VERSION ""

NS_ :

BS_:

BU_: WCM4 WCM3 WCM2 WCM VPM VLM VKM VICM VECM VDM VCU_RTOS_ETH VCU_ENTRY_ETH VCU_AGVM_ETH VCU UVM UPM TIM TEST_TOOL_1 TCP_ETH TCP TCM TCCM SRR_SRR_ETH SRR_SRR SRR_SLR_ETH SRR_SLR SRR_RR SRR_RF_ETH SRR_RF SRR_LR_CR SRR_LF_ETH SRR_LF SIB SDM SCL SBZA_R SBZA_L SBM SAM_RR SAM_RF SAM_LR SAM_LF SAM_BH SADS RadioLow_ETH RadioLow RSI_RTOS_ETH RSI RDCM PTM PLCM PFCM PDR_ETH PDR PCM PA ODS2 ODS NVM MTCM_R MTCM_L MSM_RR MSM_P MSM_LR MSM_D MSB2 MSB1 MRCM_R MRCM_L MFC LRR_RR_ETH LRR_LR_ETH LRR_CF_ETH LRR LRL_CF_ETH LIB_48V LIB1 IPC_INT IPC_GP IPC ICS_Info ICCM HVAC_FP_R HVAC_FP_F HUD_CAN HDLM FPI_RTOS_ETH FPI FOPM FCM_LC FCM EPSb EPS_1 EPSRAb EPSRAa EPS EOCM_HC_Superset EOCM_HCP2 EOCM ELM ECP_X1 ECP_S2 ECP_S ECP_MC ECP_H3 ECP_H2 ECP_H1 ECP_E ECM EBCM DMS DEFC DCM CSM_ETH CSM_AV CSM CGM_OTA_ETH CGM BSM_MH BSM_HEV BSM BCM ARS ARB APA AOS AMP ALC AHS AHL_AFL ADIMb ADIMa ACP2_MCU

BO_ 1444 PDU_9194: 8 CGM
 SG_ TrlrTireLFInrPres : 7|8@0+ (4,0) [0|1020] "kPaG" VCU
 SG_ ArflBsdOnOccpFrtPsCstAvlFlg2 : 8|1@0+ (1,0) [0|1] "" VCU
 SG_ ArflBsdOnOccpFrtPsCstAvlFlg1 : 9|1@0+ (1,0) [0|1] "" VCU
 SG_ TrlrTireLFInrPresSts_Inv : 10|1@0+ (1,0) [0|1] "" VCU
 SG_ TrlrTireLFInrPresSts : 14|4@0+ (1,0) [0|8] "" VCU
 SG_ TrlrTireLFInrPres_Inv : 15|1@0+ (1,0) [0|1] "" VCU
 SG_ ArflBsdOnOccpRrPsCstAvlFlg2 : 16|1@0+ (1,0) [0|1] "" VCU
 SG_ ArflBsdOnOccpRrPsCstAvlFlg1 : 17|1@0+ (1,0) [0|1] "" VCU
 SG_ ArflBsdOnOccpFrtPsCstSetAval : 18|1@0+ (1,0) [0|1] "" VCU
 SG_ ArflBsdOnOccpFrtPsCstAvlFlg7 : 19|1@0+ (1,0) [0|1] "" VCU
 SG_ ArflBsdOnOccpFrtPsCstAvlFlg6 : 20|1@0+ (1,0) [0|1] "" VCU
 SG_ ArflBsdOnOccpFrtPsCstAvlFlg5 : 21|1@0+ (1,0) [0|1] "" VCU
 SG_ ArflBsdOnOccpFrtPsCstAvlFlg4 : 22|1@0+ (1,0) [0|1] "" VCU
 SG_ ArflBsdOnOccpFrtPsCstAvlFlg3 : 23|1@0+ (1,0) [0|1] "" VCU
 SG_ AutoAirOtltAmgCstAvlFlg2 : 24|1@0+ (1,0) [0|1] "" VCU
 SG_ AutoAirOtltAmgCstAvlFlg1 : 25|1@0+ (1,0) [0|1] "" VCU
 SG_ ArflBsdOnOccpRrPsCstSetAval : 26|1@0+ (1,0) [0|1] "" VCU
 SG_ ArflBsdOnOccpRrPsCstAvlFlg7 : 27|1@0+ (1,0) [0|1] "" VCU
 SG_ ArflBsdOnOccpRrPsCstAvlFlg6 : 28|1@0+ (1,0) [0|1] "" VCU
 SG_ ArflBsdOnOccpRrPsCstAvlFlg5 : 29|1@0+ (1,0) [0|1] "" VCU
 SG_ ArflBsdOnOccpRrPsCstAvlFlg4 : 30|1@0+ (1,0) [0|1] "" VCU
 SG_ ArflBsdOnOccpRrPsCstAvlFlg3 : 31|1@0+ (1,0) [0|1] "" VCU
 SG_ AutoNckScrfCstAvlFlg2 : 32|1@0+ (1,0) [0|1] "" VCU
 SG_ AutoNckScrfCstAvlFlg1 : 33|1@0+ (1,0) [0|1] "" VCU
 SG_ AutoAirOtltAmgCstSetAval : 34|1@0+ (1,0) [0|1] "" VCU
 SG_ AutoAirOtltAmgCstAvlFlg7 : 35|1@0+ (1,0) [0|1] "" VCU
 SG_ AutoAirOtltAmgCstAvlFlg6 : 36|1@0+ (1,0) [0|1] "" VCU
 SG_ AutoAirOtltAmgCstAvlFlg5 : 37|1@0+ (1,0) [0|1] "" VCU
 SG_ AutoAirOtltAmgCstAvlFlg4 : 38|1@0+ (1,0) [0|1] "" VCU
 SG_ AutoAirOtltAmgCstAvlFlg3 : 39|1@0+ (1,0) [0|1] "" VCU
 SG_ Aux2AmbtAnmCtlCstAvlFlg10 : 40|1@0+ (1,0) [0|1] "" VCU
 SG_ Aux2AmbtAnmCtlCstAvlFlg1 : 41|1@0+ (1,0) [0|1] "" VCU
 SG_ AutoNckScrfCstSetAval : 42|1@0+ (1,0) [0|1] "" VCU
 SG_ AutoNckScrfCstAvlFlg7 : 43|1@0+ (1,0) [0|1] "" VCU
 SG_ AutoNckScrfCstAvlFlg6 : 44|1@0+ (1,0) [0|1] "" VCU
 SG_ AutoNckScrfCstAvlFlg5 : 45|1@0+ (1,0) [0|1] "" VCU
 SG_ AutoNckScrfCstAvlFlg4 : 46|1@0+ (1,0) [0|1] "" VCU
 SG_ AutoNckScrfCstAvlFlg3 : 47|1@0+ (1,0) [0|1] "" VCU
 SG_ SCAPwrDrLckAllVirtCtlRrAllwd : 48|1@0+ (1,0) [0|1] "" VCU
 SG_ SCAPwrDrLckAllVirtCtlFrtAllwd : 49|1@0+ (1,0) [0|1] "" VCU
 SG_ SCAPwrDrLckAllVirtCtlAval : 50|1@0+ (1,0) [0|1] "" VCU
 SG_ DMHrnOutPrkCstSetAval : 51|1@0+ (1,0) [0|1] "" VCU
 SG_ DMDrvrDrUnlckPrkCstSetAval : 52|1@0+ (1,0) [0|1] "" VCU
 SG_ Aux2AmbtColrCtlCstAvlFlg1 : 53|1@0+ (1,0) [0|1] "" VCU
 SG_ Aux2AmbtAnmCtlCstAvlFlg12 : 54|1@0+ (1,0) [0|1] "" VCU
 SG_ Aux2AmbtAnmCtlCstAvlFlg11 : 55|1@0+ (1,0) [0|1] "" VCU
 SG_ IndThrdRowHVACAuto : 56|1@0+ (1,0) [0|1] "" RadioLow,CSM,CSM_AV,VCU
 SG_ IndRrRtHVACAuto : 57|1@0+ (1,0) [0|1] "" RadioLow,CSM,CSM_AV,VCU
 SG_ IndRrLtHVACAuto : 58|1@0+ (1,0) [0|1] "" RadioLow,CSM,CSM_AV,VCU
 SG_ IndFrtRtHVACAuto : 59|1@0+ (1,0) [0|1] "" RadioLow,CSM,CSM_AV,VCU
 SG_ IndFrtLtHVACAuto : 60|1@0+ (1,0) [0|1] "" RadioLow,CSM,CSM_AV,VCU
 SG_ SCAPwrDrUnlckAllVirtCtlRrAllwd : 61|1@0+ (1,0) [0|1] "" VCU
 SG_ SCAPwrDrUnlckAllVirtCtlFrtAllwd : 62|1@0+ (1,0) [0|1] "" VCU
 SG_ SCAPwrDrUnlckAllVirtCtlAval : 63|1@0+ (1,0) [0|1] "" VCU

BO_ 1924 PDU_9195: 8 CGM
 SG_ Aux2AmbtAnmCtlCstAvlFlg6 : 0|1@0+ (1,0) [0|1] "" VCU
 SG_ Aux2AmbtAnmCtlCstAvlFlg5 : 1|1@0+ (1,0) [0|1] "" VCU
 SG_ Aux2AmbtAnmCtlCstAvlFlg4 : 2|1@0+ (1,0) [0|1] "" VCU
 SG_ Aux2AmbtAnmCtlCstAvlFlg3 : 3|1@0+ (1,0) [0|1] "" VCU
 SG_ Aux2AmbtAnmCtlCstAvlFlg2 : 4|1@0+ (1,0) [0|1] "" VCU
 SG_ Aux2AmbtAnmCtlCstAvlFlg15 : 5|1@0+ (1,0) [0|1] "" VCU
 SG_ Aux2AmbtAnmCtlCstAvlFlg14 : 6|1@0+ (1,0) [0|1] "" VCU
 SG_ Aux2AmbtAnmCtlCstAvlFlg13 : 7|1@0+ (1,0) [0|1] "" VCU
 SG_ Aux2AmbtBrghtnsCtlCstAvlFlg4 : 8|1@0+ (1,0) [0|1] "" VCU
 SG_ Aux2AmbtBrghtnsCtlCstAvlFlg3 : 9|1@0+ (1,0) [0|1] "" VCU
 SG_ Aux2AmbtBrghtnsCtlCstAvlFlg2 : 10|1@0+ (1,0) [0|1] "" VCU
 SG_ Aux2AmbtBrghtnsCtlCstAvlFlg1 : 11|1@0+ (1,0) [0|1] "" VCU
 SG_ Aux2AmbtAnmCtlCstSetAval : 12|1@0+ (1,0) [0|1] "" VCU
 SG_ Aux2AmbtAnmCtlCstAvlFlg9 : 13|1@0+ (1,0) [0|1] "" VCU
 SG_ Aux2AmbtAnmCtlCstAvlFlg8 : 14|1@0+ (1,0) [0|1] "" VCU
 SG_ Aux2AmbtAnmCtlCstAvlFlg7 : 15|1@0+ (1,0) [0|1] "" VCU
 SG_ Aux3AmbtColrCtlCstAvlFlg82 : 16|1@0+ (1,0) [0|1] "" VCU
 SG_ Aux3AmbtColrCtlCstAvlFlg81 : 17|1@0+ (1,0) [0|1] "" VCU
 SG_ Aux3AmbtColrCtlCstAvlFlg80 : 18|1@0+ (1,0) [0|1] "" VCU
 SG_ Aux3AmbtColrCtlCstAvlFlg8 : 19|1@0+ (1,0) [0|1] "" VCU
 SG_ Aux2AmbtBrghtnsCtlCstSetAval : 20|1@0+ (1,0) [0|1] "" VCU
 SG_ Aux2AmbtBrghtnsCtlCstAvlFlg7 : 21|1@0+ (1,0) [0|1] "" VCU
 SG_ Aux2AmbtBrghtnsCtlCstAvlFlg6 : 22|1@0+ (1,0) [0|1] "" VCU
 SG_ Aux2AmbtBrghtnsCtlCstAvlFlg5 : 23|1@0+ (1,0) [0|1] "" VCU
 SG_ Aux3AmbtColrCtlCstAvlFlg9 : 24|1@0+ (1,0) [0|1] "" VCU
 SG_ Aux3AmbtColrCtlCstAvlFlg89 : 25|1@0+ (1,0) [0|1] "" VCU
 SG_ Aux3AmbtColrCtlCstAvlFlg88 : 26|1@0+ (1,0) [0|1] "" VCU
 SG_ Aux3AmbtColrCtlCstAvlFlg87 : 27|1@0+ (1,0) [0|1] "" VCU
 SG_ Aux3AmbtColrCtlCstAvlFlg86 : 28|1@0+ (1,0) [0|1] "" VCU
 SG_ Aux3AmbtColrCtlCstAvlFlg85 : 29|1@0+ (1,0) [0|1] "" VCU
 SG_ Aux3AmbtColrCtlCstAvlFlg84 : 30|1@0+ (1,0) [0|1] "" VCU
 SG_ Aux3AmbtColrCtlCstAvlFlg83 : 31|1@0+ (1,0) [0|1] "" VCU
 SG_ Aux3AmbtColrCtlCstAvlFlg97 : 32|1@0+ (1,0) [0|1] "" VCU
 SG_ Aux3AmbtColrCtlCstAvlFlg96 : 33|1@0+ (1,0) [0|1] "" VCU
 SG_ Aux3AmbtColrCtlCstAvlFlg95 : 34|1@0+ (1,0) [0|1] "" VCU
 SG_ Aux3AmbtColrCtlCstAvlFlg94 : 35|1@0+ (1,0) [0|1] "" VCU
 SG_ Aux3AmbtColrCtlCstAvlFlg93 : 36|1@0+ (1,0) [0|1] "" VCU
 SG_ Aux3AmbtColrCtlCstAvlFlg92 : 37|1@0+ (1,0) [0|1] "" VCU
 SG_ Aux3AmbtColrCtlCstAvlFlg91 : 38|1@0+ (1,0) [0|1] "" VCU
 SG_ Aux3AmbtColrCtlCstAvlFlg90 : 39|1@0+ (1,0) [0|1] "" VCU
 SG_ CbnAirClnFltrtnCstAvlFlg5 : 40|1@0+ (1,0) [0|1] "" VCU
 SG_ CbnAirClnFltrtnCstAvlFlg4 : 41|1@0+ (1,0) [0|1] "" VCU
 SG_ CbnAirClnFltrtnCstAvlFlg3 : 42|1@0+ (1,0) [0|1] "" VCU
 SG_ CbnAirClnFltrtnCstAvlFlg2 : 43|1@0+ (1,0) [0|1] "" VCU
 SG_ CbnAirClnFltrtnCstAvlFlg1 : 44|1@0+ (1,0) [0|1] "" VCU
 SG_ Aux3AmbtColrCtlCstSetAval : 45|1@0+ (1,0) [0|1] "" VCU
 SG_ Aux3AmbtColrCtlCstAvlFlg99 : 46|1@0+ (1,0) [0|1] "" VCU
 SG_ Aux3AmbtColrCtlCstAvlFlg98 : 47|1@0+ (1,0) [0|1] "" VCU
 SG_ HtdArmrstSyncCstAvlFlg5 : 48|1@0+ (1,0) [0|1] "" VCU
 SG_ HtdArmrstSyncCstAvlFlg4 : 49|1@0+ (1,0) [0|1] "" VCU
 SG_ HtdArmrstSyncCstAvlFlg3 : 50|1@0+ (1,0) [0|1] "" VCU
 SG_ HtdArmrstSyncCstAvlFlg2 : 51|1@0+ (1,0) [0|1] "" VCU
 SG_ HtdArmrstSyncCstAvlFlg1 : 52|1@0+ (1,0) [0|1] "" VCU
 SG_ CbnAirClnFltrtnCstSetAval : 53|1@0+ (1,0) [0|1] "" VCU
 SG_ CbnAirClnFltrtnCstAvlFlg7 : 54|1@0+ (1,0) [0|1] "" VCU
 SG_ CbnAirClnFltrtnCstAvlFlg6 : 55|1@0+ (1,0) [0|1] "" VCU
 SG_ TnDrvrSpdLimRmtCstCurrSetVal : 58|3@0+ (1,0) [0|2] "" TCP
 SG_ TnDrvrActvRmtCstCurrSetVal : 61|3@0+ (1,0) [0|2] "" TCP
 SG_ HtdArmrstSyncCstAvlFlg7 : 62|1@0+ (1,0) [0|1] "" VCU
 SG_ HtdArmrstSyncCstAvlFlg6 : 63|1@0+ (1,0) [0|1] "" VCU

BO_ 1925 PDU_9196: 8 CGM
 SG_ Aux2AmbtColrCtlCstAvlFlg106 : 0|1@0+ (1,0) [0|1] "" VCU
 SG_ Aux2AmbtColrCtlCstAvlFlg105 : 1|1@0+ (1,0) [0|1] "" VCU
 SG_ Aux2AmbtColrCtlCstAvlFlg104 : 2|1@0+ (1,0) [0|1] "" VCU
 SG_ Aux2AmbtColrCtlCstAvlFlg103 : 3|1@0+ (1,0) [0|1] "" VCU
 SG_ Aux2AmbtColrCtlCstAvlFlg102 : 4|1@0+ (1,0) [0|1] "" VCU
 SG_ Aux2AmbtColrCtlCstAvlFlg101 : 5|1@0+ (1,0) [0|1] "" VCU
 SG_ Aux2AmbtColrCtlCstAvlFlg100 : 6|1@0+ (1,0) [0|1] "" VCU
 SG_ Aux2AmbtColrCtlCstAvlFlg10 : 7|1@0+ (1,0) [0|1] "" VCU
 SG_ Aux2AmbtColrCtlCstAvlFlg113 : 8|1@0+ (1,0) [0|1] "" VCU
 SG_ Aux2AmbtColrCtlCstAvlFlg112 : 9|1@0+ (1,0) [0|1] "" VCU
 SG_ Aux2AmbtColrCtlCstAvlFlg111 : 10|1@0+ (1,0) [0|1] "" VCU
 SG_ Aux2AmbtColrCtlCstAvlFlg110 : 11|1@0+ (1,0) [0|1] "" VCU
 SG_ Aux2AmbtColrCtlCstAvlFlg11 : 12|1@0+ (1,0) [0|1] "" VCU
 SG_ Aux2AmbtColrCtlCstAvlFlg109 : 13|1@0+ (1,0) [0|1] "" VCU
 SG_ Aux2AmbtColrCtlCstAvlFlg108 : 14|1@0+ (1,0) [0|1] "" VCU
 SG_ Aux2AmbtColrCtlCstAvlFlg107 : 15|1@0+ (1,0) [0|1] "" VCU
 SG_ Aux2AmbtColrCtlCstAvlFlg120 : 16|1@0+ (1,0) [0|1] "" VCU
 SG_ Aux2AmbtColrCtlCstAvlFlg12 : 17|1@0+ (1,0) [0|1] "" VCU
 SG_ Aux2AmbtColrCtlCstAvlFlg119 : 18|1@0+ (1,0) [0|1] "" VCU
 SG_ Aux2AmbtColrCtlCstAvlFlg118 : 19|1@0+ (1,0) [0|1] "" VCU
 SG_ Aux2AmbtColrCtlCstAvlFlg117 : 20|1@0+ (1,0) [0|1] "" VCU
 SG_ Aux2AmbtColrCtlCstAvlFlg116 : 21|1@0+ (1,0) [0|1] "" VCU
 SG_ Aux2AmbtColrCtlCstAvlFlg115 : 22|1@0+ (1,0) [0|1] "" VCU
 SG_ Aux2AmbtColrCtlCstAvlFlg114 : 23|1@0+ (1,0) [0|1] "" VCU
 SG_ Aux2AmbtColrCtlCstAvlFlg13 : 24|1@0+ (1,0) [0|1] "" VCU
 SG_ Aux2AmbtColrCtlCstAvlFlg127 : 25|1@0+ (1,0) [0|1] "" VCU
 SG_ Aux2AmbtColrCtlCstAvlFlg126 : 26|1@0+ (1,0) [0|1] "" VCU
 SG_ Aux2AmbtColrCtlCstAvlFlg125 : 27|1@0+ (1,0) [0|1] "" VCU
 SG_ Aux2AmbtColrCtlCstAvlFlg124 : 28|1@0+ (1,0) [0|1] "" VCU
 SG_ Aux2AmbtColrCtlCstAvlFlg123 : 29|1@0+ (1,0) [0|1] "" VCU
 SG_ Aux2AmbtColrCtlCstAvlFlg122 : 30|1@0+ (1,0) [0|1] "" VCU
 SG_ Aux2AmbtColrCtlCstAvlFlg121 : 31|1@0+ (1,0) [0|1] "" VCU
 SG_ Aux2AmbtColrCtlCstAvlFlg20 : 32|1@0+ (1,0) [0|1] "" VCU
 SG_ Aux2AmbtColrCtlCstAvlFlg2 : 33|1@0+ (1,0) [0|1] "" VCU
 SG_ Aux2AmbtColrCtlCstAvlFlg19 : 34|1@0+ (1,0) [0|1] "" VCU
 SG_ Aux2AmbtColrCtlCstAvlFlg18 : 35|1@0+ (1,0) [0|1] "" VCU
 SG_ Aux2AmbtColrCtlCstAvlFlg17 : 36|1@0+ (1,0) [0|1] "" VCU
 SG_ Aux2AmbtColrCtlCstAvlFlg16 : 37|1@0+ (1,0) [0|1] "" VCU
 SG_ Aux2AmbtColrCtlCstAvlFlg15 : 38|1@0+ (1,0) [0|1] "" VCU
 SG_ Aux2AmbtColrCtlCstAvlFlg14 : 39|1@0+ (1,0) [0|1] "" VCU
 SG_ Aux2AmbtColrCtlCstAvlFlg28 : 40|1@0+ (1,0) [0|1] "" VCU
 SG_ Aux2AmbtColrCtlCstAvlFlg27 : 41|1@0+ (1,0) [0|1] "" VCU
 SG_ Aux2AmbtColrCtlCstAvlFlg26 : 42|1@0+ (1,0) [0|1] "" VCU
 SG_ Aux2AmbtColrCtlCstAvlFlg25 : 43|1@0+ (1,0) [0|1] "" VCU
 SG_ Aux2AmbtColrCtlCstAvlFlg24 : 44|1@0+ (1,0) [0|1] "" VCU
 SG_ Aux2AmbtColrCtlCstAvlFlg23 : 45|1@0+ (1,0) [0|1] "" VCU
 SG_ Aux2AmbtColrCtlCstAvlFlg22 : 46|1@0+ (1,0) [0|1] "" VCU
 SG_ Aux2AmbtColrCtlCstAvlFlg21 : 47|1@0+ (1,0) [0|1] "" VCU
 SG_ Aux2AmbtColrCtlCstAvlFlg35 : 48|1@0+ (1,0) [0|1] "" VCU
 SG_ Aux2AmbtColrCtlCstAvlFlg34 : 49|1@0+ (1,0) [0|1] "" VCU
 SG_ Aux2AmbtColrCtlCstAvlFlg33 : 50|1@0+ (1,0) [0|1] "" VCU
 SG_ Aux2AmbtColrCtlCstAvlFlg32 : 51|1@0+ (1,0) [0|1] "" VCU
 SG_ Aux2AmbtColrCtlCstAvlFlg31 : 52|1@0+ (1,0) [0|1] "" VCU
 SG_ Aux2AmbtColrCtlCstAvlFlg30 : 53|1@0+ (1,0) [0|1] "" VCU
 SG_ Aux2AmbtColrCtlCstAvlFlg3 : 54|1@0+ (1,0) [0|1] "" VCU
 SG_ Aux2AmbtColrCtlCstAvlFlg29 : 55|1@0+ (1,0) [0|1] "" VCU
 SG_ Aux2AmbtColrCtlCstAvlFlg42 : 56|1@0+ (1,0) [0|1] "" VCU
 SG_ Aux2AmbtColrCtlCstAvlFlg41 : 57|1@0+ (1,0) [0|1] "" VCU
 SG_ Aux2AmbtColrCtlCstAvlFlg40 : 58|1@0+ (1,0) [0|1] "" VCU
 SG_ Aux2AmbtColrCtlCstAvlFlg4 : 59|1@0+ (1,0) [0|1] "" VCU
 SG_ Aux2AmbtColrCtlCstAvlFlg39 : 60|1@0+ (1,0) [0|1] "" VCU
 SG_ Aux2AmbtColrCtlCstAvlFlg38 : 61|1@0+ (1,0) [0|1] "" VCU
 SG_ Aux2AmbtColrCtlCstAvlFlg37 : 62|1@0+ (1,0) [0|1] "" VCU
 SG_ Aux2AmbtColrCtlCstAvlFlg36 : 63|1@0+ (1,0) [0|1] "" VCU

BO_ 1926 PDU_9197: 8 CGM
 SG_ Aux2AmbtColrCtlCstAvlFlg5 : 0|1@0+ (1,0) [0|1] "" VCU
 SG_ Aux2AmbtColrCtlCstAvlFlg49 : 1|1@0+ (1,0) [0|1] "" VCU
 SG_ Aux2AmbtColrCtlCstAvlFlg48 : 2|1@0+ (1,0) [0|1] "" VCU
 SG_ Aux2AmbtColrCtlCstAvlFlg47 : 3|1@0+ (1,0) [0|1] "" VCU
 SG_ Aux2AmbtColrCtlCstAvlFlg46 : 4|1@0+ (1,0) [0|1] "" VCU
 SG_ Aux2AmbtColrCtlCstAvlFlg45 : 5|1@0+ (1,0) [0|1] "" VCU
 SG_ Aux2AmbtColrCtlCstAvlFlg44 : 6|1@0+ (1,0) [0|1] "" VCU
 SG_ Aux2AmbtColrCtlCstAvlFlg43 : 7|1@0+ (1,0) [0|1] "" VCU
 SG_ Aux2AmbtColrCtlCstAvlFlg57 : 8|1@0+ (1,0) [0|1] "" VCU
 SG_ Aux2AmbtColrCtlCstAvlFlg56 : 9|1@0+ (1,0) [0|1] "" VCU
 SG_ Aux2AmbtColrCtlCstAvlFlg55 : 10|1@0+ (1,0) [0|1] "" VCU
 SG_ Aux2AmbtColrCtlCstAvlFlg54 : 11|1@0+ (1,0) [0|1] "" VCU
 SG_ Aux2AmbtColrCtlCstAvlFlg53 : 12|1@0+ (1,0) [0|1] "" VCU
 SG_ Aux2AmbtColrCtlCstAvlFlg52 : 13|1@0+ (1,0) [0|1] "" VCU
 SG_ Aux2AmbtColrCtlCstAvlFlg51 : 14|1@0+ (1,0) [0|1] "" VCU
 SG_ Aux2AmbtColrCtlCstAvlFlg50 : 15|1@0+ (1,0) [0|1] "" VCU
 SG_ Aux2AmbtColrCtlCstAvlFlg64 : 16|1@0+ (1,0) [0|1] "" VCU
 SG_ Aux2AmbtColrCtlCstAvlFlg63 : 17|1@0+ (1,0) [0|1] "" VCU
 SG_ Aux2AmbtColrCtlCstAvlFlg62 : 18|1@0+ (1,0) [0|1] "" VCU
 SG_ Aux2AmbtColrCtlCstAvlFlg61 : 19|1@0+ (1,0) [0|1] "" VCU
 SG_ Aux2AmbtColrCtlCstAvlFlg60 : 20|1@0+ (1,0) [0|1] "" VCU
 SG_ Aux2AmbtColrCtlCstAvlFlg6 : 21|1@0+ (1,0) [0|1] "" VCU
 SG_ Aux2AmbtColrCtlCstAvlFlg59 : 22|1@0+ (1,0) [0|1] "" VCU
 SG_ Aux2AmbtColrCtlCstAvlFlg58 : 23|1@0+ (1,0) [0|1] "" VCU
 SG_ Aux2AmbtColrCtlCstAvlFlg71 : 24|1@0+ (1,0) [0|1] "" VCU
 SG_ Aux2AmbtColrCtlCstAvlFlg70 : 25|1@0+ (1,0) [0|1] "" VCU
 SG_ Aux2AmbtColrCtlCstAvlFlg7 : 26|1@0+ (1,0) [0|1] "" VCU
 SG_ Aux2AmbtColrCtlCstAvlFlg69 : 27|1@0+ (1,0) [0|1] "" VCU
 SG_ Aux2AmbtColrCtlCstAvlFlg68 : 28|1@0+ (1,0) [0|1] "" VCU
 SG_ Aux2AmbtColrCtlCstAvlFlg67 : 29|1@0+ (1,0) [0|1] "" VCU
 SG_ Aux2AmbtColrCtlCstAvlFlg66 : 30|1@0+ (1,0) [0|1] "" VCU
 SG_ Aux2AmbtColrCtlCstAvlFlg65 : 31|1@0+ (1,0) [0|1] "" VCU
 SG_ Aux2AmbtColrCtlCstAvlFlg79 : 32|1@0+ (1,0) [0|1] "" VCU
 SG_ Aux2AmbtColrCtlCstAvlFlg78 : 33|1@0+ (1,0) [0|1] "" VCU
 SG_ Aux2AmbtColrCtlCstAvlFlg77 : 34|1@0+ (1,0) [0|1] "" VCU
 SG_ Aux2AmbtColrCtlCstAvlFlg76 : 35|1@0+ (1,0) [0|1] "" VCU
 SG_ Aux2AmbtColrCtlCstAvlFlg75 : 36|1@0+ (1,0) [0|1] "" VCU
 SG_ Aux2AmbtColrCtlCstAvlFlg74 : 37|1@0+ (1,0) [0|1] "" VCU
 SG_ Aux2AmbtColrCtlCstAvlFlg73 : 38|1@0+ (1,0) [0|1] "" VCU
 SG_ Aux2AmbtColrCtlCstAvlFlg72 : 39|1@0+ (1,0) [0|1] "" VCU
 SG_ Aux2AmbtColrCtlCstAvlFlg86 : 40|1@0+ (1,0) [0|1] "" VCU
 SG_ Aux2AmbtColrCtlCstAvlFlg85 : 41|1@0+ (1,0) [0|1] "" VCU
 SG_ Aux2AmbtColrCtlCstAvlFlg84 : 42|1@0+ (1,0) [0|1] "" VCU
 SG_ Aux2AmbtColrCtlCstAvlFlg83 : 43|1@0+ (1,0) [0|1] "" VCU
 SG_ Aux2AmbtColrCtlCstAvlFlg82 : 44|1@0+ (1,0) [0|1] "" VCU
 SG_ Aux2AmbtColrCtlCstAvlFlg81 : 45|1@0+ (1,0) [0|1] "" VCU
 SG_ Aux2AmbtColrCtlCstAvlFlg80 : 46|1@0+ (1,0) [0|1] "" VCU
 SG_ Aux2AmbtColrCtlCstAvlFlg8 : 47|1@0+ (1,0) [0|1] "" VCU
 SG_ Aux2AmbtColrCtlCstAvlFlg93 : 48|1@0+ (1,0) [0|1] "" VCU
 SG_ Aux2AmbtColrCtlCstAvlFlg92 : 49|1@0+ (1,0) [0|1] "" VCU
 SG_ Aux2AmbtColrCtlCstAvlFlg91 : 50|1@0+ (1,0) [0|1] "" VCU
 SG_ Aux2AmbtColrCtlCstAvlFlg90 : 51|1@0+ (1,0) [0|1] "" VCU
 SG_ Aux2AmbtColrCtlCstAvlFlg9 : 52|1@0+ (1,0) [0|1] "" VCU
 SG_ Aux2AmbtColrCtlCstAvlFlg89 : 53|1@0+ (1,0) [0|1] "" VCU
 SG_ Aux2AmbtColrCtlCstAvlFlg88 : 54|1@0+ (1,0) [0|1] "" VCU
 SG_ Aux2AmbtColrCtlCstAvlFlg87 : 55|1@0+ (1,0) [0|1] "" VCU
 SG_ Aux3AmbtAnmCtlCstAvlFlg1 : 56|1@0+ (1,0) [0|1] "" VCU
 SG_ Aux2AmbtColrCtlCstSetAval : 57|1@0+ (1,0) [0|1] "" VCU
 SG_ Aux2AmbtColrCtlCstAvlFlg99 : 58|1@0+ (1,0) [0|1] "" VCU
 SG_ Aux2AmbtColrCtlCstAvlFlg98 : 59|1@0+ (1,0) [0|1] "" VCU
 SG_ Aux2AmbtColrCtlCstAvlFlg97 : 60|1@0+ (1,0) [0|1] "" VCU
 SG_ Aux2AmbtColrCtlCstAvlFlg96 : 61|1@0+ (1,0) [0|1] "" VCU
 SG_ Aux2AmbtColrCtlCstAvlFlg95 : 62|1@0+ (1,0) [0|1] "" VCU
 SG_ Aux2AmbtColrCtlCstAvlFlg94 : 63|1@0+ (1,0) [0|1] "" VCU

BO_ 1132 PDU_9198: 8 CGM
 SG_ Aux3AmbtAnmCtlCstAvlFlg3 : 0|1@0+ (1,0) [0|1] "" VCU
 SG_ Aux3AmbtAnmCtlCstAvlFlg2 : 1|1@0+ (1,0) [0|1] "" VCU
 SG_ Aux3AmbtAnmCtlCstAvlFlg15 : 2|1@0+ (1,0) [0|1] "" VCU
 SG_ Aux3AmbtAnmCtlCstAvlFlg14 : 3|1@0+ (1,0) [0|1] "" VCU
 SG_ Aux3AmbtAnmCtlCstAvlFlg13 : 4|1@0+ (1,0) [0|1] "" VCU
 SG_ Aux3AmbtAnmCtlCstAvlFlg12 : 5|1@0+ (1,0) [0|1] "" VCU
 SG_ Aux3AmbtAnmCtlCstAvlFlg11 : 6|1@0+ (1,0) [0|1] "" VCU
 SG_ Aux3AmbtAnmCtlCstAvlFlg10 : 7|1@0+ (1,0) [0|1] "" VCU
 SG_ Aux3AmbtBrghtnsCtlCstAvlFlg1 : 8|1@0+ (1,0) [0|1] "" VCU
 SG_ Aux3AmbtAnmCtlCstSetAval : 9|1@0+ (1,0) [0|1] "" VCU
 SG_ Aux3AmbtAnmCtlCstAvlFlg9 : 10|1@0+ (1,0) [0|1] "" VCU
 SG_ Aux3AmbtAnmCtlCstAvlFlg8 : 11|1@0+ (1,0) [0|1] "" VCU
 SG_ Aux3AmbtAnmCtlCstAvlFlg7 : 12|1@0+ (1,0) [0|1] "" VCU
 SG_ Aux3AmbtAnmCtlCstAvlFlg6 : 13|1@0+ (1,0) [0|1] "" VCU
 SG_ Aux3AmbtAnmCtlCstAvlFlg5 : 14|1@0+ (1,0) [0|1] "" VCU
 SG_ Aux3AmbtAnmCtlCstAvlFlg4 : 15|1@0+ (1,0) [0|1] "" VCU
 SG_ Aux3AmbtColrCtlCstAvlFlg1 : 16|1@0+ (1,0) [0|1] "" VCU
 SG_ Aux3AmbtBrghtnsCtlCstSetAval : 17|1@0+ (1,0) [0|1] "" VCU
 SG_ Aux3AmbtBrghtnsCtlCstAvlFlg7 : 18|1@0+ (1,0) [0|1] "" VCU
 SG_ Aux3AmbtBrghtnsCtlCstAvlFlg6 : 19|1@0+ (1,0) [0|1] "" VCU
 SG_ Aux3AmbtBrghtnsCtlCstAvlFlg5 : 20|1@0+ (1,0) [0|1] "" VCU
 SG_ Aux3AmbtBrghtnsCtlCstAvlFlg4 : 21|1@0+ (1,0) [0|1] "" VCU
 SG_ Aux3AmbtBrghtnsCtlCstAvlFlg3 : 22|1@0+ (1,0) [0|1] "" VCU
 SG_ Aux3AmbtBrghtnsCtlCstAvlFlg2 : 23|1@0+ (1,0) [0|1] "" VCU
 SG_ Aux3AmbtColrCtlCstAvlFlg106 : 24|1@0+ (1,0) [0|1] "" VCU
 SG_ Aux3AmbtColrCtlCstAvlFlg105 : 25|1@0+ (1,0) [0|1] "" VCU
 SG_ Aux3AmbtColrCtlCstAvlFlg104 : 26|1@0+ (1,0) [0|1] "" VCU
 SG_ Aux3AmbtColrCtlCstAvlFlg103 : 27|1@0+ (1,0) [0|1] "" VCU
 SG_ Aux3AmbtColrCtlCstAvlFlg102 : 28|1@0+ (1,0) [0|1] "" VCU
 SG_ Aux3AmbtColrCtlCstAvlFlg101 : 29|1@0+ (1,0) [0|1] "" VCU
 SG_ Aux3AmbtColrCtlCstAvlFlg100 : 30|1@0+ (1,0) [0|1] "" VCU
 SG_ Aux3AmbtColrCtlCstAvlFlg10 : 31|1@0+ (1,0) [0|1] "" VCU
 SG_ Aux3AmbtColrCtlCstAvlFlg113 : 32|1@0+ (1,0) [0|1] "" VCU
 SG_ Aux3AmbtColrCtlCstAvlFlg112 : 33|1@0+ (1,0) [0|1] "" VCU
 SG_ Aux3AmbtColrCtlCstAvlFlg111 : 34|1@0+ (1,0) [0|1] "" VCU
 SG_ Aux3AmbtColrCtlCstAvlFlg110 : 35|1@0+ (1,0) [0|1] "" VCU
 SG_ Aux3AmbtColrCtlCstAvlFlg11 : 36|1@0+ (1,0) [0|1] "" VCU
 SG_ Aux3AmbtColrCtlCstAvlFlg109 : 37|1@0+ (1,0) [0|1] "" VCU
 SG_ Aux3AmbtColrCtlCstAvlFlg108 : 38|1@0+ (1,0) [0|1] "" VCU
 SG_ Aux3AmbtColrCtlCstAvlFlg107 : 39|1@0+ (1,0) [0|1] "" VCU
 SG_ Aux3AmbtColrCtlCstAvlFlg120 : 40|1@0+ (1,0) [0|1] "" VCU
 SG_ Aux3AmbtColrCtlCstAvlFlg12 : 41|1@0+ (1,0) [0|1] "" VCU
 SG_ Aux3AmbtColrCtlCstAvlFlg119 : 42|1@0+ (1,0) [0|1] "" VCU
 SG_ Aux3AmbtColrCtlCstAvlFlg118 : 43|1@0+ (1,0) [0|1] "" VCU
 SG_ Aux3AmbtColrCtlCstAvlFlg117 : 44|1@0+ (1,0) [0|1] "" VCU
 SG_ Aux3AmbtColrCtlCstAvlFlg116 : 45|1@0+ (1,0) [0|1] "" VCU
 SG_ Aux3AmbtColrCtlCstAvlFlg115 : 46|1@0+ (1,0) [0|1] "" VCU
 SG_ Aux3AmbtColrCtlCstAvlFlg114 : 47|1@0+ (1,0) [0|1] "" VCU
 SG_ Aux3AmbtColrCtlCstAvlFlg13 : 48|1@0+ (1,0) [0|1] "" VCU
 SG_ Aux3AmbtColrCtlCstAvlFlg127 : 49|1@0+ (1,0) [0|1] "" VCU
 SG_ Aux3AmbtColrCtlCstAvlFlg126 : 50|1@0+ (1,0) [0|1] "" VCU
 SG_ Aux3AmbtColrCtlCstAvlFlg125 : 51|1@0+ (1,0) [0|1] "" VCU
 SG_ Aux3AmbtColrCtlCstAvlFlg124 : 52|1@0+ (1,0) [0|1] "" VCU
 SG_ Aux3AmbtColrCtlCstAvlFlg123 : 53|1@0+ (1,0) [0|1] "" VCU
 SG_ Aux3AmbtColrCtlCstAvlFlg122 : 54|1@0+ (1,0) [0|1] "" VCU
 SG_ Aux3AmbtColrCtlCstAvlFlg121 : 55|1@0+ (1,0) [0|1] "" VCU
 SG_ Aux3AmbtColrCtlCstAvlFlg20 : 56|1@0+ (1,0) [0|1] "" VCU
 SG_ Aux3AmbtColrCtlCstAvlFlg2 : 57|1@0+ (1,0) [0|1] "" VCU
 SG_ Aux3AmbtColrCtlCstAvlFlg19 : 58|1@0+ (1,0) [0|1] "" VCU
 SG_ Aux3AmbtColrCtlCstAvlFlg18 : 59|1@0+ (1,0) [0|1] "" VCU
 SG_ Aux3AmbtColrCtlCstAvlFlg17 : 60|1@0+ (1,0) [0|1] "" VCU
 SG_ Aux3AmbtColrCtlCstAvlFlg16 : 61|1@0+ (1,0) [0|1] "" VCU
 SG_ Aux3AmbtColrCtlCstAvlFlg15 : 62|1@0+ (1,0) [0|1] "" VCU
 SG_ Aux3AmbtColrCtlCstAvlFlg14 : 63|1@0+ (1,0) [0|1] "" VCU

BO_ 1935 PDU_9199: 8 CGM
 SG_ Aux3AmbtColrCtlCstAvlFlg28 : 0|1@0+ (1,0) [0|1] "" VCU
 SG_ Aux3AmbtColrCtlCstAvlFlg27 : 1|1@0+ (1,0) [0|1] "" VCU
 SG_ Aux3AmbtColrCtlCstAvlFlg26 : 2|1@0+ (1,0) [0|1] "" VCU
 SG_ Aux3AmbtColrCtlCstAvlFlg25 : 3|1@0+ (1,0) [0|1] "" VCU
 SG_ Aux3AmbtColrCtlCstAvlFlg24 : 4|1@0+ (1,0) [0|1] "" VCU
 SG_ Aux3AmbtColrCtlCstAvlFlg23 : 5|1@0+ (1,0) [0|1] "" VCU
 SG_ Aux3AmbtColrCtlCstAvlFlg22 : 6|1@0+ (1,0) [0|1] "" VCU
 SG_ Aux3AmbtColrCtlCstAvlFlg21 : 7|1@0+ (1,0) [0|1] "" VCU
 SG_ Aux3AmbtColrCtlCstAvlFlg35 : 8|1@0+ (1,0) [0|1] "" VCU
 SG_ Aux3AmbtColrCtlCstAvlFlg34 : 9|1@0+ (1,0) [0|1] "" VCU
 SG_ Aux3AmbtColrCtlCstAvlFlg33 : 10|1@0+ (1,0) [0|1] "" VCU
 SG_ Aux3AmbtColrCtlCstAvlFlg32 : 11|1@0+ (1,0) [0|1] "" VCU
 SG_ Aux3AmbtColrCtlCstAvlFlg31 : 12|1@0+ (1,0) [0|1] "" VCU
 SG_ Aux3AmbtColrCtlCstAvlFlg30 : 13|1@0+ (1,0) [0|1] "" VCU
 SG_ Aux3AmbtColrCtlCstAvlFlg3 : 14|1@0+ (1,0) [0|1] "" VCU
 SG_ Aux3AmbtColrCtlCstAvlFlg29 : 15|1@0+ (1,0) [0|1] "" VCU
 SG_ Aux3AmbtColrCtlCstAvlFlg42 : 16|1@0+ (1,0) [0|1] "" VCU
 SG_ Aux3AmbtColrCtlCstAvlFlg41 : 17|1@0+ (1,0) [0|1] "" VCU
 SG_ Aux3AmbtColrCtlCstAvlFlg40 : 18|1@0+ (1,0) [0|1] "" VCU
 SG_ Aux3AmbtColrCtlCstAvlFlg4 : 19|1@0+ (1,0) [0|1] "" VCU
 SG_ Aux3AmbtColrCtlCstAvlFlg39 : 20|1@0+ (1,0) [0|1] "" VCU
 SG_ Aux3AmbtColrCtlCstAvlFlg38 : 21|1@0+ (1,0) [0|1] "" VCU
 SG_ Aux3AmbtColrCtlCstAvlFlg37 : 22|1@0+ (1,0) [0|1] "" VCU
 SG_ Aux3AmbtColrCtlCstAvlFlg36 : 23|1@0+ (1,0) [0|1] "" VCU
 SG_ Aux3AmbtColrCtlCstAvlFlg5 : 24|1@0+ (1,0) [0|1] "" VCU
 SG_ Aux3AmbtColrCtlCstAvlFlg49 : 25|1@0+ (1,0) [0|1] "" VCU
 SG_ Aux3AmbtColrCtlCstAvlFlg48 : 26|1@0+ (1,0) [0|1] "" VCU
 SG_ Aux3AmbtColrCtlCstAvlFlg47 : 27|1@0+ (1,0) [0|1] "" VCU
 SG_ Aux3AmbtColrCtlCstAvlFlg46 : 28|1@0+ (1,0) [0|1] "" VCU
 SG_ Aux3AmbtColrCtlCstAvlFlg45 : 29|1@0+ (1,0) [0|1] "" VCU
 SG_ Aux3AmbtColrCtlCstAvlFlg44 : 30|1@0+ (1,0) [0|1] "" VCU
 SG_ Aux3AmbtColrCtlCstAvlFlg43 : 31|1@0+ (1,0) [0|1] "" VCU
 SG_ Aux3AmbtColrCtlCstAvlFlg57 : 32|1@0+ (1,0) [0|1] "" VCU
 SG_ Aux3AmbtColrCtlCstAvlFlg56 : 33|1@0+ (1,0) [0|1] "" VCU
 SG_ Aux3AmbtColrCtlCstAvlFlg55 : 34|1@0+ (1,0) [0|1] "" VCU
 SG_ Aux3AmbtColrCtlCstAvlFlg54 : 35|1@0+ (1,0) [0|1] "" VCU
 SG_ Aux3AmbtColrCtlCstAvlFlg53 : 36|1@0+ (1,0) [0|1] "" VCU
 SG_ Aux3AmbtColrCtlCstAvlFlg52 : 37|1@0+ (1,0) [0|1] "" VCU
 SG_ Aux3AmbtColrCtlCstAvlFlg51 : 38|1@0+ (1,0) [0|1] "" VCU
 SG_ Aux3AmbtColrCtlCstAvlFlg50 : 39|1@0+ (1,0) [0|1] "" VCU
 SG_ Aux3AmbtColrCtlCstAvlFlg64 : 40|1@0+ (1,0) [0|1] "" VCU
 SG_ Aux3AmbtColrCtlCstAvlFlg63 : 41|1@0+ (1,0) [0|1] "" VCU
 SG_ Aux3AmbtColrCtlCstAvlFlg62 : 42|1@0+ (1,0) [0|1] "" VCU
 SG_ Aux3AmbtColrCtlCstAvlFlg61 : 43|1@0+ (1,0) [0|1] "" VCU
 SG_ Aux3AmbtColrCtlCstAvlFlg60 : 44|1@0+ (1,0) [0|1] "" VCU
 SG_ Aux3AmbtColrCtlCstAvlFlg6 : 45|1@0+ (1,0) [0|1] "" VCU
 SG_ Aux3AmbtColrCtlCstAvlFlg59 : 46|1@0+ (1,0) [0|1] "" VCU
 SG_ Aux3AmbtColrCtlCstAvlFlg58 : 47|1@0+ (1,0) [0|1] "" VCU
 SG_ Aux3AmbtColrCtlCstAvlFlg71 : 48|1@0+ (1,0) [0|1] "" VCU
 SG_ Aux3AmbtColrCtlCstAvlFlg70 : 49|1@0+ (1,0) [0|1] "" VCU
 SG_ Aux3AmbtColrCtlCstAvlFlg7 : 50|1@0+ (1,0) [0|1] "" VCU
 SG_ Aux3AmbtColrCtlCstAvlFlg69 : 51|1@0+ (1,0) [0|1] "" VCU
 SG_ Aux3AmbtColrCtlCstAvlFlg68 : 52|1@0+ (1,0) [0|1] "" VCU
 SG_ Aux3AmbtColrCtlCstAvlFlg67 : 53|1@0+ (1,0) [0|1] "" VCU
 SG_ Aux3AmbtColrCtlCstAvlFlg66 : 54|1@0+ (1,0) [0|1] "" VCU
 SG_ Aux3AmbtColrCtlCstAvlFlg65 : 55|1@0+ (1,0) [0|1] "" VCU
 SG_ Aux3AmbtColrCtlCstAvlFlg79 : 56|1@0+ (1,0) [0|1] "" VCU
 SG_ Aux3AmbtColrCtlCstAvlFlg78 : 57|1@0+ (1,0) [0|1] "" VCU
 SG_ Aux3AmbtColrCtlCstAvlFlg77 : 58|1@0+ (1,0) [0|1] "" VCU
 SG_ Aux3AmbtColrCtlCstAvlFlg76 : 59|1@0+ (1,0) [0|1] "" VCU
 SG_ Aux3AmbtColrCtlCstAvlFlg75 : 60|1@0+ (1,0) [0|1] "" VCU
 SG_ Aux3AmbtColrCtlCstAvlFlg74 : 61|1@0+ (1,0) [0|1] "" VCU
 SG_ Aux3AmbtColrCtlCstAvlFlg73 : 62|1@0+ (1,0) [0|1] "" VCU
 SG_ Aux3AmbtColrCtlCstAvlFlg72 : 63|1@0+ (1,0) [0|1] "" VCU

BO_ 1952 PDU_9200: 8 CGM
 SG_ DMCabLgtPrkCstCurrSetVal : 1|3@0+ (1,0) [0|2] "" VCU
 SG_ DMBlkhdDrUnltchPrkCstCurrSetVal : 4|3@0+ (1,0) [0|2] "" VCU
 SG_ DMBlkhdDrUnlckPrkCstCurrSetVal : 7|3@0+ (1,0) [0|2] "" VCU
 SG_ DMHrnOutPrkCstCurrSetVal : 8|3@0+ (1,0) [0|2] "" VCU
 SG_ DMDrvrDrUnlckPrkCstCurrSetVal : 11|3@0+ (1,0) [0|2] "" VCU
 SG_ DMCrbsdDrUnlckPrkCstCurrSetVal : 14|3@0+ (1,0) [0|2] "" VCU
 SG_ DMBlkhdDrUnlckPrkCstAvlFlg6 : 16|1@0+ (1,0) [0|1] "" VCU
 SG_ DMBlkhdDrUnlckPrkCstAvlFlg5 : 17|1@0+ (1,0) [0|1] "" VCU
 SG_ DMBlkhdDrUnlckPrkCstAvlFlg4 : 18|1@0+ (1,0) [0|1] "" VCU
 SG_ DMBlkhdDrUnlckPrkCstAvlFlg3 : 19|1@0+ (1,0) [0|1] "" VCU
 SG_ DMBlkhdDrUnlckPrkCstAvlFlg2 : 20|1@0+ (1,0) [0|1] "" VCU
 SG_ DMBlkhdDrUnlckPrkCstAvlFlg1 : 21|1@0+ (1,0) [0|1] "" VCU
 SG_ DMBlkhdDrUnltchPrkCstAvlFlg6 : 24|1@0+ (1,0) [0|1] "" VCU
 SG_ DMBlkhdDrUnltchPrkCstAvlFlg5 : 25|1@0+ (1,0) [0|1] "" VCU
 SG_ DMBlkhdDrUnltchPrkCstAvlFlg4 : 26|1@0+ (1,0) [0|1] "" VCU
 SG_ DMBlkhdDrUnltchPrkCstAvlFlg3 : 27|1@0+ (1,0) [0|1] "" VCU
 SG_ DMBlkhdDrUnltchPrkCstAvlFlg2 : 28|1@0+ (1,0) [0|1] "" VCU
 SG_ DMBlkhdDrUnltchPrkCstAvlFlg1 : 29|1@0+ (1,0) [0|1] "" VCU
 SG_ DMBlkhdDrUnlckPrkCstSetAval : 30|1@0+ (1,0) [0|1] "" VCU
 SG_ DMBlkhdDrUnlckPrkCstAvlFlg7 : 31|1@0+ (1,0) [0|1] "" VCU
 SG_ DMCabLgtPrkCstAvlFlg6 : 32|1@0+ (1,0) [0|1] "" VCU
 SG_ DMCabLgtPrkCstAvlFlg5 : 33|1@0+ (1,0) [0|1] "" VCU
 SG_ DMCabLgtPrkCstAvlFlg4 : 34|1@0+ (1,0) [0|1] "" VCU
 SG_ DMCabLgtPrkCstAvlFlg3 : 35|1@0+ (1,0) [0|1] "" VCU
 SG_ DMCabLgtPrkCstAvlFlg2 : 36|1@0+ (1,0) [0|1] "" VCU
 SG_ DMCabLgtPrkCstAvlFlg1 : 37|1@0+ (1,0) [0|1] "" VCU
 SG_ DMBlkhdDrUnltchPrkCstSetAval : 38|1@0+ (1,0) [0|1] "" VCU
 SG_ DMBlkhdDrUnltchPrkCstAvlFlg7 : 39|1@0+ (1,0) [0|1] "" VCU
 SG_ DMCrbsdDrUnlckPrkCstAvlFlg6 : 40|1@0+ (1,0) [0|1] "" VCU
 SG_ DMCrbsdDrUnlckPrkCstAvlFlg5 : 41|1@0+ (1,0) [0|1] "" VCU
 SG_ DMCrbsdDrUnlckPrkCstAvlFlg4 : 42|1@0+ (1,0) [0|1] "" VCU
 SG_ DMCrbsdDrUnlckPrkCstAvlFlg3 : 43|1@0+ (1,0) [0|1] "" VCU
 SG_ DMCrbsdDrUnlckPrkCstAvlFlg2 : 44|1@0+ (1,0) [0|1] "" VCU
 SG_ DMCrbsdDrUnlckPrkCstAvlFlg1 : 45|1@0+ (1,0) [0|1] "" VCU
 SG_ DMCabLgtPrkCstSetAval : 46|1@0+ (1,0) [0|1] "" VCU
 SG_ DMCabLgtPrkCstAvlFlg7 : 47|1@0+ (1,0) [0|1] "" VCU
 SG_ DMDrvrDrUnlckPrkCstAvlFlg6 : 48|1@0+ (1,0) [0|1] "" VCU
 SG_ DMDrvrDrUnlckPrkCstAvlFlg5 : 49|1@0+ (1,0) [0|1] "" VCU
 SG_ DMDrvrDrUnlckPrkCstAvlFlg4 : 50|1@0+ (1,0) [0|1] "" VCU
 SG_ DMDrvrDrUnlckPrkCstAvlFlg3 : 51|1@0+ (1,0) [0|1] "" VCU
 SG_ DMDrvrDrUnlckPrkCstAvlFlg2 : 52|1@0+ (1,0) [0|1] "" VCU
 SG_ DMDrvrDrUnlckPrkCstAvlFlg1 : 53|1@0+ (1,0) [0|1] "" VCU
 SG_ DMCrbsdDrUnlckPrkCstSetAval : 54|1@0+ (1,0) [0|1] "" VCU
 SG_ DMCrbsdDrUnlckPrkCstAvlFlg7 : 55|1@0+ (1,0) [0|1] "" VCU
 SG_ DMHrnOutPrkCstAvlFlg7 : 56|1@0+ (1,0) [0|1] "" VCU
 SG_ DMHrnOutPrkCstAvlFlg6 : 57|1@0+ (1,0) [0|1] "" VCU
 SG_ DMHrnOutPrkCstAvlFlg5 : 58|1@0+ (1,0) [0|1] "" VCU
 SG_ DMHrnOutPrkCstAvlFlg4 : 59|1@0+ (1,0) [0|1] "" VCU
 SG_ DMHrnOutPrkCstAvlFlg3 : 60|1@0+ (1,0) [0|1] "" VCU
 SG_ DMHrnOutPrkCstAvlFlg2 : 61|1@0+ (1,0) [0|1] "" VCU
 SG_ DMHrnOutPrkCstAvlFlg1 : 62|1@0+ (1,0) [0|1] "" VCU
 SG_ DMDrvrDrUnlckPrkCstAvlFlg7 : 63|1@0+ (1,0) [0|1] "" VCU

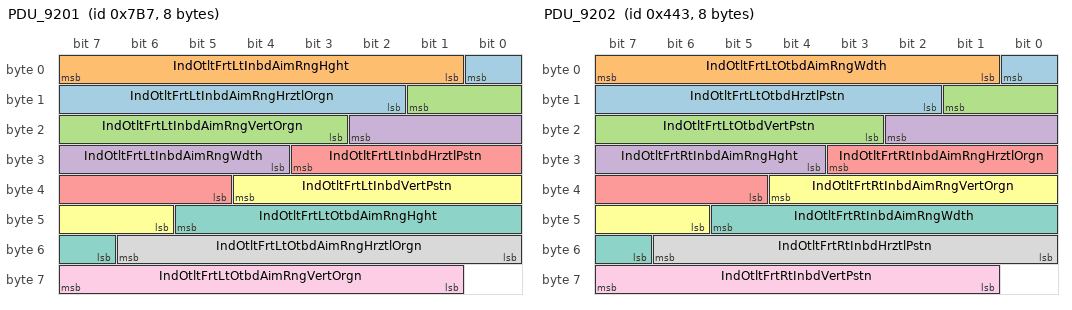
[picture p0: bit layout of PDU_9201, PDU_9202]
BO_ 1975 PDU_9201: 8 CGM
 SG_ IndOtltFrtLtInbdAimRngHrztlOrgn : 0|7@0+ (1,0) [0|127] "%" VCU
 SG_ IndOtltFrtLtInbdAimRngHght : 7|7@0+ (1,0) [0|127] "%" VCU
 SG_ IndOtltFrtLtInbdAimRngVertOrgn : 9|7@0+ (1,0) [0|127] "%" VCU
 SG_ IndOtltFrtLtInbdAimRngWdth : 18|7@0+ (1,0) [0|127] "%" VCU
 SG_ IndOtltFrtLtInbdHrztlPstn : 27|7@0+ (1,0) [0|127] "%" VCU
 SG_ IndOtltFrtLtInbdVertPstn : 36|7@0+ (1,0) [0|127] "%" VCU
 SG_ IndOtltFrtLtOtbdAimRngHght : 45|7@0+ (1,0) [0|127] "%" VCU
 SG_ IndOtltFrtLtOtbdAimRngHrztlOrgn : 54|7@0+ (1,0) [0|127] "%" VCU
 SG_ IndOtltFrtLtOtbdAimRngVertOrgn : 63|7@0+ (1,0) [0|127] "%" VCU

BO_ 1091 PDU_9202: 8 CGM
 SG_ IndOtltFrtLtOtbdHrztlPstn : 0|7@0+ (1,0) [0|127] "%" VCU
 SG_ IndOtltFrtLtOtbdAimRngWdth : 7|7@0+ (1,0) [0|127] "%" VCU
 SG_ IndOtltFrtLtOtbdVertPstn : 9|7@0+ (1,0) [0|127] "%" VCU
 SG_ IndOtltFrtRtInbdAimRngHght : 18|7@0+ (1,0) [0|127] "%" VCU
 SG_ IndOtltFrtRtInbdAimRngHrztlOrgn : 27|7@0+ (1,0) [0|127] "%" VCU
 SG_ IndOtltFrtRtInbdAimRngVertOrgn : 36|7@0+ (1,0) [0|127] "%" VCU
 SG_ IndOtltFrtRtInbdAimRngWdth : 45|7@0+ (1,0) [0|127] "%" VCU
 SG_ IndOtltFrtRtInbdHrztlPstn : 54|7@0+ (1,0) [0|127] "%" VCU
 SG_ IndOtltFrtRtInbdVertPstn : 63|7@0+ (1,0) [0|127] "%" VCU

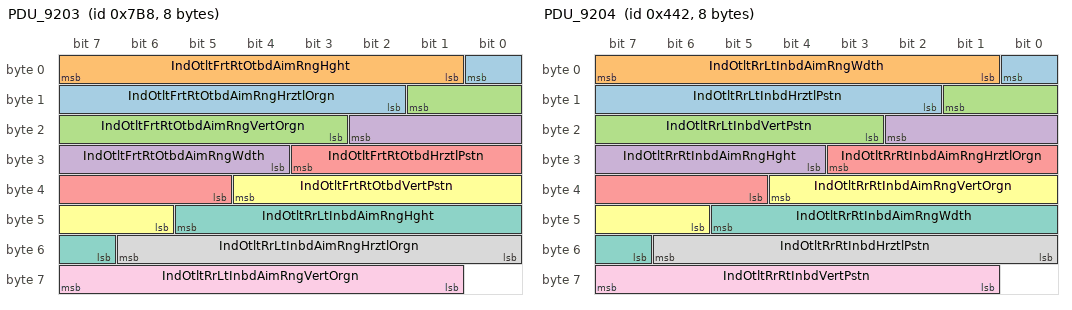
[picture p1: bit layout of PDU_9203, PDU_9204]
BO_ 1976 PDU_9203: 8 CGM
 SG_ IndOtltFrtRtOtbdAimRngHrztlOrgn : 0|7@0+ (1,0) [0|127] "%" VCU
 SG_ IndOtltFrtRtOtbdAimRngHght : 7|7@0+ (1,0) [0|127] "%" VCU
 SG_ IndOtltFrtRtOtbdAimRngVertOrgn : 9|7@0+ (1,0) [0|127] "%" VCU
 SG_ IndOtltFrtRtOtbdAimRngWdth : 18|7@0+ (1,0) [0|127] "%" VCU
 SG_ IndOtltFrtRtOtbdHrztlPstn : 27|7@0+ (1,0) [0|127] "%" VCU
 SG_ IndOtltFrtRtOtbdVertPstn : 36|7@0+ (1,0) [0|127] "%" VCU
 SG_ IndOtltRrLtInbdAimRngHght : 45|7@0+ (1,0) [0|127] "%" VCU
 SG_ IndOtltRrLtInbdAimRngHrztlOrgn : 54|7@0+ (1,0) [0|127] "%" VCU
 SG_ IndOtltRrLtInbdAimRngVertOrgn : 63|7@0+ (1,0) [0|127] "%" VCU

BO_ 1090 PDU_9204: 8 CGM
 SG_ IndOtltRrLtInbdHrztlPstn : 0|7@0+ (1,0) [0|127] "%" VCU
 SG_ IndOtltRrLtInbdAimRngWdth : 7|7@0+ (1,0) [0|127] "%" VCU
 SG_ IndOtltRrLtInbdVertPstn : 9|7@0+ (1,0) [0|127] "%" VCU
 SG_ IndOtltRrRtInbdAimRngHght : 18|7@0+ (1,0) [0|127] "%" VCU
 SG_ IndOtltRrRtInbdAimRngHrztlOrgn : 27|7@0+ (1,0) [0|127] "%" VCU
 SG_ IndOtltRrRtInbdAimRngVertOrgn : 36|7@0+ (1,0) [0|127] "%" VCU
 SG_ IndOtltRrRtInbdAimRngWdth : 45|7@0+ (1,0) [0|127] "%" VCU
 SG_ IndOtltRrRtInbdHrztlPstn : 54|7@0+ (1,0) [0|127] "%" VCU
 SG_ IndOtltRrRtInbdVertPstn : 63|7@0+ (1,0) [0|127] "%" VCU

BO_ 1977 PDU_9205: 8 CGM
 SG_ IndAirDstThrdRw : 0|4@0+ (1,0) [0|8] "" VCU
 SG_ IndTempSetLvlThrdRw : 7|7@0+ (1,0) [0|127] "" VCU
 SG_ IndTempSetStatThrdRw : 8|3@0+ (1,0) [0|4] "" VCU
 SG_ IndBlwSetLvlThrdRw : 12|4@0+ (1,0) [0|15] "" VCU
 SG_ IndBlwSetStatThrdRw : 17|2@0+ (1,0) [0|2] "" VCU
 SG_ IndBlwSetStatRrRt : 19|2@0+ (1,0) [0|2] "" VCU
 SG_ IndBlwSetStatFrtRt : 21|2@0+ (1,0) [0|2] "" VCU
 SG_ IndNckScrfLvlRrRt : 25|2@0+ (1,0) [0|3] "" VCU
 SG_ IndNckScrfLvlRrLt : 27|2@0+ (1,0) [0|3] "" VCU
 SG_ IndNckScrfLvlFrtRt : 29|2@0+ (1,0) [0|3] "" VCU
 SG_ IndNckScrfLvlFrtLt : 31|2@0+ (1,0) [0|3] "" VCU
 SG_ IndOscModeRrRtSet : 33|2@0+ (1,0) [0|2] "" VCU
 SG_ IndOscModeRrLtSet : 35|2@0+ (1,0) [0|2] "" VCU
 SG_ IndOscModeFrtRtSet : 37|2@0+ (1,0) [0|2] "" VCU
 SG_ IndOscModeFrtLtSet : 39|2@0+ (1,0) [0|2] "" VCU
 SG_ IndThrdRwHVACOn : 40|1@0+ (1,0) [0|1] "" VCU
 SG_ IndThrdRwHVACLckd : 41|1@0+ (1,0) [0|1] "" VCU
 SG_ IndSyncThrdRw : 42|1@0+ (1,0) [0|1] "" VCU
 SG_ IndRrRtHVACOn : 43|1@0+ (1,0) [0|1] "" VCU
 SG_ IndRrLtHVACOn : 44|1@0+ (1,0) [0|1] "" VCU
 SG_ IndFrtRtHVACOn : 45|1@0+ (1,0) [0|1] "" VCU
 SG_ IndFrtLtHVACOn : 46|1@0+ (1,0) [0|1] "" VCU
 SG_ IndCkModeOn : 47|1@0+ (1,0) [0|1] "" VCU
 SG_ PwrShdBkGlsShdPs : 48|3@0+ (1,0) [0|5] "" VCU
 SG_ HtdArmrstSyncCstSetAval : 49|1@0+ (1,0) [0|1] "" VCU
 SG_ HtdArmrstSyncCstCurrSetVal : 52|3@0+ (1,0) [0|2] "" VCU
 SG_ ClmCtlThrdRwPwrLtdOpWrnReqActv : 53|1@0+ (1,0) [0|1] "" VCU
 SG_ IndZnUncpdRrSt : 54|1@0+ (1,0) [0|1] "" VCU
 SG_ IndZnUncpdFrtPsngr : 55|1@0+ (1,0) [0|1] "" VCU
 SG_ PwrShdDrShdRRPstn : 58|3@0+ (1,0) [0|5] "" VCU
 SG_ PwrShdDrShdLRPstn : 61|3@0+ (1,0) [0|5] "" VCU

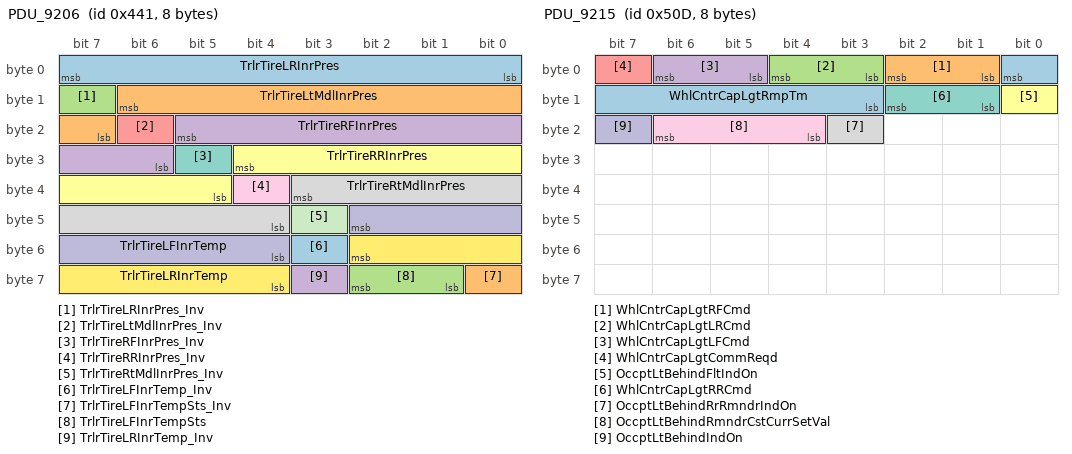
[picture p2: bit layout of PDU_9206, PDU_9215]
BO_ 1089 PDU_9206: 8 CGM
 SG_ TrlrTireLRInrPres : 7|8@0+ (4,0) [0|1020] "kPaG" VCU
 SG_ TrlrTireLtMdlInrPres : 14|8@0+ (4,0) [0|1020] "kPaG" VCU
 SG_ TrlrTireLRInrPres_Inv : 15|1@0+ (1,0) [0|1] "" VCU
 SG_ TrlrTireRFInrPres : 21|8@0+ (4,0) [0|1020] "kPaG" VCU
 SG_ TrlrTireLtMdlInrPres_Inv : 22|1@0+ (1,0) [0|1] "" VCU
 SG_ TrlrTireRRInrPres : 28|8@0+ (4,0) [0|1020] "kPaG" VCU
 SG_ TrlrTireRFInrPres_Inv : 29|1@0+ (1,0) [0|1] "" VCU
 SG_ TrlrTireRtMdlInrPres : 35|8@0+ (4,0) [0|1020] "kPaG" VCU
 SG_ TrlrTireRRInrPres_Inv : 36|1@0+ (1,0) [0|1] "" VCU
 SG_ TrlrTireLFInrTemp : 42|7@0+ (1,-20) [-20|107] "degC" VCU
 SG_ TrlrTireRtMdlInrPres_Inv : 43|1@0+ (1,0) [0|1] "" VCU
 SG_ TrlrTireLRInrTemp : 50|7@0+ (1,-20) [-20|107] "degC" VCU
 SG_ TrlrTireLFInrTemp_Inv : 51|1@0+ (1,0) [0|1] "" VCU
 SG_ TrlrTireLFInrTempSts_Inv : 56|1@0+ (1,0) [0|1] "" VCU
 SG_ TrlrTireLFInrTempSts : 58|2@0+ (1,0) [0|2] "" VCU
 SG_ TrlrTireLRInrTemp_Inv : 59|1@0+ (1,0) [0|1] "" VCU

BO_ 1978 PDU_9207: 8 CGM
 SG_ TrlrTireLtMdlInrTemp_Inv : 0|1@0+ (1,0) [0|1] "" VCU
 SG_ TrlrTireLtMdlInrTemp : 7|7@0+ (1,-20) [-20|107] "degC" VCU
 SG_ TrlrTireRFInrTemp_Inv : 8|1@0+ (1,0) [0|1] "" VCU
 SG_ TrlrTireRFInrTemp : 15|7@0+ (1,-20) [-20|107] "degC" VCU
 SG_ TrlrTireRRInrTemp_Inv : 16|1@0+ (1,0) [0|1] "" VCU
 SG_ TrlrTireRRInrTemp : 23|7@0+ (1,-20) [-20|107] "degC" VCU
 SG_ TrlrTireRtMdlInrTemp_Inv : 24|1@0+ (1,0) [0|1] "" VCU
 SG_ TrlrTireRtMdlInrTemp : 31|7@0+ (1,-20) [-20|107] "degC" VCU
 SG_ TrlrTireLtMdlInrPresSts : 34|4@0+ (1,0) [0|8] "" VCU
 SG_ TrlrTireLRInrPresSts_Inv : 35|1@0+ (1,0) [0|1] "" VCU
 SG_ TrlrTireLRInrPresSts : 39|4@0+ (1,0) [0|8] "" VCU
 SG_ TrlrTireRRInrPresSts : 40|4@0+ (1,0) [0|8] "" VCU
 SG_ TrlrTireRFInrPresSts_Inv : 41|1@0+ (1,0) [0|1] "" VCU
 SG_ TrlrTireRFInrPresSts : 45|4@0+ (1,0) [0|8] "" VCU
 SG_ TrlrTireLtMdlInrPresSts_Inv : 46|1@0+ (1,0) [0|1] "" VCU
 SG_ TrlrTireRtMdlInrPresSts : 51|4@0+ (1,0) [0|8] "" VCU
 SG_ TrlrTireRRInrPresSts_Inv : 52|1@0+ (1,0) [0|1] "" VCU
 SG_ TrlrTireLRInrTempSts_Inv : 57|1@0+ (1,0) [0|1] "" VCU
 SG_ TrlrTireLRInrTempSts : 59|2@0+ (1,0) [0|2] "" VCU
 SG_ TrlrTireLFTempSts_Inv : 60|1@0+ (1,0) [0|1] "" VCU
 SG_ TrlrTireLFTempSts : 62|2@0+ (1,0) [0|2] "" VCU
 SG_ TrlrTireRtMdlInrPresSts_Inv : 63|1@0+ (1,0) [0|1] "" VCU

BO_ 1088 PDU_9208: 8 CGM
 SG_ TrlrTireLtMdlTempSts : 1|2@0+ (1,0) [0|2] "" VCU
 SG_ TrlrTireLtMdlInrTempSts_Inv : 2|1@0+ (1,0) [0|1] "" VCU
 SG_ TrlrTireLtMdlInrTempSts : 4|2@0+ (1,0) [0|2] "" VCU
 SG_ TrlrTireLRTempSts_Inv : 5|1@0+ (1,0) [0|1] "" VCU
 SG_ TrlrTireLRTempSts : 7|2@0+ (1,0) [0|2] "" VCU
 SG_ TrlrTireRRInrTempSts : 8|2@0+ (1,0) [0|2] "" VCU
 SG_ TrlrTireRFTempSts_Inv : 9|1@0+ (1,0) [0|1] "" VCU
 SG_ TrlrTireRFTempSts : 11|2@0+ (1,0) [0|2] "" VCU
 SG_ TrlrTireRFInrTempSts_Inv : 12|1@0+ (1,0) [0|1] "" VCU
 SG_ TrlrTireRFInrTempSts : 14|2@0+ (1,0) [0|2] "" VCU
 SG_ TrlrTireLtMdlTempSts_Inv : 15|1@0+ (1,0) [0|1] "" VCU
 SG_ TrlrTireRtMdlInrTempSts_Inv : 16|1@0+ (1,0) [0|1] "" VCU
 SG_ TrlrTireRtMdlInrTempSts : 18|2@0+ (1,0) [0|2] "" VCU
 SG_ TrlrTireRRTempSts_Inv : 19|1@0+ (1,0) [0|1] "" VCU
 SG_ TrlrTireRRTempSts : 21|2@0+ (1,0) [0|2] "" VCU
 SG_ TrlrTireRRInrTempSts_Inv : 22|1@0+ (1,0) [0|1] "" VCU
 SG_ VarLgtTransGlsRfTntNumCols : 25|2@0+ (1,0) [0|3] "counts" VCU
 SG_ VarLgtTransGlsRfTntNumClrLvls : 28|3@0+ (1,0) [0|7] "counts" VCU
 SG_ TrlrTireRtMdlTempSts_Inv : 29|1@0+ (1,0) [0|1] "" VCU
 SG_ TrlrTireRtMdlTempSts : 31|2@0+ (1,0) [0|2] "" VCU
 SG_ StHtdRrNumLvlAval : 32|2@0+ (1,0) [0|3] "" VCU
 SG_ StHtdFrtNumLvlAval : 34|2@0+ (1,0) [0|3] "" VCU
 SG_ VarLgtTransGlsRfTntVirtCtlAval : 35|1@0+ (1,0) [0|1] "" VCU
 SG_ VarLgtTransGlsRfTntNumRows : 39|4@0+ (1,0) [0|15] "counts" VCU
 SG_ VirtCtlRrWndShdCtlAval : 40|1@0+ (1,0) [0|1] "" VCU
 SG_ VirtCtlPrvcySwAval : 41|1@0+ (1,0) [0|1] "" VCU
 SG_ VirtCtlBkGlsShdCtlAval : 42|1@0+ (1,0) [0|1] "" VCU
 SG_ StVntdCoolRrNumLvlAval : 44|2@0+ (1,0) [0|3] "" VCU
 SG_ StVntdCoolFrtNumLvlAval : 46|2@0+ (1,0) [0|3] "" VCU

BO_ 738 PDU_9209: 8 CGM
 SG_ VarLgtTransGlsRfTntLvlPnl3Set : 1|3@0+ (1,0) [0|6] "" VCU
 SG_ VarLgtTransGlsRfTntLvlPnl2Set : 4|3@0+ (1,0) [0|6] "" VCU
 SG_ VarLgtTransGlsRfTntLvlPnl1Set : 7|3@0+ (1,0) [0|6] "" VCU
 SG_ VarLgtTransGlsRfTntLvlPnl6Set : 8|3@0+ (1,0) [0|6] "" VCU
 SG_ VarLgtTransGlsRfTntLvlPnl5Set : 11|3@0+ (1,0) [0|6] "" VCU
 SG_ VarLgtTransGlsRfTntLvlPnl4Set : 14|3@0+ (1,0) [0|6] "" VCU
 SG_ VarLgtTransGlsRfTntLvlPnl8Set : 18|3@0+ (1,0) [0|6] "" VCU
 SG_ VarLgtTransGlsRfTntLvlPnl7Set : 21|3@0+ (1,0) [0|6] "" VCU
 SG_ MaxPwrModeLngPrssReq : 25|2@0+ (1,0) [0|2] "" VCU
 SG_ VarLgtTransGlsRfVirtCtlMenuReqd : 26|1@0+ (1,0) [0|1] "" VCU
 SG_ VarLgtTransGlsRfTntVirtCtlAllwd : 27|1@0+ (1,0) [0|1] "" VCU
 SG_ VarLgtTransGlsRfTntAutoSetActv : 28|1@0+ (1,0) [0|1] "" VCU
 SG_ VarLgtTransGlsRfTntLvlSldrSet : 31|3@0+ (1,0) [0|5] "" VCU
 SG_ TrlrTireLkDtnLFSts : 33|2@0+ (1,0) [0|3] "" VCU
 SG_ TrlrTireLkDtnLFInrSts : 35|2@0+ (1,0) [0|3] "" VCU
 SG_ TrlrTireLkDtnEnblSts : 37|2@0+ (1,0) [0|2] "" VCU
 SG_ RrClsrAccssVirtCtlAval : 38|1@0+ (1,0) [0|1] "" VCU
 SG_ RrClsrAccssVirtCtlAllwd : 39|1@0+ (1,0) [0|1] "" VCU
 SG_ TrlrTireLkDtnLtMdlSts : 41|2@0+ (1,0) [0|3] "" VCU
 SG_ TrlrTireLkDtnLtMdlInrSts : 43|2@0+ (1,0) [0|3] "" VCU
 SG_ TrlrTireLkDtnLRSts : 45|2@0+ (1,0) [0|3] "" VCU
 SG_ TrlrTireLkDtnLRInrSts : 47|2@0+ (1,0) [0|3] "" VCU
 SG_ TrlrTireLkDtnRRSts : 49|2@0+ (1,0) [0|3] "" VCU
 SG_ TrlrTireLkDtnRRInrSts : 51|2@0+ (1,0) [0|3] "" VCU
 SG_ TrlrTireLkDtnRFSts : 53|2@0+ (1,0) [0|3] "" VCU
 SG_ TrlrTireLkDtnRFInrSts : 55|2@0+ (1,0) [0|3] "" VCU
 SG_ VirtCtlRrWndShdCtlRrAllwd : 56|1@0+ (1,0) [0|1] "" VCU
 SG_ VirtCtlRrWndShdCtlFrtAllwd : 57|1@0+ (1,0) [0|1] "" VCU
 SG_ TrlrTireLkDtnWrstCsSts : 59|2@0+ (1,0) [0|3] "" VCU
 SG_ TrlrTireLkDtnRtMdlSts : 61|2@0+ (1,0) [0|3] "" VCU
 SG_ TrlrTireLkDtnRtMdlInrSts : 63|2@0+ (1,0) [0|3] "" VCU

BO_ 1350 PDU_9210: 8 IPC
 SG_ OccptLtBehindAlrmDlyDrvrResp : 53|2@0+ (1,0) [0|2] "" Vector__XXX

BO_ 1087 PDU_9211: 8 CGM
 SG_ TrlrTireLFInrSnsrIdfr : 7|32@0+ (1,0) [0|4.29497e+009] "" VCU
 SG_ TrlrTireLRInrSnsrIdfr : 39|32@0+ (1,0) [0|4.29497e+009] "" VCU

BO_ 1980 PDU_9212: 8 CGM
 SG_ TrlrTireLtMdlInrSnsrIdfr : 7|32@0+ (1,0) [0|4.29497e+009] "" VCU
 SG_ TrlrTireRFInrSnsrIdfr : 39|32@0+ (1,0) [0|4.29497e+009] "" VCU

BO_ 1086 PDU_9213: 8 CGM
 SG_ TrlrTireRRInrSnsrIdfr : 7|32@0+ (1,0) [0|4.29497e+009] "" VCU
 SG_ TrlrTireRtMdlInrSnsrIdfr : 39|32@0+ (1,0) [0|4.29497e+009] "" VCU

BO_ 2004 PDU_9214: 8 CGM
 SG_ TnDrvrOvrspdWrnCstLvlMaxAlwdVal : 7|12@0+ (0.0625,0) [0|255.938] "km/h" TCP
 SG_ TnDrvrOvrspdWrnCstLvlMinAlwdVal : 11|12@0+ (0.0625,0) [0|255.938] "km/h" TCP
 SG_ OccptLtBehindRmndrCstAvlFlg4 : 24|1@0+ (1,0) [0|1] "" CSM,CSM_AV,VCU
 SG_ OccptLtBehindRmndrCstAvlFlg3 : 25|1@0+ (1,0) [0|1] "" CSM,CSM_AV,VCU
 SG_ OccptLtBehindRmndrCstAvlFlg2 : 26|1@0+ (1,0) [0|1] "" CSM,CSM_AV,VCU
 SG_ OccptLtBehindRmndrCstAvlFlg1 : 27|1@0+ (1,0) [0|1] "" CSM,CSM_AV,VCU
 SG_ OccptLtBehindAlrmDlyVal : 31|4@0+ (1,0) [0|15] "" IPC,IPC_INT,VCU
 SG_ IndMcrClmStSyncRrRt : 32|1@0+ (1,0) [0|1] "" VCU
 SG_ IndMcrClmStSyncRrLt : 33|1@0+ (1,0) [0|1] "" VCU
 SG_ IndMcrClmStSyncFrtRt : 34|1@0+ (1,0) [0|1] "" VCU
 SG_ IndMcrClmStSyncFrtLt : 35|1@0+ (1,0) [0|1] "" VCU
 SG_ OccptLtBehindRmndrCstSetAval : 36|1@0+ (1,0) [0|1] "" CSM,CSM_AV,VCU
 SG_ OccptLtBehindRmndrCstAvlFlg7 : 37|1@0+ (1,0) [0|1] "" CSM,CSM_AV,VCU
 SG_ OccptLtBehindRmndrCstAvlFlg6 : 38|1@0+ (1,0) [0|1] "" CSM,CSM_AV,VCU
 SG_ OccptLtBehindRmndrCstAvlFlg5 : 39|1@0+ (1,0) [0|1] "" CSM,CSM_AV,VCU
 SG_ McrClmStSyncRrRtAval : 44|1@0+ (1,0) [0|1] "" VCU
 SG_ McrClmStSyncRrLtAval : 45|1@0+ (1,0) [0|1] "" VCU
 SG_ McrClmStSyncFrtRtAval : 46|1@0+ (1,0) [0|1] "" VCU
 SG_ McrClmStSyncFrtLtAval : 47|1@0+ (1,0) [0|1] "" VCU

BO_ 1293 PDU_9215: 8 CGM
 SG_ WhlCntrCapLgtRmpTm : 0|6@0+ (79.3651,0) [0|5000] "ms" VKM
 SG_ WhlCntrCapLgtRFCmd : 2|2@0+ (1,0) [0|2] "" VKM
 SG_ WhlCntrCapLgtLRCmd : 4|2@0+ (1,0) [0|2] "" VKM
 SG_ WhlCntrCapLgtLFCmd : 6|2@0+ (1,0) [0|2] "" VKM
 SG_ WhlCntrCapLgtCommReqd : 7|1@0+ (1,0) [0|1] "" VKM
 SG_ OccptLtBehindFltIndOn : 8|1@0+ (1,0) [0|1] "" IPC,IPC_INT,VCU
 SG_ WhlCntrCapLgtRRCmd : 10|2@0+ (1,0) [0|2] "" VKM
 SG_ OccptLtBehindRrRmndrIndOn : 19|1@0+ (1,0) [0|1] "" IPC,IPC_INT,VCU
 SG_ OccptLtBehindRmndrCstCurrSetVal : 22|3@0+ (1,0) [0|2] "" CSM,CSM_AV,VCU
 SG_ OccptLtBehindIndOn : 23|1@0+ (1,0) [0|1] "" IPC,IPC_INT,VCU

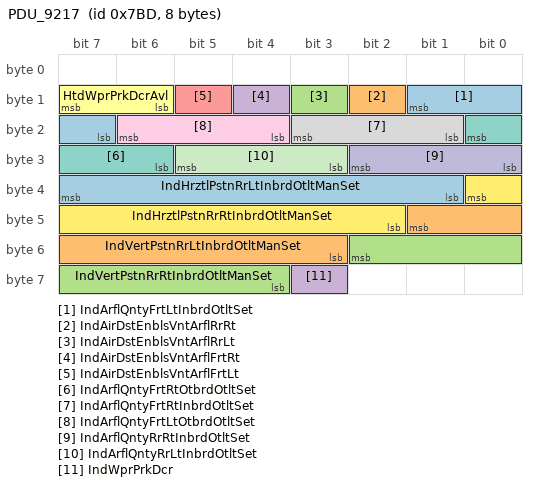
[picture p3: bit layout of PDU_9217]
BO_ 1981 PDU_9217: 8 CGM
 SG_ IndArflQntyFrtLtInbrdOtltSet : 9|3@0+ (1,0) [0|4] "" VCU
 SG_ IndAirDstEnblsVntArflRrRt : 10|1@0+ (1,0) [0|1] "" VCU
 SG_ IndAirDstEnblsVntArflRrLt : 11|1@0+ (1,0) [0|1] "" VCU
 SG_ IndAirDstEnblsVntArflFrtRt : 12|1@0+ (1,0) [0|1] "" VCU
 SG_ IndAirDstEnblsVntArflFrtLt : 13|1@0+ (1,0) [0|1] "" VCU
 SG_ HtdWprPrkDcrAvl : 15|2@0+ (1,0) [0|2] "" VCU
 SG_ IndArflQntyFrtRtOtbrdOtltSet : 16|3@0+ (1,0) [0|4] "" VCU
 SG_ IndArflQntyFrtRtInbrdOtltSet : 19|3@0+ (1,0) [0|4] "" VCU
 SG_ IndArflQntyFrtLtOtbrdOtltSet : 22|3@0+ (1,0) [0|4] "" VCU
 SG_ IndArflQntyRrRtInbrdOtltSet : 26|3@0+ (1,0) [0|4] "" VCU
 SG_ IndArflQntyRrLtInbrdOtltSet : 29|3@0+ (1,0) [0|4] "" VCU
 SG_ IndHrztlPstnRrRtInbrdOtltManSet : 32|7@0+ (1,0) [0|127] "" VCU
 SG_ IndHrztlPstnRrLtInbrdOtltManSet : 39|7@0+ (1,0) [0|127] "" VCU
 SG_ IndVertPstnRrLtInbrdOtltManSet : 41|7@0+ (1,0) [0|127] "" VCU
 SG_ IndVertPstnRrRtInbrdOtltManSet : 50|7@0+ (1,0) [0|127] "" VCU
 SG_ IndWprPrkDcr : 59|1@0+ (1,0) [0|1] "" VCU

BA_DEF_ SG_  "SignalType" STRING ;
BA_DEF_ SG_  "SignalLongName" STRING ;
BA_DEF_ BO_  "GenMsgCycleTime" INT 0 10000;
BA_DEF_ BO_  "GenMsgSendType" ENUM "cyclicX","spontanX","cyclicIfActiveX","spontanWithDelay","cyclicAndSpontanX","cyclicAndSpontanWithDelay","spontanWithRepetition","cyclicIfActiveAndSpontanWD";
BA_DEF_DEF_  "SignalType" "";
BA_DEF_DEF_  "SignalLongName" "";
BA_DEF_DEF_  "GenMsgCycleTime" 0;
BA_DEF_DEF_  "GenMsgSendType" "cyclicX";
BA_ "GenMsgCycleTime" BO_ 1444 1000;
BA_ "GenMsgCycleTime" BO_ 1924 1000;
BA_ "GenMsgCycleTime" BO_ 1925 1000;
BA_ "GenMsgCycleTime" BO_ 1926 1000;
BA_ "GenMsgCycleTime" BO_ 1132 1000;
BA_ "GenMsgCycleTime" BO_ 1935 1000;
BA_ "GenMsgCycleTime" BO_ 1952 1000;
BA_ "GenMsgCycleTime" BO_ 1975 1000;
BA_ "GenMsgCycleTime" BO_ 1091 1000;
BA_ "GenMsgCycleTime" BO_ 1976 1000;
BA_ "GenMsgCycleTime" BO_ 1090 1000;
BA_ "GenMsgCycleTime" BO_ 1977 1000;
BA_ "GenMsgCycleTime" BO_ 1089 1000;
BA_ "GenMsgCycleTime" BO_ 1978 1000;
BA_ "GenMsgCycleTime" BO_ 1088 1000;
BA_ "GenMsgCycleTime" BO_ 738 1000;
BA_ "GenMsgCycleTime" BO_ 1350 1000;
BA_ "GenMsgCycleTime" BO_ 1087 1000;
BA_ "GenMsgCycleTime" BO_ 1980 1000;
BA_ "GenMsgCycleTime" BO_ 1086 1000;
BA_ "GenMsgCycleTime" BO_ 2004 1000;
BA_ "GenMsgCycleTime" BO_ 1293 1000;
BA_ "GenMsgCycleTime" BO_ 1981 1000;
BA_ "SignalLongName" SG_ 1444 TrlrTireLFInrPres "Trailer Tire Left Front Inner Pressure Information : Trailer Tire Left Front Inner Pressure";
BA_ "SignalType" SG_ 1444 ArflBsdOnOccpFrtPsCstAvlFlg2 "ENM";
BA_ "SignalLongName" SG_ 1444 ArflBsdOnOccpFrtPsCstAvlFlg2 "Airflow Based On Occupancy Front Passenger Customization Availability Flag2";
BA_ "SignalType" SG_ 1444 ArflBsdOnOccpFrtPsCstAvlFlg1 "ENM";
BA_ "SignalLongName" SG_ 1444 ArflBsdOnOccpFrtPsCstAvlFlg1 "Airflow Based On Occupancy Front Passenger Customization Availability Flag1";
BA_ "SignalType" SG_ 1444 TrlrTireLFInrPresSts_Inv "ENM";
BA_ "SignalLongName" SG_ 1444 TrlrTireLFInrPresSts_Inv "Trailer Tire Left Front Inner Pressure Status Information : Trailer Tire Left Front Inner Pressure Status Invalid";
BA_ "SignalType" SG_ 1444 TrlrTireLFInrPresSts "ENM";
BA_ "SignalLongName" SG_ 1444 TrlrTireLFInrPresSts "Trailer Tire Left Front Inner Pressure Status Information : Trailer Tire Left Front Inner Pressure Status";
BA_ "SignalType" SG_ 1444 TrlrTireLFInrPres_Inv "ENM";
BA_ "SignalLongName" SG_ 1444 TrlrTireLFInrPres_Inv "Trailer Tire Left Front Inner Pressure Information : Trailer Tire Left Front Inner Pressure Invalid";
BA_ "SignalType" SG_ 1444 ArflBsdOnOccpRrPsCstAvlFlg2 "ENM";
BA_ "SignalLongName" SG_ 1444 ArflBsdOnOccpRrPsCstAvlFlg2 "Airflow Based On Occupancy Rear Passenger Customization Availability Flag2";
BA_ "SignalType" SG_ 1444 ArflBsdOnOccpRrPsCstAvlFlg1 "ENM";
BA_ "SignalLongName" SG_ 1444 ArflBsdOnOccpRrPsCstAvlFlg1 "Airflow Based On Occupancy Rear Passenger Customization Availability Flag1";
BA_ "SignalType" SG_ 1444 ArflBsdOnOccpFrtPsCstSetAval "ENM";
BA_ "SignalLongName" SG_ 1444 ArflBsdOnOccpFrtPsCstSetAval "Airflow Based On Occupancy Front Passenger Customization Setting Available";
BA_ "SignalType" SG_ 1444 ArflBsdOnOccpFrtPsCstAvlFlg7 "ENM";
BA_ "SignalLongName" SG_ 1444 ArflBsdOnOccpFrtPsCstAvlFlg7 "Airflow Based On Occupancy Front Passenger Customization Availability Flag7";
BA_ "SignalType" SG_ 1444 ArflBsdOnOccpFrtPsCstAvlFlg6 "ENM";
BA_ "SignalLongName" SG_ 1444 ArflBsdOnOccpFrtPsCstAvlFlg6 "Airflow Based On Occupancy Front Passenger Customization Availability Flag6";
BA_ "SignalType" SG_ 1444 ArflBsdOnOccpFrtPsCstAvlFlg5 "ENM";
BA_ "SignalLongName" SG_ 1444 ArflBsdOnOccpFrtPsCstAvlFlg5 "Airflow Based On Occupancy Front Passenger Customization Availability Flag5";
BA_ "SignalType" SG_ 1444 ArflBsdOnOccpFrtPsCstAvlFlg4 "ENM";
BA_ "SignalLongName" SG_ 1444 ArflBsdOnOccpFrtPsCstAvlFlg4 "Airflow Based On Occupancy Front Passenger Customization Availability Flag4";
BA_ "SignalType" SG_ 1444 ArflBsdOnOccpFrtPsCstAvlFlg3 "ENM";
BA_ "SignalLongName" SG_ 1444 ArflBsdOnOccpFrtPsCstAvlFlg3 "Airflow Based On Occupancy Front Passenger Customization Availability Flag3";
BA_ "SignalType" SG_ 1444 AutoAirOtltAmgCstAvlFlg2 "ENM";
BA_ "SignalLongName" SG_ 1444 AutoAirOtltAmgCstAvlFlg2 "Automatic Air Outlet Aiming Customization Availability Flag 2";
BA_ "SignalType" SG_ 1444 AutoAirOtltAmgCstAvlFlg1 "ENM";
BA_ "SignalLongName" SG_ 1444 AutoAirOtltAmgCstAvlFlg1 "Automatic Air Outlet Aiming Customization Availability Flag 1";
BA_ "SignalType" SG_ 1444 ArflBsdOnOccpRrPsCstSetAval "ENM";
BA_ "SignalLongName" SG_ 1444 ArflBsdOnOccpRrPsCstSetAval "Airflow Based On Occupancy Rear Passenger Customization Setting Available";
BA_ "SignalType" SG_ 1444 ArflBsdOnOccpRrPsCstAvlFlg7 "ENM";
BA_ "SignalLongName" SG_ 1444 ArflBsdOnOccpRrPsCstAvlFlg7 "Airflow Based On Occupancy Rear Passenger Customization Availability Flag7";
BA_ "SignalType" SG_ 1444 ArflBsdOnOccpRrPsCstAvlFlg6 "ENM";
BA_ "SignalLongName" SG_ 1444 ArflBsdOnOccpRrPsCstAvlFlg6 "Airflow Based On Occupancy Rear Passenger Customization Availability Flag6";
BA_ "SignalType" SG_ 1444 ArflBsdOnOccpRrPsCstAvlFlg5 "ENM";
BA_ "SignalLongName" SG_ 1444 ArflBsdOnOccpRrPsCstAvlFlg5 "Airflow Based On Occupancy Rear Passenger Customization Availability Flag5";
BA_ "SignalType" SG_ 1444 ArflBsdOnOccpRrPsCstAvlFlg4 "ENM";
BA_ "SignalLongName" SG_ 1444 ArflBsdOnOccpRrPsCstAvlFlg4 "Airflow Based On Occupancy Rear Passenger Customization Availability Flag4";
BA_ "SignalType" SG_ 1444 ArflBsdOnOccpRrPsCstAvlFlg3 "ENM";
BA_ "SignalLongName" SG_ 1444 ArflBsdOnOccpRrPsCstAvlFlg3 "Airflow Based On Occupancy Rear Passenger Customization Availability Flag3";
BA_ "SignalType" SG_ 1444 AutoNckScrfCstAvlFlg2 "ENM";
BA_ "SignalLongName" SG_ 1444 AutoNckScrfCstAvlFlg2 "Automatic Neck Scarf Customization Availability Flag 2";
BA_ "SignalType" SG_ 1444 AutoNckScrfCstAvlFlg1 "ENM";
BA_ "SignalLongName" SG_ 1444 AutoNckScrfCstAvlFlg1 "Automatic Neck Scarf Customization Availability Flag 1";
BA_ "SignalType" SG_ 1444 AutoAirOtltAmgCstSetAval "ENM";
BA_ "SignalLongName" SG_ 1444 AutoAirOtltAmgCstSetAval "Automatic Air Outlet Aiming Customization Setting Available";
BA_ "SignalType" SG_ 1444 AutoAirOtltAmgCstAvlFlg7 "ENM";
BA_ "SignalLongName" SG_ 1444 AutoAirOtltAmgCstAvlFlg7 "Automatic Air Outlet Aiming Customization Availability Flag 7";
BA_ "SignalType" SG_ 1444 AutoAirOtltAmgCstAvlFlg6 "ENM";
BA_ "SignalLongName" SG_ 1444 AutoAirOtltAmgCstAvlFlg6 "Automatic Air Outlet Aiming Customization Availability Flag 6";
BA_ "SignalType" SG_ 1444 AutoAirOtltAmgCstAvlFlg5 "ENM";
BA_ "SignalLongName" SG_ 1444 AutoAirOtltAmgCstAvlFlg5 "Automatic Air Outlet Aiming Customization Availability Flag 5";
BA_ "SignalType" SG_ 1444 AutoAirOtltAmgCstAvlFlg4 "ENM";
BA_ "SignalLongName" SG_ 1444 AutoAirOtltAmgCstAvlFlg4 "Automatic Air Outlet Aiming Customization Availability Flag 4";
BA_ "SignalType" SG_ 1444 AutoAirOtltAmgCstAvlFlg3 "ENM";
BA_ "SignalLongName" SG_ 1444 AutoAirOtltAmgCstAvlFlg3 "Automatic Air Outlet Aiming Customization Availability Flag 3";
BA_ "SignalType" SG_ 1444 Aux2AmbtAnmCtlCstAvlFlg10 "ENM";
BA_ "SignalLongName" SG_ 1444 Aux2AmbtAnmCtlCstAvlFlg10 "Auxiliary 2 Ambient Animation Control Customization Availability Flag 10";
BA_ "SignalType" SG_ 1444 Aux2AmbtAnmCtlCstAvlFlg1 "ENM";
BA_ "SignalLongName" SG_ 1444 Aux2AmbtAnmCtlCstAvlFlg1 "Auxiliary 2 Ambient Animation Control Customization Availability Flag 1";
BA_ "SignalType" SG_ 1444 AutoNckScrfCstSetAval "ENM";
BA_ "SignalLongName" SG_ 1444 AutoNckScrfCstSetAval "Automatic Neck Scarf Customization Setting Available";
BA_ "SignalType" SG_ 1444 AutoNckScrfCstAvlFlg7 "ENM";
BA_ "SignalLongName" SG_ 1444 AutoNckScrfCstAvlFlg7 "Automatic Neck Scarf Customization Availability Flag 7";
BA_ "SignalType" SG_ 1444 AutoNckScrfCstAvlFlg6 "ENM";
BA_ "SignalLongName" SG_ 1444 AutoNckScrfCstAvlFlg6 "Automatic Neck Scarf Customization Availability Flag 6";
BA_ "SignalType" SG_ 1444 AutoNckScrfCstAvlFlg5 "ENM";
BA_ "SignalLongName" SG_ 1444 AutoNckScrfCstAvlFlg5 "Automatic Neck Scarf Customization Availability Flag 5";
BA_ "SignalType" SG_ 1444 AutoNckScrfCstAvlFlg4 "ENM";
BA_ "SignalLongName" SG_ 1444 AutoNckScrfCstAvlFlg4 "Automatic Neck Scarf Customization Availability Flag 4";
BA_ "SignalType" SG_ 1444 AutoNckScrfCstAvlFlg3 "ENM";
BA_ "SignalLongName" SG_ 1444 AutoNckScrfCstAvlFlg3 "Automatic Neck Scarf Customization Availability Flag 3";
BA_ "SignalType" SG_ 1444 SCAPwrDrLckAllVirtCtlRrAllwd "ENM";
BA_ "SignalLongName" SG_ 1444 SCAPwrDrLckAllVirtCtlRrAllwd "Side Closure Access Power Door Lock All Virtual Control Rear Allowed";
BA_ "SignalType" SG_ 1444 SCAPwrDrLckAllVirtCtlFrtAllwd "ENM";
BA_ "SignalLongName" SG_ 1444 SCAPwrDrLckAllVirtCtlFrtAllwd "Side Closure Access Power Door Lock All Virtual Control Front Allowed";
BA_ "SignalType" SG_ 1444 SCAPwrDrLckAllVirtCtlAval "ENM";
BA_ "SignalLongName" SG_ 1444 SCAPwrDrLckAllVirtCtlAval "Side Closure Access Power Door Lock All Virtual Control Available";
BA_ "SignalType" SG_ 1444 DMHrnOutPrkCstSetAval "ENM";
BA_ "SignalLongName" SG_ 1444 DMHrnOutPrkCstSetAval "Delivery Mode Horn Out Of Park Customization Setting Available";
BA_ "SignalType" SG_ 1444 DMDrvrDrUnlckPrkCstSetAval "ENM";
BA_ "SignalLongName" SG_ 1444 DMDrvrDrUnlckPrkCstSetAval "Delivery Mode Driver Door Unlock on Park Customization Setting Available";
BA_ "SignalType" SG_ 1444 Aux2AmbtColrCtlCstAvlFlg1 "ENM";
BA_ "SignalLongName" SG_ 1444 Aux2AmbtColrCtlCstAvlFlg1 "Auxiliary 2 Ambient Color Control Customization Availability Flag 1";
BA_ "SignalType" SG_ 1444 Aux2AmbtAnmCtlCstAvlFlg12 "ENM";
BA_ "SignalLongName" SG_ 1444 Aux2AmbtAnmCtlCstAvlFlg12 "Auxiliary 2 Ambient Animation Control Customization Availability Flag 12";
BA_ "SignalType" SG_ 1444 Aux2AmbtAnmCtlCstAvlFlg11 "ENM";
BA_ "SignalLongName" SG_ 1444 Aux2AmbtAnmCtlCstAvlFlg11 "Auxiliary 2 Ambient Animation Control Customization Availability Flag 11";
BA_ "SignalType" SG_ 1444 IndThrdRowHVACAuto "ENM";
BA_ "SignalLongName" SG_ 1444 IndThrdRowHVACAuto "Indication Third Row HVAC Auto";
BA_ "SignalType" SG_ 1444 IndRrRtHVACAuto "ENM";
BA_ "SignalLongName" SG_ 1444 IndRrRtHVACAuto "Indication Rear Right HVAC Auto";
BA_ "SignalType" SG_ 1444 IndRrLtHVACAuto "ENM";
BA_ "SignalLongName" SG_ 1444 IndRrLtHVACAuto "Indication Rear Left HVAC Auto";
BA_ "SignalType" SG_ 1444 IndFrtRtHVACAuto "ENM";
BA_ "SignalLongName" SG_ 1444 IndFrtRtHVACAuto "Indication Front Right HVAC Auto";
BA_ "SignalType" SG_ 1444 IndFrtLtHVACAuto "ENM";
BA_ "SignalLongName" SG_ 1444 IndFrtLtHVACAuto "Indication Front Left HVAC Auto";
BA_ "SignalType" SG_ 1444 SCAPwrDrUnlckAllVirtCtlRrAllwd "ENM";
BA_ "SignalLongName" SG_ 1444 SCAPwrDrUnlckAllVirtCtlRrAllwd "Side Closure Access Power Door Unlock All Virtual Control Rear Allowed";
BA_ "SignalType" SG_ 1444 SCAPwrDrUnlckAllVirtCtlFrtAllwd "ENM";
BA_ "SignalLongName" SG_ 1444 SCAPwrDrUnlckAllVirtCtlFrtAllwd "Side Closure Access Power Door Unlock All Virtual Control Front Allowed";
BA_ "SignalType" SG_ 1444 SCAPwrDrUnlckAllVirtCtlAval "ENM";
BA_ "SignalLongName" SG_ 1444 SCAPwrDrUnlckAllVirtCtlAval "Side Closure Access Power Door Unlock All Virtual Control Available";
BA_ "SignalType" SG_ 1924 Aux2AmbtAnmCtlCstAvlFlg6 "ENM";
BA_ "SignalLongName" SG_ 1924 Aux2AmbtAnmCtlCstAvlFlg6 "Auxiliary 2 Ambient Animation Control Customization Availability Flag 6";
BA_ "SignalType" SG_ 1924 Aux2AmbtAnmCtlCstAvlFlg5 "ENM";
BA_ "SignalLongName" SG_ 1924 Aux2AmbtAnmCtlCstAvlFlg5 "Auxiliary 2 Ambient Animation Control Customization Availability Flag 5";
BA_ "SignalType" SG_ 1924 Aux2AmbtAnmCtlCstAvlFlg4 "ENM";
BA_ "SignalLongName" SG_ 1924 Aux2AmbtAnmCtlCstAvlFlg4 "Auxiliary 2 Ambient Animation Control Customization Availability Flag 4";
BA_ "SignalType" SG_ 1924 Aux2AmbtAnmCtlCstAvlFlg3 "ENM";
BA_ "SignalLongName" SG_ 1924 Aux2AmbtAnmCtlCstAvlFlg3 "Auxiliary 2 Ambient Animation Control Customization Availability Flag 3";
BA_ "SignalType" SG_ 1924 Aux2AmbtAnmCtlCstAvlFlg2 "ENM";
BA_ "SignalLongName" SG_ 1924 Aux2AmbtAnmCtlCstAvlFlg2 "Auxiliary 2 Ambient Animation Control Customization Availability Flag 2";
BA_ "SignalType" SG_ 1924 Aux2AmbtAnmCtlCstAvlFlg15 "ENM";
BA_ "SignalLongName" SG_ 1924 Aux2AmbtAnmCtlCstAvlFlg15 "Auxiliary 2 Ambient Animation Control Customization Availability Flag 15";
BA_ "SignalType" SG_ 1924 Aux2AmbtAnmCtlCstAvlFlg14 "ENM";
BA_ "SignalLongName" SG_ 1924 Aux2AmbtAnmCtlCstAvlFlg14 "Auxiliary 2 Ambient Animation Control Customization Availability Flag 14";
BA_ "SignalType" SG_ 1924 Aux2AmbtAnmCtlCstAvlFlg13 "ENM";
BA_ "SignalLongName" SG_ 1924 Aux2AmbtAnmCtlCstAvlFlg13 "Auxiliary 2 Ambient Animation Control Customization Availability Flag 13";
BA_ "SignalType" SG_ 1924 Aux2AmbtBrghtnsCtlCstAvlFlg4 "ENM";
BA_ "SignalLongName" SG_ 1924 Aux2AmbtBrghtnsCtlCstAvlFlg4 "Auxiliary 2 Ambient Brightness Control Customization Availability Flag 4";
BA_ "SignalType" SG_ 1924 Aux2AmbtBrghtnsCtlCstAvlFlg3 "ENM";
BA_ "SignalLongName" SG_ 1924 Aux2AmbtBrghtnsCtlCstAvlFlg3 "Auxiliary 2 Ambient Brightness Control Customization Availability Flag 3";
BA_ "SignalType" SG_ 1924 Aux2AmbtBrghtnsCtlCstAvlFlg2 "ENM";
BA_ "SignalLongName" SG_ 1924 Aux2AmbtBrghtnsCtlCstAvlFlg2 "Auxiliary 2 Ambient Brightness Control Customization Availability Flag 2";
BA_ "SignalType" SG_ 1924 Aux2AmbtBrghtnsCtlCstAvlFlg1 "ENM";
BA_ "SignalLongName" SG_ 1924 Aux2AmbtBrghtnsCtlCstAvlFlg1 "Auxiliary 2 Ambient Brightness Control Customization Availability Flag 1";
BA_ "SignalType" SG_ 1924 Aux2AmbtAnmCtlCstSetAval "ENM";
BA_ "SignalLongName" SG_ 1924 Aux2AmbtAnmCtlCstSetAval "Auxiliary 2 Ambient Animation Control Customization Setting Available";
BA_ "SignalType" SG_ 1924 Aux2AmbtAnmCtlCstAvlFlg9 "ENM";
BA_ "SignalLongName" SG_ 1924 Aux2AmbtAnmCtlCstAvlFlg9 "Auxiliary 2 Ambient Animation Control Customization Availability Flag 9";
BA_ "SignalType" SG_ 1924 Aux2AmbtAnmCtlCstAvlFlg8 "ENM";
BA_ "SignalLongName" SG_ 1924 Aux2AmbtAnmCtlCstAvlFlg8 "Auxiliary 2 Ambient Animation Control Customization Availability Flag 8";
BA_ "SignalType" SG_ 1924 Aux2AmbtAnmCtlCstAvlFlg7 "ENM";
BA_ "SignalLongName" SG_ 1924 Aux2AmbtAnmCtlCstAvlFlg7 "Auxiliary 2 Ambient Animation Control Customization Availability Flag 7";
BA_ "SignalType" SG_ 1924 Aux3AmbtColrCtlCstAvlFlg82 "ENM";
BA_ "SignalLongName" SG_ 1924 Aux3AmbtColrCtlCstAvlFlg82 "Auxiliary 3 Ambient Color Control Customization Availability Flag 82";
BA_ "SignalType" SG_ 1924 Aux3AmbtColrCtlCstAvlFlg81 "ENM";
BA_ "SignalLongName" SG_ 1924 Aux3AmbtColrCtlCstAvlFlg81 "Auxiliary 3 Ambient Color Control Customization Availability Flag 81";
BA_ "SignalType" SG_ 1924 Aux3AmbtColrCtlCstAvlFlg80 "ENM";
BA_ "SignalLongName" SG_ 1924 Aux3AmbtColrCtlCstAvlFlg80 "Auxiliary 3 Ambient Color Control Customization Availability Flag 80";
BA_ "SignalType" SG_ 1924 Aux3AmbtColrCtlCstAvlFlg8 "ENM";
BA_ "SignalLongName" SG_ 1924 Aux3AmbtColrCtlCstAvlFlg8 "Auxiliary 3 Ambient Color Control Customization Availability Flag 8";
BA_ "SignalType" SG_ 1924 Aux2AmbtBrghtnsCtlCstSetAval "ENM";
BA_ "SignalLongName" SG_ 1924 Aux2AmbtBrghtnsCtlCstSetAval "Auxiliary 2 Ambient Brightness Control Customization Setting Available";
BA_ "SignalType" SG_ 1924 Aux2AmbtBrghtnsCtlCstAvlFlg7 "ENM";
BA_ "SignalLongName" SG_ 1924 Aux2AmbtBrghtnsCtlCstAvlFlg7 "Auxiliary 2 Ambient Brightness Control Customization Availability Flag 7";
BA_ "SignalType" SG_ 1924 Aux2AmbtBrghtnsCtlCstAvlFlg6 "ENM";
BA_ "SignalLongName" SG_ 1924 Aux2AmbtBrghtnsCtlCstAvlFlg6 "Auxiliary 2 Ambient Brightness Control Customization Availability Flag 6";
BA_ "SignalType" SG_ 1924 Aux2AmbtBrghtnsCtlCstAvlFlg5 "ENM";
BA_ "SignalLongName" SG_ 1924 Aux2AmbtBrghtnsCtlCstAvlFlg5 "Auxiliary 2 Ambient Brightness Control Customization Availability Flag 5";
BA_ "SignalType" SG_ 1924 Aux3AmbtColrCtlCstAvlFlg9 "ENM";
BA_ "SignalLongName" SG_ 1924 Aux3AmbtColrCtlCstAvlFlg9 "Auxiliary 3 Ambient Color Control Customization Availability Flag 9";
BA_ "SignalType" SG_ 1924 Aux3AmbtColrCtlCstAvlFlg89 "ENM";
BA_ "SignalLongName" SG_ 1924 Aux3AmbtColrCtlCstAvlFlg89 "Auxiliary 3 Ambient Color Control Customization Availability Flag 89";
BA_ "SignalType" SG_ 1924 Aux3AmbtColrCtlCstAvlFlg88 "ENM";
BA_ "SignalLongName" SG_ 1924 Aux3AmbtColrCtlCstAvlFlg88 "Auxiliary 3 Ambient Color Control Customization Availability Flag 88";
BA_ "SignalType" SG_ 1924 Aux3AmbtColrCtlCstAvlFlg87 "ENM";
BA_ "SignalLongName" SG_ 1924 Aux3AmbtColrCtlCstAvlFlg87 "Auxiliary 3 Ambient Color Control Customization Availability Flag 87";
BA_ "SignalType" SG_ 1924 Aux3AmbtColrCtlCstAvlFlg86 "ENM";
BA_ "SignalLongName" SG_ 1924 Aux3AmbtColrCtlCstAvlFlg86 "Auxiliary 3 Ambient Color Control Customization Availability Flag 86";
BA_ "SignalType" SG_ 1924 Aux3AmbtColrCtlCstAvlFlg85 "ENM";
BA_ "SignalLongName" SG_ 1924 Aux3AmbtColrCtlCstAvlFlg85 "Auxiliary 3 Ambient Color Control Customization Availability Flag 85";
BA_ "SignalType" SG_ 1924 Aux3AmbtColrCtlCstAvlFlg84 "ENM";
BA_ "SignalLongName" SG_ 1924 Aux3AmbtColrCtlCstAvlFlg84 "Auxiliary 3 Ambient Color Control Customization Availability Flag 84";
BA_ "SignalType" SG_ 1924 Aux3AmbtColrCtlCstAvlFlg83 "ENM";
BA_ "SignalLongName" SG_ 1924 Aux3AmbtColrCtlCstAvlFlg83 "Auxiliary 3 Ambient Color Control Customization Availability Flag 83";
BA_ "SignalType" SG_ 1924 Aux3AmbtColrCtlCstAvlFlg97 "ENM";
BA_ "SignalLongName" SG_ 1924 Aux3AmbtColrCtlCstAvlFlg97 "Auxiliary 3 Ambient Color Control Customization Availability Flag 97";
BA_ "SignalType" SG_ 1924 Aux3AmbtColrCtlCstAvlFlg96 "ENM";
BA_ "SignalLongName" SG_ 1924 Aux3AmbtColrCtlCstAvlFlg96 "Auxiliary 3 Ambient Color Control Customization Availability Flag 96";
BA_ "SignalType" SG_ 1924 Aux3AmbtColrCtlCstAvlFlg95 "ENM";
BA_ "SignalLongName" SG_ 1924 Aux3AmbtColrCtlCstAvlFlg95 "Auxiliary 3 Ambient Color Control Customization Availability Flag 95";
BA_ "SignalType" SG_ 1924 Aux3AmbtColrCtlCstAvlFlg94 "ENM";
BA_ "SignalLongName" SG_ 1924 Aux3AmbtColrCtlCstAvlFlg94 "Auxiliary 3 Ambient Color Control Customization Availability Flag 94";
BA_ "SignalType" SG_ 1924 Aux3AmbtColrCtlCstAvlFlg93 "ENM";
BA_ "SignalLongName" SG_ 1924 Aux3AmbtColrCtlCstAvlFlg93 "Auxiliary 3 Ambient Color Control Customization Availability Flag 93";
BA_ "SignalType" SG_ 1924 Aux3AmbtColrCtlCstAvlFlg92 "ENM";
BA_ "SignalLongName" SG_ 1924 Aux3AmbtColrCtlCstAvlFlg92 "Auxiliary 3 Ambient Color Control Customization Availability Flag 92";
BA_ "SignalType" SG_ 1924 Aux3AmbtColrCtlCstAvlFlg91 "ENM";
BA_ "SignalLongName" SG_ 1924 Aux3AmbtColrCtlCstAvlFlg91 "Auxiliary 3 Ambient Color Control Customization Availability Flag 91";
BA_ "SignalType" SG_ 1924 Aux3AmbtColrCtlCstAvlFlg90 "ENM";
BA_ "SignalLongName" SG_ 1924 Aux3AmbtColrCtlCstAvlFlg90 "Auxiliary 3 Ambient Color Control Customization Availability Flag 90";
BA_ "SignalType" SG_ 1924 CbnAirClnFltrtnCstAvlFlg5 "ENM";
BA_ "SignalLongName" SG_ 1924 CbnAirClnFltrtnCstAvlFlg5 "Cabin Air Clean Filtration Customization Availability Flag 5";
BA_ "SignalType" SG_ 1924 CbnAirClnFltrtnCstAvlFlg4 "ENM";
BA_ "SignalLongName" SG_ 1924 CbnAirClnFltrtnCstAvlFlg4 "Cabin Air Clean Filtration Customization Availability Flag 4";
BA_ "SignalType" SG_ 1924 CbnAirClnFltrtnCstAvlFlg3 "ENM";
BA_ "SignalLongName" SG_ 1924 CbnAirClnFltrtnCstAvlFlg3 "Cabin Air Clean Filtration Customization Availability Flag 3";
BA_ "SignalType" SG_ 1924 CbnAirClnFltrtnCstAvlFlg2 "ENM";
BA_ "SignalLongName" SG_ 1924 CbnAirClnFltrtnCstAvlFlg2 "Cabin Air Clean Filtration Customization Availability Flag 2";
BA_ "SignalType" SG_ 1924 CbnAirClnFltrtnCstAvlFlg1 "ENM";
BA_ "SignalLongName" SG_ 1924 CbnAirClnFltrtnCstAvlFlg1 "Cabin Air Clean Filtration Customization Availability Flag 1";
BA_ "SignalType" SG_ 1924 Aux3AmbtColrCtlCstSetAval "ENM";
BA_ "SignalLongName" SG_ 1924 Aux3AmbtColrCtlCstSetAval "Auxiliary 3 Ambient Color Control Customization Setting Available";
BA_ "SignalType" SG_ 1924 Aux3AmbtColrCtlCstAvlFlg99 "ENM";
BA_ "SignalLongName" SG_ 1924 Aux3AmbtColrCtlCstAvlFlg99 "Auxiliary 3 Ambient Color Control Customization Availability Flag 99";
BA_ "SignalType" SG_ 1924 Aux3AmbtColrCtlCstAvlFlg98 "ENM";
BA_ "SignalLongName" SG_ 1924 Aux3AmbtColrCtlCstAvlFlg98 "Auxiliary 3 Ambient Color Control Customization Availability Flag 98";
BA_ "SignalType" SG_ 1924 HtdArmrstSyncCstAvlFlg5 "ENM";
BA_ "SignalLongName" SG_ 1924 HtdArmrstSyncCstAvlFlg5 "Heated Armrest Sync Customization Availability Flag 5";
BA_ "SignalType" SG_ 1924 HtdArmrstSyncCstAvlFlg4 "ENM";
BA_ "SignalLongName" SG_ 1924 HtdArmrstSyncCstAvlFlg4 "Heated Armrest Sync Customization Availability Flag 4";
BA_ "SignalType" SG_ 1924 HtdArmrstSyncCstAvlFlg3 "ENM";
BA_ "SignalLongName" SG_ 1924 HtdArmrstSyncCstAvlFlg3 "Heated Armrest Sync Customization Availability Flag 3";
BA_ "SignalType" SG_ 1924 HtdArmrstSyncCstAvlFlg2 "ENM";
BA_ "SignalLongName" SG_ 1924 HtdArmrstSyncCstAvlFlg2 "Heated Armrest Sync Customization Availability Flag 2";
BA_ "SignalType" SG_ 1924 HtdArmrstSyncCstAvlFlg1 "ENM";
BA_ "SignalLongName" SG_ 1924 HtdArmrstSyncCstAvlFlg1 "Heated Armrest Sync Customization Availability Flag 1";
BA_ "SignalType" SG_ 1924 CbnAirClnFltrtnCstSetAval "ENM";
BA_ "SignalLongName" SG_ 1924 CbnAirClnFltrtnCstSetAval "Cabin Air Clean Filtration Customization Setting Available";
BA_ "SignalType" SG_ 1924 CbnAirClnFltrtnCstAvlFlg7 "ENM";
BA_ "SignalLongName" SG_ 1924 CbnAirClnFltrtnCstAvlFlg7 "Cabin Air Clean Filtration Customization Availability Flag 7";
BA_ "SignalType" SG_ 1924 CbnAirClnFltrtnCstAvlFlg6 "ENM";
BA_ "SignalLongName" SG_ 1924 CbnAirClnFltrtnCstAvlFlg6 "Cabin Air Clean Filtration Customization Availability Flag 6";
BA_ "SignalType" SG_ 1924 TnDrvrSpdLimRmtCstCurrSetVal "ENM";
BA_ "SignalLongName" SG_ 1924 TnDrvrSpdLimRmtCstCurrSetVal "Teen Driver Speed Limit Remote Customization Current Setting Value";
BA_ "SignalType" SG_ 1924 TnDrvrActvRmtCstCurrSetVal "ENM";
BA_ "SignalLongName" SG_ 1924 TnDrvrActvRmtCstCurrSetVal "Teen Driver Active Remote Customization Current Setting Value";
BA_ "SignalType" SG_ 1924 HtdArmrstSyncCstAvlFlg7 "ENM";
BA_ "SignalLongName" SG_ 1924 HtdArmrstSyncCstAvlFlg7 "Heated Armrest Sync Customization Availability Flag 7";
BA_ "SignalType" SG_ 1924 HtdArmrstSyncCstAvlFlg6 "ENM";
BA_ "SignalLongName" SG_ 1924 HtdArmrstSyncCstAvlFlg6 "Heated Armrest Sync Customization Availability Flag 6";
BA_ "SignalType" SG_ 1925 Aux2AmbtColrCtlCstAvlFlg106 "ENM";
BA_ "SignalLongName" SG_ 1925 Aux2AmbtColrCtlCstAvlFlg106 "Auxiliary 2 Ambient Color Control Customization Availability Flag 106";
BA_ "SignalType" SG_ 1925 Aux2AmbtColrCtlCstAvlFlg105 "ENM";
BA_ "SignalLongName" SG_ 1925 Aux2AmbtColrCtlCstAvlFlg105 "Auxiliary 2 Ambient Color Control Customization Availability Flag 105";
BA_ "SignalType" SG_ 1925 Aux2AmbtColrCtlCstAvlFlg104 "ENM";
BA_ "SignalLongName" SG_ 1925 Aux2AmbtColrCtlCstAvlFlg104 "Auxiliary 2 Ambient Color Control Customization Availability Flag 104";
BA_ "SignalType" SG_ 1925 Aux2AmbtColrCtlCstAvlFlg103 "ENM";
BA_ "SignalLongName" SG_ 1925 Aux2AmbtColrCtlCstAvlFlg103 "Auxiliary 2 Ambient Color Control Customization Availability Flag 103";
BA_ "SignalType" SG_ 1925 Aux2AmbtColrCtlCstAvlFlg102 "ENM";
BA_ "SignalLongName" SG_ 1925 Aux2AmbtColrCtlCstAvlFlg102 "Auxiliary 2 Ambient Color Control Customization Availability Flag 102";
BA_ "SignalType" SG_ 1925 Aux2AmbtColrCtlCstAvlFlg101 "ENM";
BA_ "SignalLongName" SG_ 1925 Aux2AmbtColrCtlCstAvlFlg101 "Auxiliary 2 Ambient Color Control Customization Availability Flag 101";
BA_ "SignalType" SG_ 1925 Aux2AmbtColrCtlCstAvlFlg100 "ENM";
BA_ "SignalLongName" SG_ 1925 Aux2AmbtColrCtlCstAvlFlg100 "Auxiliary 2 Ambient Color Control Customization Availability Flag 100";
BA_ "SignalType" SG_ 1925 Aux2AmbtColrCtlCstAvlFlg10 "ENM";
BA_ "SignalLongName" SG_ 1925 Aux2AmbtColrCtlCstAvlFlg10 "Auxiliary 2 Ambient Color Control Customization Availability Flag 10";
BA_ "SignalType" SG_ 1925 Aux2AmbtColrCtlCstAvlFlg113 "ENM";
BA_ "SignalLongName" SG_ 1925 Aux2AmbtColrCtlCstAvlFlg113 "Auxiliary 2 Ambient Color Control Customization Availability Flag 113";
BA_ "SignalType" SG_ 1925 Aux2AmbtColrCtlCstAvlFlg112 "ENM";
BA_ "SignalLongName" SG_ 1925 Aux2AmbtColrCtlCstAvlFlg112 "Auxiliary 2 Ambient Color Control Customization Availability Flag 112";
BA_ "SignalType" SG_ 1925 Aux2AmbtColrCtlCstAvlFlg111 "ENM";
BA_ "SignalLongName" SG_ 1925 Aux2AmbtColrCtlCstAvlFlg111 "Auxiliary 2 Ambient Color Control Customization Availability Flag 111";
BA_ "SignalType" SG_ 1925 Aux2AmbtColrCtlCstAvlFlg110 "ENM";
BA_ "SignalLongName" SG_ 1925 Aux2AmbtColrCtlCstAvlFlg110 "Auxiliary 2 Ambient Color Control Customization Availability Flag 110";
BA_ "SignalType" SG_ 1925 Aux2AmbtColrCtlCstAvlFlg11 "ENM";
BA_ "SignalLongName" SG_ 1925 Aux2AmbtColrCtlCstAvlFlg11 "Auxiliary 2 Ambient Color Control Customization Availability Flag 11";
BA_ "SignalType" SG_ 1925 Aux2AmbtColrCtlCstAvlFlg109 "ENM";
BA_ "SignalLongName" SG_ 1925 Aux2AmbtColrCtlCstAvlFlg109 "Auxiliary 2 Ambient Color Control Customization Availability Flag 109";
BA_ "SignalType" SG_ 1925 Aux2AmbtColrCtlCstAvlFlg108 "ENM";
BA_ "SignalLongName" SG_ 1925 Aux2AmbtColrCtlCstAvlFlg108 "Auxiliary 2 Ambient Color Control Customization Availability Flag 108";
BA_ "SignalType" SG_ 1925 Aux2AmbtColrCtlCstAvlFlg107 "ENM";
BA_ "SignalLongName" SG_ 1925 Aux2AmbtColrCtlCstAvlFlg107 "Auxiliary 2 Ambient Color Control Customization Availability Flag 107";
BA_ "SignalType" SG_ 1925 Aux2AmbtColrCtlCstAvlFlg120 "ENM";
BA_ "SignalLongName" SG_ 1925 Aux2AmbtColrCtlCstAvlFlg120 "Auxiliary 2 Ambient Color Control Customization Availability Flag 120";
BA_ "SignalType" SG_ 1925 Aux2AmbtColrCtlCstAvlFlg12 "ENM";
BA_ "SignalLongName" SG_ 1925 Aux2AmbtColrCtlCstAvlFlg12 "Auxiliary 2 Ambient Color Control Customization Availability Flag 12";
BA_ "SignalType" SG_ 1925 Aux2AmbtColrCtlCstAvlFlg119 "ENM";
BA_ "SignalLongName" SG_ 1925 Aux2AmbtColrCtlCstAvlFlg119 "Auxiliary 2 Ambient Color Control Customization Availability Flag 119";
BA_ "SignalType" SG_ 1925 Aux2AmbtColrCtlCstAvlFlg118 "ENM";
BA_ "SignalLongName" SG_ 1925 Aux2AmbtColrCtlCstAvlFlg118 "Auxiliary 2 Ambient Color Control Customization Availability Flag 118";
BA_ "SignalType" SG_ 1925 Aux2AmbtColrCtlCstAvlFlg117 "ENM";
BA_ "SignalLongName" SG_ 1925 Aux2AmbtColrCtlCstAvlFlg117 "Auxiliary 2 Ambient Color Control Customization Availability Flag 117";
BA_ "SignalType" SG_ 1925 Aux2AmbtColrCtlCstAvlFlg116 "ENM";
BA_ "SignalLongName" SG_ 1925 Aux2AmbtColrCtlCstAvlFlg116 "Auxiliary 2 Ambient Color Control Customization Availability Flag 116";
BA_ "SignalType" SG_ 1925 Aux2AmbtColrCtlCstAvlFlg115 "ENM";
BA_ "SignalLongName" SG_ 1925 Aux2AmbtColrCtlCstAvlFlg115 "Auxiliary 2 Ambient Color Control Customization Availability Flag 115";
BA_ "SignalType" SG_ 1925 Aux2AmbtColrCtlCstAvlFlg114 "ENM";
BA_ "SignalLongName" SG_ 1925 Aux2AmbtColrCtlCstAvlFlg114 "Auxiliary 2 Ambient Color Control Customization Availability Flag 114";
BA_ "SignalType" SG_ 1925 Aux2AmbtColrCtlCstAvlFlg13 "ENM";
BA_ "SignalLongName" SG_ 1925 Aux2AmbtColrCtlCstAvlFlg13 "Auxiliary 2 Ambient Color Control Customization Availability Flag 13";
BA_ "SignalType" SG_ 1925 Aux2AmbtColrCtlCstAvlFlg127 "ENM";
BA_ "SignalLongName" SG_ 1925 Aux2AmbtColrCtlCstAvlFlg127 "Auxiliary 2 Ambient Color Control Customization Availability Flag 127";
BA_ "SignalType" SG_ 1925 Aux2AmbtColrCtlCstAvlFlg126 "ENM";
BA_ "SignalLongName" SG_ 1925 Aux2AmbtColrCtlCstAvlFlg126 "Auxiliary 2 Ambient Color Control Customization Availability Flag 126";
BA_ "SignalType" SG_ 1925 Aux2AmbtColrCtlCstAvlFlg125 "ENM";
BA_ "SignalLongName" SG_ 1925 Aux2AmbtColrCtlCstAvlFlg125 "Auxiliary 2 Ambient Color Control Customization Availability Flag 125";
BA_ "SignalType" SG_ 1925 Aux2AmbtColrCtlCstAvlFlg124 "ENM";
BA_ "SignalLongName" SG_ 1925 Aux2AmbtColrCtlCstAvlFlg124 "Auxiliary 2 Ambient Color Control Customization Availability Flag 124";
BA_ "SignalType" SG_ 1925 Aux2AmbtColrCtlCstAvlFlg123 "ENM";
BA_ "SignalLongName" SG_ 1925 Aux2AmbtColrCtlCstAvlFlg123 "Auxiliary 2 Ambient Color Control Customization Availability Flag 123";
BA_ "SignalType" SG_ 1925 Aux2AmbtColrCtlCstAvlFlg122 "ENM";
BA_ "SignalLongName" SG_ 1925 Aux2AmbtColrCtlCstAvlFlg122 "Auxiliary 2 Ambient Color Control Customization Availability Flag 122";
BA_ "SignalType" SG_ 1925 Aux2AmbtColrCtlCstAvlFlg121 "ENM";
BA_ "SignalLongName" SG_ 1925 Aux2AmbtColrCtlCstAvlFlg121 "Auxiliary 2 Ambient Color Control Customization Availability Flag 121";
BA_ "SignalType" SG_ 1925 Aux2AmbtColrCtlCstAvlFlg20 "ENM";
BA_ "SignalLongName" SG_ 1925 Aux2AmbtColrCtlCstAvlFlg20 "Auxiliary 2 Ambient Color Control Customization Availability Flag 20";
BA_ "SignalType" SG_ 1925 Aux2AmbtColrCtlCstAvlFlg2 "ENM";
BA_ "SignalLongName" SG_ 1925 Aux2AmbtColrCtlCstAvlFlg2 "Auxiliary 2 Ambient Color Control Customization Availability Flag 2";
BA_ "SignalType" SG_ 1925 Aux2AmbtColrCtlCstAvlFlg19 "ENM";
BA_ "SignalLongName" SG_ 1925 Aux2AmbtColrCtlCstAvlFlg19 "Auxiliary 2 Ambient Color Control Customization Availability Flag 19";
BA_ "SignalType" SG_ 1925 Aux2AmbtColrCtlCstAvlFlg18 "ENM";
BA_ "SignalLongName" SG_ 1925 Aux2AmbtColrCtlCstAvlFlg18 "Auxiliary 2 Ambient Color Control Customization Availability Flag 18";
BA_ "SignalType" SG_ 1925 Aux2AmbtColrCtlCstAvlFlg17 "ENM";
BA_ "SignalLongName" SG_ 1925 Aux2AmbtColrCtlCstAvlFlg17 "Auxiliary 2 Ambient Color Control Customization Availability Flag 17";
BA_ "SignalType" SG_ 1925 Aux2AmbtColrCtlCstAvlFlg16 "ENM";
BA_ "SignalLongName" SG_ 1925 Aux2AmbtColrCtlCstAvlFlg16 "Auxiliary 2 Ambient Color Control Customization Availability Flag 16";
BA_ "SignalType" SG_ 1925 Aux2AmbtColrCtlCstAvlFlg15 "ENM";
BA_ "SignalLongName" SG_ 1925 Aux2AmbtColrCtlCstAvlFlg15 "Auxiliary 2 Ambient Color Control Customization Availability Flag 15";
BA_ "SignalType" SG_ 1925 Aux2AmbtColrCtlCstAvlFlg14 "ENM";
BA_ "SignalLongName" SG_ 1925 Aux2AmbtColrCtlCstAvlFlg14 "Auxiliary 2 Ambient Color Control Customization Availability Flag 14";
BA_ "SignalType" SG_ 1925 Aux2AmbtColrCtlCstAvlFlg28 "ENM";
BA_ "SignalLongName" SG_ 1925 Aux2AmbtColrCtlCstAvlFlg28 "Auxiliary 2 Ambient Color Control Customization Availability Flag 28";
BA_ "SignalType" SG_ 1925 Aux2AmbtColrCtlCstAvlFlg27 "ENM";
BA_ "SignalLongName" SG_ 1925 Aux2AmbtColrCtlCstAvlFlg27 "Auxiliary 2 Ambient Color Control Customization Availability Flag 27";
BA_ "SignalType" SG_ 1925 Aux2AmbtColrCtlCstAvlFlg26 "ENM";
BA_ "SignalLongName" SG_ 1925 Aux2AmbtColrCtlCstAvlFlg26 "Auxiliary 2 Ambient Color Control Customization Availability Flag 26";
BA_ "SignalType" SG_ 1925 Aux2AmbtColrCtlCstAvlFlg25 "ENM";
BA_ "SignalLongName" SG_ 1925 Aux2AmbtColrCtlCstAvlFlg25 "Auxiliary 2 Ambient Color Control Customization Availability Flag 25";
BA_ "SignalType" SG_ 1925 Aux2AmbtColrCtlCstAvlFlg24 "ENM";
BA_ "SignalLongName" SG_ 1925 Aux2AmbtColrCtlCstAvlFlg24 "Auxiliary 2 Ambient Color Control Customization Availability Flag 24";
BA_ "SignalType" SG_ 1925 Aux2AmbtColrCtlCstAvlFlg23 "ENM";
BA_ "SignalLongName" SG_ 1925 Aux2AmbtColrCtlCstAvlFlg23 "Auxiliary 2 Ambient Color Control Customization Availability Flag 23";
BA_ "SignalType" SG_ 1925 Aux2AmbtColrCtlCstAvlFlg22 "ENM";
BA_ "SignalLongName" SG_ 1925 Aux2AmbtColrCtlCstAvlFlg22 "Auxiliary 2 Ambient Color Control Customization Availability Flag 22";
BA_ "SignalType" SG_ 1925 Aux2AmbtColrCtlCstAvlFlg21 "ENM";
BA_ "SignalLongName" SG_ 1925 Aux2AmbtColrCtlCstAvlFlg21 "Auxiliary 2 Ambient Color Control Customization Availability Flag 21";
BA_ "SignalType" SG_ 1925 Aux2AmbtColrCtlCstAvlFlg35 "ENM";
BA_ "SignalLongName" SG_ 1925 Aux2AmbtColrCtlCstAvlFlg35 "Auxiliary 2 Ambient Color Control Customization Availability Flag 35";
BA_ "SignalType" SG_ 1925 Aux2AmbtColrCtlCstAvlFlg34 "ENM";
BA_ "SignalLongName" SG_ 1925 Aux2AmbtColrCtlCstAvlFlg34 "Auxiliary 2 Ambient Color Control Customization Availability Flag 34";
BA_ "SignalType" SG_ 1925 Aux2AmbtColrCtlCstAvlFlg33 "ENM";
BA_ "SignalLongName" SG_ 1925 Aux2AmbtColrCtlCstAvlFlg33 "Auxiliary 2 Ambient Color Control Customization Availability Flag 33";
BA_ "SignalType" SG_ 1925 Aux2AmbtColrCtlCstAvlFlg32 "ENM";
BA_ "SignalLongName" SG_ 1925 Aux2AmbtColrCtlCstAvlFlg32 "Auxiliary 2 Ambient Color Control Customization Availability Flag 32";
BA_ "SignalType" SG_ 1925 Aux2AmbtColrCtlCstAvlFlg31 "ENM";
BA_ "SignalLongName" SG_ 1925 Aux2AmbtColrCtlCstAvlFlg31 "Auxiliary 2 Ambient Color Control Customization Availability Flag 31";
BA_ "SignalType" SG_ 1925 Aux2AmbtColrCtlCstAvlFlg30 "ENM";
BA_ "SignalLongName" SG_ 1925 Aux2AmbtColrCtlCstAvlFlg30 "Auxiliary 2 Ambient Color Control Customization Availability Flag 30";
BA_ "SignalType" SG_ 1925 Aux2AmbtColrCtlCstAvlFlg3 "ENM";
BA_ "SignalLongName" SG_ 1925 Aux2AmbtColrCtlCstAvlFlg3 "Auxiliary 2 Ambient Color Control Customization Availability Flag 3";
BA_ "SignalType" SG_ 1925 Aux2AmbtColrCtlCstAvlFlg29 "ENM";
BA_ "SignalLongName" SG_ 1925 Aux2AmbtColrCtlCstAvlFlg29 "Auxiliary 2 Ambient Color Control Customization Availability Flag 29";
BA_ "SignalType" SG_ 1925 Aux2AmbtColrCtlCstAvlFlg42 "ENM";
BA_ "SignalLongName" SG_ 1925 Aux2AmbtColrCtlCstAvlFlg42 "Auxiliary 2 Ambient Color Control Customization Availability Flag 42";
BA_ "SignalType" SG_ 1925 Aux2AmbtColrCtlCstAvlFlg41 "ENM";
BA_ "SignalLongName" SG_ 1925 Aux2AmbtColrCtlCstAvlFlg41 "Auxiliary 2 Ambient Color Control Customization Availability Flag 41";
BA_ "SignalType" SG_ 1925 Aux2AmbtColrCtlCstAvlFlg40 "ENM";
BA_ "SignalLongName" SG_ 1925 Aux2AmbtColrCtlCstAvlFlg40 "Auxiliary 2 Ambient Color Control Customization Availability Flag 40";
BA_ "SignalType" SG_ 1925 Aux2AmbtColrCtlCstAvlFlg4 "ENM";
BA_ "SignalLongName" SG_ 1925 Aux2AmbtColrCtlCstAvlFlg4 "Auxiliary 2 Ambient Color Control Customization Availability Flag 4";
BA_ "SignalType" SG_ 1925 Aux2AmbtColrCtlCstAvlFlg39 "ENM";
BA_ "SignalLongName" SG_ 1925 Aux2AmbtColrCtlCstAvlFlg39 "Auxiliary 2 Ambient Color Control Customization Availability Flag 39";
BA_ "SignalType" SG_ 1925 Aux2AmbtColrCtlCstAvlFlg38 "ENM";
BA_ "SignalLongName" SG_ 1925 Aux2AmbtColrCtlCstAvlFlg38 "Auxiliary 2 Ambient Color Control Customization Availability Flag 38";
BA_ "SignalType" SG_ 1925 Aux2AmbtColrCtlCstAvlFlg37 "ENM";
BA_ "SignalLongName" SG_ 1925 Aux2AmbtColrCtlCstAvlFlg37 "Auxiliary 2 Ambient Color Control Customization Availability Flag 37";
BA_ "SignalType" SG_ 1925 Aux2AmbtColrCtlCstAvlFlg36 "ENM";
BA_ "SignalLongName" SG_ 1925 Aux2AmbtColrCtlCstAvlFlg36 "Auxiliary 2 Ambient Color Control Customization Availability Flag 36";
BA_ "SignalType" SG_ 1926 Aux2AmbtColrCtlCstAvlFlg5 "ENM";
BA_ "SignalLongName" SG_ 1926 Aux2AmbtColrCtlCstAvlFlg5 "Auxiliary 2 Ambient Color Control Customization Availability Flag 5";
BA_ "SignalType" SG_ 1926 Aux2AmbtColrCtlCstAvlFlg49 "ENM";
BA_ "SignalLongName" SG_ 1926 Aux2AmbtColrCtlCstAvlFlg49 "Auxiliary 2 Ambient Color Control Customization Availability Flag 49";
BA_ "SignalType" SG_ 1926 Aux2AmbtColrCtlCstAvlFlg48 "ENM";
BA_ "SignalLongName" SG_ 1926 Aux2AmbtColrCtlCstAvlFlg48 "Auxiliary 2 Ambient Color Control Customization Availability Flag 48";
BA_ "SignalType" SG_ 1926 Aux2AmbtColrCtlCstAvlFlg47 "ENM";
BA_ "SignalLongName" SG_ 1926 Aux2AmbtColrCtlCstAvlFlg47 "Auxiliary 2 Ambient Color Control Customization Availability Flag 47";
BA_ "SignalType" SG_ 1926 Aux2AmbtColrCtlCstAvlFlg46 "ENM";
BA_ "SignalLongName" SG_ 1926 Aux2AmbtColrCtlCstAvlFlg46 "Auxiliary 2 Ambient Color Control Customization Availability Flag 46";
BA_ "SignalType" SG_ 1926 Aux2AmbtColrCtlCstAvlFlg45 "ENM";
BA_ "SignalLongName" SG_ 1926 Aux2AmbtColrCtlCstAvlFlg45 "Auxiliary 2 Ambient Color Control Customization Availability Flag 45";
BA_ "SignalType" SG_ 1926 Aux2AmbtColrCtlCstAvlFlg44 "ENM";
BA_ "SignalLongName" SG_ 1926 Aux2AmbtColrCtlCstAvlFlg44 "Auxiliary 2 Ambient Color Control Customization Availability Flag 44";
BA_ "SignalType" SG_ 1926 Aux2AmbtColrCtlCstAvlFlg43 "ENM";
BA_ "SignalLongName" SG_ 1926 Aux2AmbtColrCtlCstAvlFlg43 "Auxiliary 2 Ambient Color Control Customization Availability Flag 43";
BA_ "SignalType" SG_ 1926 Aux2AmbtColrCtlCstAvlFlg57 "ENM";
BA_ "SignalLongName" SG_ 1926 Aux2AmbtColrCtlCstAvlFlg57 "Auxiliary 2 Ambient Color Control Customization Availability Flag 57";
BA_ "SignalType" SG_ 1926 Aux2AmbtColrCtlCstAvlFlg56 "ENM";
BA_ "SignalLongName" SG_ 1926 Aux2AmbtColrCtlCstAvlFlg56 "Auxiliary 2 Ambient Color Control Customization Availability Flag 56";
BA_ "SignalType" SG_ 1926 Aux2AmbtColrCtlCstAvlFlg55 "ENM";
BA_ "SignalLongName" SG_ 1926 Aux2AmbtColrCtlCstAvlFlg55 "Auxiliary 2 Ambient Color Control Customization Availability Flag 55";
BA_ "SignalType" SG_ 1926 Aux2AmbtColrCtlCstAvlFlg54 "ENM";
BA_ "SignalLongName" SG_ 1926 Aux2AmbtColrCtlCstAvlFlg54 "Auxiliary 2 Ambient Color Control Customization Availability Flag 54";
BA_ "SignalType" SG_ 1926 Aux2AmbtColrCtlCstAvlFlg53 "ENM";
BA_ "SignalLongName" SG_ 1926 Aux2AmbtColrCtlCstAvlFlg53 "Auxiliary 2 Ambient Color Control Customization Availability Flag 53";
BA_ "SignalType" SG_ 1926 Aux2AmbtColrCtlCstAvlFlg52 "ENM";
BA_ "SignalLongName" SG_ 1926 Aux2AmbtColrCtlCstAvlFlg52 "Auxiliary 2 Ambient Color Control Customization Availability Flag 52";
BA_ "SignalType" SG_ 1926 Aux2AmbtColrCtlCstAvlFlg51 "ENM";
BA_ "SignalLongName" SG_ 1926 Aux2AmbtColrCtlCstAvlFlg51 "Auxiliary 2 Ambient Color Control Customization Availability Flag 51";
BA_ "SignalType" SG_ 1926 Aux2AmbtColrCtlCstAvlFlg50 "ENM";
BA_ "SignalLongName" SG_ 1926 Aux2AmbtColrCtlCstAvlFlg50 "Auxiliary 2 Ambient Color Control Customization Availability Flag 50";
BA_ "SignalType" SG_ 1926 Aux2AmbtColrCtlCstAvlFlg64 "ENM";
BA_ "SignalLongName" SG_ 1926 Aux2AmbtColrCtlCstAvlFlg64 "Auxiliary 2 Ambient Color Control Customization Availability Flag 64";
BA_ "SignalType" SG_ 1926 Aux2AmbtColrCtlCstAvlFlg63 "ENM";
BA_ "SignalLongName" SG_ 1926 Aux2AmbtColrCtlCstAvlFlg63 "Auxiliary 2 Ambient Color Control Customization Availability Flag 63";
BA_ "SignalType" SG_ 1926 Aux2AmbtColrCtlCstAvlFlg62 "ENM";
BA_ "SignalLongName" SG_ 1926 Aux2AmbtColrCtlCstAvlFlg62 "Auxiliary 2 Ambient Color Control Customization Availability Flag 62";
BA_ "SignalType" SG_ 1926 Aux2AmbtColrCtlCstAvlFlg61 "ENM";
BA_ "SignalLongName" SG_ 1926 Aux2AmbtColrCtlCstAvlFlg61 "Auxiliary 2 Ambient Color Control Customization Availability Flag 61";
BA_ "SignalType" SG_ 1926 Aux2AmbtColrCtlCstAvlFlg60 "ENM";
BA_ "SignalLongName" SG_ 1926 Aux2AmbtColrCtlCstAvlFlg60 "Auxiliary 2 Ambient Color Control Customization Availability Flag 60";
BA_ "SignalType" SG_ 1926 Aux2AmbtColrCtlCstAvlFlg6 "ENM";
BA_ "SignalLongName" SG_ 1926 Aux2AmbtColrCtlCstAvlFlg6 "Auxiliary 2 Ambient Color Control Customization Availability Flag 6";
BA_ "SignalType" SG_ 1926 Aux2AmbtColrCtlCstAvlFlg59 "ENM";
BA_ "SignalLongName" SG_ 1926 Aux2AmbtColrCtlCstAvlFlg59 "Auxiliary 2 Ambient Color Control Customization Availability Flag 59";
BA_ "SignalType" SG_ 1926 Aux2AmbtColrCtlCstAvlFlg58 "ENM";
BA_ "SignalLongName" SG_ 1926 Aux2AmbtColrCtlCstAvlFlg58 "Auxiliary 2 Ambient Color Control Customization Availability Flag 58";
BA_ "SignalType" SG_ 1926 Aux2AmbtColrCtlCstAvlFlg71 "ENM";
BA_ "SignalLongName" SG_ 1926 Aux2AmbtColrCtlCstAvlFlg71 "Auxiliary 2 Ambient Color Control Customization Availability Flag 71";
BA_ "SignalType" SG_ 1926 Aux2AmbtColrCtlCstAvlFlg70 "ENM";
BA_ "SignalLongName" SG_ 1926 Aux2AmbtColrCtlCstAvlFlg70 "Auxiliary 2 Ambient Color Control Customization Availability Flag 70";
BA_ "SignalType" SG_ 1926 Aux2AmbtColrCtlCstAvlFlg7 "ENM";
BA_ "SignalLongName" SG_ 1926 Aux2AmbtColrCtlCstAvlFlg7 "Auxiliary 2 Ambient Color Control Customization Availability Flag 7";
BA_ "SignalType" SG_ 1926 Aux2AmbtColrCtlCstAvlFlg69 "ENM";
BA_ "SignalLongName" SG_ 1926 Aux2AmbtColrCtlCstAvlFlg69 "Auxiliary 2 Ambient Color Control Customization Availability Flag 69";
BA_ "SignalType" SG_ 1926 Aux2AmbtColrCtlCstAvlFlg68 "ENM";
BA_ "SignalLongName" SG_ 1926 Aux2AmbtColrCtlCstAvlFlg68 "Auxiliary 2 Ambient Color Control Customization Availability Flag 68";
BA_ "SignalType" SG_ 1926 Aux2AmbtColrCtlCstAvlFlg67 "ENM";
BA_ "SignalLongName" SG_ 1926 Aux2AmbtColrCtlCstAvlFlg67 "Auxiliary 2 Ambient Color Control Customization Availability Flag 67";
BA_ "SignalType" SG_ 1926 Aux2AmbtColrCtlCstAvlFlg66 "ENM";
BA_ "SignalLongName" SG_ 1926 Aux2AmbtColrCtlCstAvlFlg66 "Auxiliary 2 Ambient Color Control Customization Availability Flag 66";
BA_ "SignalType" SG_ 1926 Aux2AmbtColrCtlCstAvlFlg65 "ENM";
BA_ "SignalLongName" SG_ 1926 Aux2AmbtColrCtlCstAvlFlg65 "Auxiliary 2 Ambient Color Control Customization Availability Flag 65";
BA_ "SignalType" SG_ 1926 Aux2AmbtColrCtlCstAvlFlg79 "ENM";
BA_ "SignalLongName" SG_ 1926 Aux2AmbtColrCtlCstAvlFlg79 "Auxiliary 2 Ambient Color Control Customization Availability Flag 79";
BA_ "SignalType" SG_ 1926 Aux2AmbtColrCtlCstAvlFlg78 "ENM";
BA_ "SignalLongName" SG_ 1926 Aux2AmbtColrCtlCstAvlFlg78 "Auxiliary 2 Ambient Color Control Customization Availability Flag 78";
BA_ "SignalType" SG_ 1926 Aux2AmbtColrCtlCstAvlFlg77 "ENM";
BA_ "SignalLongName" SG_ 1926 Aux2AmbtColrCtlCstAvlFlg77 "Auxiliary 2 Ambient Color Control Customization Availability Flag 77";
BA_ "SignalType" SG_ 1926 Aux2AmbtColrCtlCstAvlFlg76 "ENM";
BA_ "SignalLongName" SG_ 1926 Aux2AmbtColrCtlCstAvlFlg76 "Auxiliary 2 Ambient Color Control Customization Availability Flag 76";
BA_ "SignalType" SG_ 1926 Aux2AmbtColrCtlCstAvlFlg75 "ENM";
BA_ "SignalLongName" SG_ 1926 Aux2AmbtColrCtlCstAvlFlg75 "Auxiliary 2 Ambient Color Control Customization Availability Flag 75";
BA_ "SignalType" SG_ 1926 Aux2AmbtColrCtlCstAvlFlg74 "ENM";
BA_ "SignalLongName" SG_ 1926 Aux2AmbtColrCtlCstAvlFlg74 "Auxiliary 2 Ambient Color Control Customization Availability Flag 74";
BA_ "SignalType" SG_ 1926 Aux2AmbtColrCtlCstAvlFlg73 "ENM";
BA_ "SignalLongName" SG_ 1926 Aux2AmbtColrCtlCstAvlFlg73 "Auxiliary 2 Ambient Color Control Customization Availability Flag 73";
BA_ "SignalType" SG_ 1926 Aux2AmbtColrCtlCstAvlFlg72 "ENM";
BA_ "SignalLongName" SG_ 1926 Aux2AmbtColrCtlCstAvlFlg72 "Auxiliary 2 Ambient Color Control Customization Availability Flag 72";
BA_ "SignalType" SG_ 1926 Aux2AmbtColrCtlCstAvlFlg86 "ENM";
BA_ "SignalLongName" SG_ 1926 Aux2AmbtColrCtlCstAvlFlg86 "Auxiliary 2 Ambient Color Control Customization Availability Flag 86";
BA_ "SignalType" SG_ 1926 Aux2AmbtColrCtlCstAvlFlg85 "ENM";
BA_ "SignalLongName" SG_ 1926 Aux2AmbtColrCtlCstAvlFlg85 "Auxiliary 2 Ambient Color Control Customization Availability Flag 85";
BA_ "SignalType" SG_ 1926 Aux2AmbtColrCtlCstAvlFlg84 "ENM";
BA_ "SignalLongName" SG_ 1926 Aux2AmbtColrCtlCstAvlFlg84 "Auxiliary 2 Ambient Color Control Customization Availability Flag 84";
BA_ "SignalType" SG_ 1926 Aux2AmbtColrCtlCstAvlFlg83 "ENM";
BA_ "SignalLongName" SG_ 1926 Aux2AmbtColrCtlCstAvlFlg83 "Auxiliary 2 Ambient Color Control Customization Availability Flag 83";
BA_ "SignalType" SG_ 1926 Aux2AmbtColrCtlCstAvlFlg82 "ENM";
BA_ "SignalLongName" SG_ 1926 Aux2AmbtColrCtlCstAvlFlg82 "Auxiliary 2 Ambient Color Control Customization Availability Flag 82";
BA_ "SignalType" SG_ 1926 Aux2AmbtColrCtlCstAvlFlg81 "ENM";
BA_ "SignalLongName" SG_ 1926 Aux2AmbtColrCtlCstAvlFlg81 "Auxiliary 2 Ambient Color Control Customization Availability Flag 81";
BA_ "SignalType" SG_ 1926 Aux2AmbtColrCtlCstAvlFlg80 "ENM";
BA_ "SignalLongName" SG_ 1926 Aux2AmbtColrCtlCstAvlFlg80 "Auxiliary 2 Ambient Color Control Customization Availability Flag 80";
BA_ "SignalType" SG_ 1926 Aux2AmbtColrCtlCstAvlFlg8 "ENM";
BA_ "SignalLongName" SG_ 1926 Aux2AmbtColrCtlCstAvlFlg8 "Auxiliary 2 Ambient Color Control Customization Availability Flag 8";
BA_ "SignalType" SG_ 1926 Aux2AmbtColrCtlCstAvlFlg93 "ENM";
BA_ "SignalLongName" SG_ 1926 Aux2AmbtColrCtlCstAvlFlg93 "Auxiliary 2 Ambient Color Control Customization Availability Flag 93";
BA_ "SignalType" SG_ 1926 Aux2AmbtColrCtlCstAvlFlg92 "ENM";
BA_ "SignalLongName" SG_ 1926 Aux2AmbtColrCtlCstAvlFlg92 "Auxiliary 2 Ambient Color Control Customization Availability Flag 92";
BA_ "SignalType" SG_ 1926 Aux2AmbtColrCtlCstAvlFlg91 "ENM";
BA_ "SignalLongName" SG_ 1926 Aux2AmbtColrCtlCstAvlFlg91 "Auxiliary 2 Ambient Color Control Customization Availability Flag 91";
BA_ "SignalType" SG_ 1926 Aux2AmbtColrCtlCstAvlFlg90 "ENM";
BA_ "SignalLongName" SG_ 1926 Aux2AmbtColrCtlCstAvlFlg90 "Auxiliary 2 Ambient Color Control Customization Availability Flag 90";
BA_ "SignalType" SG_ 1926 Aux2AmbtColrCtlCstAvlFlg9 "ENM";
BA_ "SignalLongName" SG_ 1926 Aux2AmbtColrCtlCstAvlFlg9 "Auxiliary 2 Ambient Color Control Customization Availability Flag 9";
BA_ "SignalType" SG_ 1926 Aux2AmbtColrCtlCstAvlFlg89 "ENM";
BA_ "SignalLongName" SG_ 1926 Aux2AmbtColrCtlCstAvlFlg89 "Auxiliary 2 Ambient Color Control Customization Availability Flag 89";
BA_ "SignalType" SG_ 1926 Aux2AmbtColrCtlCstAvlFlg88 "ENM";
BA_ "SignalLongName" SG_ 1926 Aux2AmbtColrCtlCstAvlFlg88 "Auxiliary 2 Ambient Color Control Customization Availability Flag 88";
BA_ "SignalType" SG_ 1926 Aux2AmbtColrCtlCstAvlFlg87 "ENM";
BA_ "SignalLongName" SG_ 1926 Aux2AmbtColrCtlCstAvlFlg87 "Auxiliary 2 Ambient Color Control Customization Availability Flag 87";
BA_ "SignalType" SG_ 1926 Aux3AmbtAnmCtlCstAvlFlg1 "ENM";
BA_ "SignalLongName" SG_ 1926 Aux3AmbtAnmCtlCstAvlFlg1 "Auxiliary 3 Ambient Animation Control Customization Availability Flag 1";
BA_ "SignalType" SG_ 1926 Aux2AmbtColrCtlCstSetAval "ENM";
BA_ "SignalLongName" SG_ 1926 Aux2AmbtColrCtlCstSetAval "Auxiliary 2 Ambient Color Control Customization Setting Available";
BA_ "SignalType" SG_ 1926 Aux2AmbtColrCtlCstAvlFlg99 "ENM";
BA_ "SignalLongName" SG_ 1926 Aux2AmbtColrCtlCstAvlFlg99 "Auxiliary 2 Ambient Color Control Customization Availability Flag 99";
BA_ "SignalType" SG_ 1926 Aux2AmbtColrCtlCstAvlFlg98 "ENM";
BA_ "SignalLongName" SG_ 1926 Aux2AmbtColrCtlCstAvlFlg98 "Auxiliary 2 Ambient Color Control Customization Availability Flag 98";
BA_ "SignalType" SG_ 1926 Aux2AmbtColrCtlCstAvlFlg97 "ENM";
BA_ "SignalLongName" SG_ 1926 Aux2AmbtColrCtlCstAvlFlg97 "Auxiliary 2 Ambient Color Control Customization Availability Flag 97";
BA_ "SignalType" SG_ 1926 Aux2AmbtColrCtlCstAvlFlg96 "ENM";
BA_ "SignalLongName" SG_ 1926 Aux2AmbtColrCtlCstAvlFlg96 "Auxiliary 2 Ambient Color Control Customization Availability Flag 96";
BA_ "SignalType" SG_ 1926 Aux2AmbtColrCtlCstAvlFlg95 "ENM";
BA_ "SignalLongName" SG_ 1926 Aux2AmbtColrCtlCstAvlFlg95 "Auxiliary 2 Ambient Color Control Customization Availability Flag 95";
BA_ "SignalType" SG_ 1926 Aux2AmbtColrCtlCstAvlFlg94 "ENM";
BA_ "SignalLongName" SG_ 1926 Aux2AmbtColrCtlCstAvlFlg94 "Auxiliary 2 Ambient Color Control Customization Availability Flag 94";
BA_ "SignalType" SG_ 1132 Aux3AmbtAnmCtlCstAvlFlg3 "ENM";
BA_ "SignalLongName" SG_ 1132 Aux3AmbtAnmCtlCstAvlFlg3 "Auxiliary 3 Ambient Animation Control Customization Availability Flag 3";
BA_ "SignalType" SG_ 1132 Aux3AmbtAnmCtlCstAvlFlg2 "ENM";
BA_ "SignalLongName" SG_ 1132 Aux3AmbtAnmCtlCstAvlFlg2 "Auxiliary 3 Ambient Animation Control Customization Availability Flag 2";
BA_ "SignalType" SG_ 1132 Aux3AmbtAnmCtlCstAvlFlg15 "ENM";
BA_ "SignalLongName" SG_ 1132 Aux3AmbtAnmCtlCstAvlFlg15 "Auxiliary 3 Ambient Animation Control Customization Availability Flag 15";
BA_ "SignalType" SG_ 1132 Aux3AmbtAnmCtlCstAvlFlg14 "ENM";
BA_ "SignalLongName" SG_ 1132 Aux3AmbtAnmCtlCstAvlFlg14 "Auxiliary 3 Ambient Animation Control Customization Availability Flag 14";
BA_ "SignalType" SG_ 1132 Aux3AmbtAnmCtlCstAvlFlg13 "ENM";
BA_ "SignalLongName" SG_ 1132 Aux3AmbtAnmCtlCstAvlFlg13 "Auxiliary 3 Ambient Animation Control Customization Availability Flag 13";
BA_ "SignalType" SG_ 1132 Aux3AmbtAnmCtlCstAvlFlg12 "ENM";
BA_ "SignalLongName" SG_ 1132 Aux3AmbtAnmCtlCstAvlFlg12 "Auxiliary 3 Ambient Animation Control Customization Availability Flag 12";
BA_ "SignalType" SG_ 1132 Aux3AmbtAnmCtlCstAvlFlg11 "ENM";
BA_ "SignalLongName" SG_ 1132 Aux3AmbtAnmCtlCstAvlFlg11 "Auxiliary 3 Ambient Animation Control Customization Availability Flag 11";
BA_ "SignalType" SG_ 1132 Aux3AmbtAnmCtlCstAvlFlg10 "ENM";
BA_ "SignalLongName" SG_ 1132 Aux3AmbtAnmCtlCstAvlFlg10 "Auxiliary 3 Ambient Animation Control Customization Availability Flag 10";
BA_ "SignalType" SG_ 1132 Aux3AmbtBrghtnsCtlCstAvlFlg1 "ENM";
BA_ "SignalLongName" SG_ 1132 Aux3AmbtBrghtnsCtlCstAvlFlg1 "Auxiliary 3 Ambient Brightness Control Customization Availability Flag 1";
BA_ "SignalType" SG_ 1132 Aux3AmbtAnmCtlCstSetAval "ENM";
BA_ "SignalLongName" SG_ 1132 Aux3AmbtAnmCtlCstSetAval "Auxiliary 3 Ambient Animation Control Customization Setting Available";
BA_ "SignalType" SG_ 1132 Aux3AmbtAnmCtlCstAvlFlg9 "ENM";
BA_ "SignalLongName" SG_ 1132 Aux3AmbtAnmCtlCstAvlFlg9 "Auxiliary 3 Ambient Animation Control Customization Availability Flag 9";
BA_ "SignalType" SG_ 1132 Aux3AmbtAnmCtlCstAvlFlg8 "ENM";
BA_ "SignalLongName" SG_ 1132 Aux3AmbtAnmCtlCstAvlFlg8 "Auxiliary 3 Ambient Animation Control Customization Availability Flag 8";
BA_ "SignalType" SG_ 1132 Aux3AmbtAnmCtlCstAvlFlg7 "ENM";
BA_ "SignalLongName" SG_ 1132 Aux3AmbtAnmCtlCstAvlFlg7 "Auxiliary 3 Ambient Animation Control Customization Availability Flag 7";
BA_ "SignalType" SG_ 1132 Aux3AmbtAnmCtlCstAvlFlg6 "ENM";
BA_ "SignalLongName" SG_ 1132 Aux3AmbtAnmCtlCstAvlFlg6 "Auxiliary 3 Ambient Animation Control Customization Availability Flag 6";
BA_ "SignalType" SG_ 1132 Aux3AmbtAnmCtlCstAvlFlg5 "ENM";
BA_ "SignalLongName" SG_ 1132 Aux3AmbtAnmCtlCstAvlFlg5 "Auxiliary 3 Ambient Animation Control Customization Availability Flag 5";
BA_ "SignalType" SG_ 1132 Aux3AmbtAnmCtlCstAvlFlg4 "ENM";
BA_ "SignalLongName" SG_ 1132 Aux3AmbtAnmCtlCstAvlFlg4 "Auxiliary 3 Ambient Animation Control Customization Availability Flag 4";
BA_ "SignalType" SG_ 1132 Aux3AmbtColrCtlCstAvlFlg1 "ENM";
BA_ "SignalLongName" SG_ 1132 Aux3AmbtColrCtlCstAvlFlg1 "Auxiliary 3 Ambient Color Control Customization Availability Flag 1";
BA_ "SignalType" SG_ 1132 Aux3AmbtBrghtnsCtlCstSetAval "ENM";
BA_ "SignalLongName" SG_ 1132 Aux3AmbtBrghtnsCtlCstSetAval "Auxiliary 3 Ambient Brightness Control Customization Setting Available";
BA_ "SignalType" SG_ 1132 Aux3AmbtBrghtnsCtlCstAvlFlg7 "ENM";
BA_ "SignalLongName" SG_ 1132 Aux3AmbtBrghtnsCtlCstAvlFlg7 "Auxiliary 3 Ambient Brightness Control Customization Availability Flag 7";
BA_ "SignalType" SG_ 1132 Aux3AmbtBrghtnsCtlCstAvlFlg6 "ENM";
BA_ "SignalLongName" SG_ 1132 Aux3AmbtBrghtnsCtlCstAvlFlg6 "Auxiliary 3 Ambient Brightness Control Customization Availability Flag 6";
BA_ "SignalType" SG_ 1132 Aux3AmbtBrghtnsCtlCstAvlFlg5 "ENM";
BA_ "SignalLongName" SG_ 1132 Aux3AmbtBrghtnsCtlCstAvlFlg5 "Auxiliary 3 Ambient Brightness Control Customization Availability Flag 5";
BA_ "SignalType" SG_ 1132 Aux3AmbtBrghtnsCtlCstAvlFlg4 "ENM";
BA_ "SignalLongName" SG_ 1132 Aux3AmbtBrghtnsCtlCstAvlFlg4 "Auxiliary 3 Ambient Brightness Control Customization Availability Flag 4";
BA_ "SignalType" SG_ 1132 Aux3AmbtBrghtnsCtlCstAvlFlg3 "ENM";
BA_ "SignalLongName" SG_ 1132 Aux3AmbtBrghtnsCtlCstAvlFlg3 "Auxiliary 3 Ambient Brightness Control Customization Availability Flag 3";
BA_ "SignalType" SG_ 1132 Aux3AmbtBrghtnsCtlCstAvlFlg2 "ENM";
BA_ "SignalLongName" SG_ 1132 Aux3AmbtBrghtnsCtlCstAvlFlg2 "Auxiliary 3 Ambient Brightness Control Customization Availability Flag 2";
BA_ "SignalType" SG_ 1132 Aux3AmbtColrCtlCstAvlFlg106 "ENM";
BA_ "SignalLongName" SG_ 1132 Aux3AmbtColrCtlCstAvlFlg106 "Auxiliary 3 Ambient Color Control Customization Availability Flag 106";
BA_ "SignalType" SG_ 1132 Aux3AmbtColrCtlCstAvlFlg105 "ENM";
BA_ "SignalLongName" SG_ 1132 Aux3AmbtColrCtlCstAvlFlg105 "Auxiliary 3 Ambient Color Control Customization Availability Flag 105";
BA_ "SignalType" SG_ 1132 Aux3AmbtColrCtlCstAvlFlg104 "ENM";
BA_ "SignalLongName" SG_ 1132 Aux3AmbtColrCtlCstAvlFlg104 "Auxiliary 3 Ambient Color Control Customization Availability Flag 104";
BA_ "SignalType" SG_ 1132 Aux3AmbtColrCtlCstAvlFlg103 "ENM";
BA_ "SignalLongName" SG_ 1132 Aux3AmbtColrCtlCstAvlFlg103 "Auxiliary 3 Ambient Color Control Customization Availability Flag 103";
BA_ "SignalType" SG_ 1132 Aux3AmbtColrCtlCstAvlFlg102 "ENM";
BA_ "SignalLongName" SG_ 1132 Aux3AmbtColrCtlCstAvlFlg102 "Auxiliary 3 Ambient Color Control Customization Availability Flag 102";
BA_ "SignalType" SG_ 1132 Aux3AmbtColrCtlCstAvlFlg101 "ENM";
BA_ "SignalLongName" SG_ 1132 Aux3AmbtColrCtlCstAvlFlg101 "Auxiliary 3 Ambient Color Control Customization Availability Flag 101";
BA_ "SignalType" SG_ 1132 Aux3AmbtColrCtlCstAvlFlg100 "ENM";
BA_ "SignalLongName" SG_ 1132 Aux3AmbtColrCtlCstAvlFlg100 "Auxiliary 3 Ambient Color Control Customization Availability Flag 100";
BA_ "SignalType" SG_ 1132 Aux3AmbtColrCtlCstAvlFlg10 "ENM";
BA_ "SignalLongName" SG_ 1132 Aux3AmbtColrCtlCstAvlFlg10 "Auxiliary 3 Ambient Color Control Customization Availability Flag 10";
BA_ "SignalType" SG_ 1132 Aux3AmbtColrCtlCstAvlFlg113 "ENM";
BA_ "SignalLongName" SG_ 1132 Aux3AmbtColrCtlCstAvlFlg113 "Auxiliary 3 Ambient Color Control Customization Availability Flag 113";
BA_ "SignalType" SG_ 1132 Aux3AmbtColrCtlCstAvlFlg112 "ENM";
BA_ "SignalLongName" SG_ 1132 Aux3AmbtColrCtlCstAvlFlg112 "Auxiliary 3 Ambient Color Control Customization Availability Flag 112";
BA_ "SignalType" SG_ 1132 Aux3AmbtColrCtlCstAvlFlg111 "ENM";
BA_ "SignalLongName" SG_ 1132 Aux3AmbtColrCtlCstAvlFlg111 "Auxiliary 3 Ambient Color Control Customization Availability Flag 111";
BA_ "SignalType" SG_ 1132 Aux3AmbtColrCtlCstAvlFlg110 "ENM";
BA_ "SignalLongName" SG_ 1132 Aux3AmbtColrCtlCstAvlFlg110 "Auxiliary 3 Ambient Color Control Customization Availability Flag 110";
BA_ "SignalType" SG_ 1132 Aux3AmbtColrCtlCstAvlFlg11 "ENM";
BA_ "SignalLongName" SG_ 1132 Aux3AmbtColrCtlCstAvlFlg11 "Auxiliary 3 Ambient Color Control Customization Availability Flag 11";
BA_ "SignalType" SG_ 1132 Aux3AmbtColrCtlCstAvlFlg109 "ENM";
BA_ "SignalLongName" SG_ 1132 Aux3AmbtColrCtlCstAvlFlg109 "Auxiliary 3 Ambient Color Control Customization Availability Flag 109";
BA_ "SignalType" SG_ 1132 Aux3AmbtColrCtlCstAvlFlg108 "ENM";
BA_ "SignalLongName" SG_ 1132 Aux3AmbtColrCtlCstAvlFlg108 "Auxiliary 3 Ambient Color Control Customization Availability Flag 108";
BA_ "SignalType" SG_ 1132 Aux3AmbtColrCtlCstAvlFlg107 "ENM";
BA_ "SignalLongName" SG_ 1132 Aux3AmbtColrCtlCstAvlFlg107 "Auxiliary 3 Ambient Color Control Customization Availability Flag 107";
BA_ "SignalType" SG_ 1132 Aux3AmbtColrCtlCstAvlFlg120 "ENM";
BA_ "SignalLongName" SG_ 1132 Aux3AmbtColrCtlCstAvlFlg120 "Auxiliary 3 Ambient Color Control Customization Availability Flag 120";
BA_ "SignalType" SG_ 1132 Aux3AmbtColrCtlCstAvlFlg12 "ENM";
BA_ "SignalLongName" SG_ 1132 Aux3AmbtColrCtlCstAvlFlg12 "Auxiliary 3 Ambient Color Control Customization Availability Flag 12";
BA_ "SignalType" SG_ 1132 Aux3AmbtColrCtlCstAvlFlg119 "ENM";
BA_ "SignalLongName" SG_ 1132 Aux3AmbtColrCtlCstAvlFlg119 "Auxiliary 3 Ambient Color Control Customization Availability Flag 119";
BA_ "SignalType" SG_ 1132 Aux3AmbtColrCtlCstAvlFlg118 "ENM";
BA_ "SignalLongName" SG_ 1132 Aux3AmbtColrCtlCstAvlFlg118 "Auxiliary 3 Ambient Color Control Customization Availability Flag 118";
BA_ "SignalType" SG_ 1132 Aux3AmbtColrCtlCstAvlFlg117 "ENM";
BA_ "SignalLongName" SG_ 1132 Aux3AmbtColrCtlCstAvlFlg117 "Auxiliary 3 Ambient Color Control Customization Availability Flag 117";
BA_ "SignalType" SG_ 1132 Aux3AmbtColrCtlCstAvlFlg116 "ENM";
BA_ "SignalLongName" SG_ 1132 Aux3AmbtColrCtlCstAvlFlg116 "Auxiliary 3 Ambient Color Control Customization Availability Flag 116";
BA_ "SignalType" SG_ 1132 Aux3AmbtColrCtlCstAvlFlg115 "ENM";
BA_ "SignalLongName" SG_ 1132 Aux3AmbtColrCtlCstAvlFlg115 "Auxiliary 3 Ambient Color Control Customization Availability Flag 115";
BA_ "SignalType" SG_ 1132 Aux3AmbtColrCtlCstAvlFlg114 "ENM";
BA_ "SignalLongName" SG_ 1132 Aux3AmbtColrCtlCstAvlFlg114 "Auxiliary 3 Ambient Color Control Customization Availability Flag 114";
BA_ "SignalType" SG_ 1132 Aux3AmbtColrCtlCstAvlFlg13 "ENM";
BA_ "SignalLongName" SG_ 1132 Aux3AmbtColrCtlCstAvlFlg13 "Auxiliary 3 Ambient Color Control Customization Availability Flag 13";
BA_ "SignalType" SG_ 1132 Aux3AmbtColrCtlCstAvlFlg127 "ENM";
BA_ "SignalLongName" SG_ 1132 Aux3AmbtColrCtlCstAvlFlg127 "Auxiliary 3 Ambient Color Control Customization Availability Flag 127";
BA_ "SignalType" SG_ 1132 Aux3AmbtColrCtlCstAvlFlg126 "ENM";
BA_ "SignalLongName" SG_ 1132 Aux3AmbtColrCtlCstAvlFlg126 "Auxiliary 3 Ambient Color Control Customization Availability Flag 126";
BA_ "SignalType" SG_ 1132 Aux3AmbtColrCtlCstAvlFlg125 "ENM";
BA_ "SignalLongName" SG_ 1132 Aux3AmbtColrCtlCstAvlFlg125 "Auxiliary 3 Ambient Color Control Customization Availability Flag 125";
BA_ "SignalType" SG_ 1132 Aux3AmbtColrCtlCstAvlFlg124 "ENM";
BA_ "SignalLongName" SG_ 1132 Aux3AmbtColrCtlCstAvlFlg124 "Auxiliary 3 Ambient Color Control Customization Availability Flag 124";
BA_ "SignalType" SG_ 1132 Aux3AmbtColrCtlCstAvlFlg123 "ENM";
BA_ "SignalLongName" SG_ 1132 Aux3AmbtColrCtlCstAvlFlg123 "Auxiliary 3 Ambient Color Control Customization Availability Flag 123";
BA_ "SignalType" SG_ 1132 Aux3AmbtColrCtlCstAvlFlg122 "ENM";
BA_ "SignalLongName" SG_ 1132 Aux3AmbtColrCtlCstAvlFlg122 "Auxiliary 3 Ambient Color Control Customization Availability Flag 122";
BA_ "SignalType" SG_ 1132 Aux3AmbtColrCtlCstAvlFlg121 "ENM";
BA_ "SignalLongName" SG_ 1132 Aux3AmbtColrCtlCstAvlFlg121 "Auxiliary 3 Ambient Color Control Customization Availability Flag 121";
BA_ "SignalType" SG_ 1132 Aux3AmbtColrCtlCstAvlFlg20 "ENM";
BA_ "SignalLongName" SG_ 1132 Aux3AmbtColrCtlCstAvlFlg20 "Auxiliary 3 Ambient Color Control Customization Availability Flag 20";
BA_ "SignalType" SG_ 1132 Aux3AmbtColrCtlCstAvlFlg2 "ENM";
BA_ "SignalLongName" SG_ 1132 Aux3AmbtColrCtlCstAvlFlg2 "Auxiliary 3 Ambient Color Control Customization Availability Flag 2";
BA_ "SignalType" SG_ 1132 Aux3AmbtColrCtlCstAvlFlg19 "ENM";
BA_ "SignalLongName" SG_ 1132 Aux3AmbtColrCtlCstAvlFlg19 "Auxiliary 3 Ambient Color Control Customization Availability Flag 19";
BA_ "SignalType" SG_ 1132 Aux3AmbtColrCtlCstAvlFlg18 "ENM";
BA_ "SignalLongName" SG_ 1132 Aux3AmbtColrCtlCstAvlFlg18 "Auxiliary 3 Ambient Color Control Customization Availability Flag 18";
BA_ "SignalType" SG_ 1132 Aux3AmbtColrCtlCstAvlFlg17 "ENM";
BA_ "SignalLongName" SG_ 1132 Aux3AmbtColrCtlCstAvlFlg17 "Auxiliary 3 Ambient Color Control Customization Availability Flag 17";
BA_ "SignalType" SG_ 1132 Aux3AmbtColrCtlCstAvlFlg16 "ENM";
BA_ "SignalLongName" SG_ 1132 Aux3AmbtColrCtlCstAvlFlg16 "Auxiliary 3 Ambient Color Control Customization Availability Flag 16";
BA_ "SignalType" SG_ 1132 Aux3AmbtColrCtlCstAvlFlg15 "ENM";
BA_ "SignalLongName" SG_ 1132 Aux3AmbtColrCtlCstAvlFlg15 "Auxiliary 3 Ambient Color Control Customization Availability Flag 15";
BA_ "SignalType" SG_ 1132 Aux3AmbtColrCtlCstAvlFlg14 "ENM";
BA_ "SignalLongName" SG_ 1132 Aux3AmbtColrCtlCstAvlFlg14 "Auxiliary 3 Ambient Color Control Customization Availability Flag 14";
BA_ "SignalType" SG_ 1935 Aux3AmbtColrCtlCstAvlFlg28 "ENM";
BA_ "SignalLongName" SG_ 1935 Aux3AmbtColrCtlCstAvlFlg28 "Auxiliary 3 Ambient Color Control Customization Availability Flag 28";
BA_ "SignalType" SG_ 1935 Aux3AmbtColrCtlCstAvlFlg27 "ENM";
BA_ "SignalLongName" SG_ 1935 Aux3AmbtColrCtlCstAvlFlg27 "Auxiliary 3 Ambient Color Control Customization Availability Flag 27";
BA_ "SignalType" SG_ 1935 Aux3AmbtColrCtlCstAvlFlg26 "ENM";
BA_ "SignalLongName" SG_ 1935 Aux3AmbtColrCtlCstAvlFlg26 "Auxiliary 3 Ambient Color Control Customization Availability Flag 26";
BA_ "SignalType" SG_ 1935 Aux3AmbtColrCtlCstAvlFlg25 "ENM";
BA_ "SignalLongName" SG_ 1935 Aux3AmbtColrCtlCstAvlFlg25 "Auxiliary 3 Ambient Color Control Customization Availability Flag 25";
BA_ "SignalType" SG_ 1935 Aux3AmbtColrCtlCstAvlFlg24 "ENM";
BA_ "SignalLongName" SG_ 1935 Aux3AmbtColrCtlCstAvlFlg24 "Auxiliary 3 Ambient Color Control Customization Availability Flag 24";
BA_ "SignalType" SG_ 1935 Aux3AmbtColrCtlCstAvlFlg23 "ENM";
BA_ "SignalLongName" SG_ 1935 Aux3AmbtColrCtlCstAvlFlg23 "Auxiliary 3 Ambient Color Control Customization Availability Flag 23";
BA_ "SignalType" SG_ 1935 Aux3AmbtColrCtlCstAvlFlg22 "ENM";
BA_ "SignalLongName" SG_ 1935 Aux3AmbtColrCtlCstAvlFlg22 "Auxiliary 3 Ambient Color Control Customization Availability Flag 22";
BA_ "SignalType" SG_ 1935 Aux3AmbtColrCtlCstAvlFlg21 "ENM";
BA_ "SignalLongName" SG_ 1935 Aux3AmbtColrCtlCstAvlFlg21 "Auxiliary 3 Ambient Color Control Customization Availability Flag 21";
BA_ "SignalType" SG_ 1935 Aux3AmbtColrCtlCstAvlFlg35 "ENM";
BA_ "SignalLongName" SG_ 1935 Aux3AmbtColrCtlCstAvlFlg35 "Auxiliary 3 Ambient Color Control Customization Availability Flag 35";
BA_ "SignalType" SG_ 1935 Aux3AmbtColrCtlCstAvlFlg34 "ENM";
BA_ "SignalLongName" SG_ 1935 Aux3AmbtColrCtlCstAvlFlg34 "Auxiliary 3 Ambient Color Control Customization Availability Flag 34";
BA_ "SignalType" SG_ 1935 Aux3AmbtColrCtlCstAvlFlg33 "ENM";
BA_ "SignalLongName" SG_ 1935 Aux3AmbtColrCtlCstAvlFlg33 "Auxiliary 3 Ambient Color Control Customization Availability Flag 33";
BA_ "SignalType" SG_ 1935 Aux3AmbtColrCtlCstAvlFlg32 "ENM";
BA_ "SignalLongName" SG_ 1935 Aux3AmbtColrCtlCstAvlFlg32 "Auxiliary 3 Ambient Color Control Customization Availability Flag 32";
BA_ "SignalType" SG_ 1935 Aux3AmbtColrCtlCstAvlFlg31 "ENM";
BA_ "SignalLongName" SG_ 1935 Aux3AmbtColrCtlCstAvlFlg31 "Auxiliary 3 Ambient Color Control Customization Availability Flag 31";
BA_ "SignalType" SG_ 1935 Aux3AmbtColrCtlCstAvlFlg30 "ENM";
BA_ "SignalLongName" SG_ 1935 Aux3AmbtColrCtlCstAvlFlg30 "Auxiliary 3 Ambient Color Control Customization Availability Flag 30";
BA_ "SignalType" SG_ 1935 Aux3AmbtColrCtlCstAvlFlg3 "ENM";
BA_ "SignalLongName" SG_ 1935 Aux3AmbtColrCtlCstAvlFlg3 "Auxiliary 3 Ambient Color Control Customization Availability Flag 3";
BA_ "SignalType" SG_ 1935 Aux3AmbtColrCtlCstAvlFlg29 "ENM";
BA_ "SignalLongName" SG_ 1935 Aux3AmbtColrCtlCstAvlFlg29 "Auxiliary 3 Ambient Color Control Customization Availability Flag 29";
BA_ "SignalType" SG_ 1935 Aux3AmbtColrCtlCstAvlFlg42 "ENM";
BA_ "SignalLongName" SG_ 1935 Aux3AmbtColrCtlCstAvlFlg42 "Auxiliary 3 Ambient Color Control Customization Availability Flag 42";
BA_ "SignalType" SG_ 1935 Aux3AmbtColrCtlCstAvlFlg41 "ENM";
BA_ "SignalLongName" SG_ 1935 Aux3AmbtColrCtlCstAvlFlg41 "Auxiliary 3 Ambient Color Control Customization Availability Flag 41";
BA_ "SignalType" SG_ 1935 Aux3AmbtColrCtlCstAvlFlg40 "ENM";
BA_ "SignalLongName" SG_ 1935 Aux3AmbtColrCtlCstAvlFlg40 "Auxiliary 3 Ambient Color Control Customization Availability Flag 40";
BA_ "SignalType" SG_ 1935 Aux3AmbtColrCtlCstAvlFlg4 "ENM";
BA_ "SignalLongName" SG_ 1935 Aux3AmbtColrCtlCstAvlFlg4 "Auxiliary 3 Ambient Color Control Customization Availability Flag 4";
BA_ "SignalType" SG_ 1935 Aux3AmbtColrCtlCstAvlFlg39 "ENM";
BA_ "SignalLongName" SG_ 1935 Aux3AmbtColrCtlCstAvlFlg39 "Auxiliary 3 Ambient Color Control Customization Availability Flag 39";
BA_ "SignalType" SG_ 1935 Aux3AmbtColrCtlCstAvlFlg38 "ENM";
BA_ "SignalLongName" SG_ 1935 Aux3AmbtColrCtlCstAvlFlg38 "Auxiliary 3 Ambient Color Control Customization Availability Flag 38";
BA_ "SignalType" SG_ 1935 Aux3AmbtColrCtlCstAvlFlg37 "ENM";
BA_ "SignalLongName" SG_ 1935 Aux3AmbtColrCtlCstAvlFlg37 "Auxiliary 3 Ambient Color Control Customization Availability Flag 37";
BA_ "SignalType" SG_ 1935 Aux3AmbtColrCtlCstAvlFlg36 "ENM";
BA_ "SignalLongName" SG_ 1935 Aux3AmbtColrCtlCstAvlFlg36 "Auxiliary 3 Ambient Color Control Customization Availability Flag 36";
BA_ "SignalType" SG_ 1935 Aux3AmbtColrCtlCstAvlFlg5 "ENM";
BA_ "SignalLongName" SG_ 1935 Aux3AmbtColrCtlCstAvlFlg5 "Auxiliary 3 Ambient Color Control Customization Availability Flag 5";
BA_ "SignalType" SG_ 1935 Aux3AmbtColrCtlCstAvlFlg49 "ENM";
BA_ "SignalLongName" SG_ 1935 Aux3AmbtColrCtlCstAvlFlg49 "Auxiliary 3 Ambient Color Control Customization Availability Flag 49";
BA_ "SignalType" SG_ 1935 Aux3AmbtColrCtlCstAvlFlg48 "ENM";
BA_ "SignalLongName" SG_ 1935 Aux3AmbtColrCtlCstAvlFlg48 "Auxiliary 3 Ambient Color Control Customization Availability Flag 48";
BA_ "SignalType" SG_ 1935 Aux3AmbtColrCtlCstAvlFlg47 "ENM";
BA_ "SignalLongName" SG_ 1935 Aux3AmbtColrCtlCstAvlFlg47 "Auxiliary 3 Ambient Color Control Customization Availability Flag 47";
BA_ "SignalType" SG_ 1935 Aux3AmbtColrCtlCstAvlFlg46 "ENM";
BA_ "SignalLongName" SG_ 1935 Aux3AmbtColrCtlCstAvlFlg46 "Auxiliary 3 Ambient Color Control Customization Availability Flag 46";
BA_ "SignalType" SG_ 1935 Aux3AmbtColrCtlCstAvlFlg45 "ENM";
BA_ "SignalLongName" SG_ 1935 Aux3AmbtColrCtlCstAvlFlg45 "Auxiliary 3 Ambient Color Control Customization Availability Flag 45";
BA_ "SignalType" SG_ 1935 Aux3AmbtColrCtlCstAvlFlg44 "ENM";
BA_ "SignalLongName" SG_ 1935 Aux3AmbtColrCtlCstAvlFlg44 "Auxiliary 3 Ambient Color Control Customization Availability Flag 44";
BA_ "SignalType" SG_ 1935 Aux3AmbtColrCtlCstAvlFlg43 "ENM";
BA_ "SignalLongName" SG_ 1935 Aux3AmbtColrCtlCstAvlFlg43 "Auxiliary 3 Ambient Color Control Customization Availability Flag 43";
BA_ "SignalType" SG_ 1935 Aux3AmbtColrCtlCstAvlFlg57 "ENM";
BA_ "SignalLongName" SG_ 1935 Aux3AmbtColrCtlCstAvlFlg57 "Auxiliary 3 Ambient Color Control Customization Availability Flag 57";
BA_ "SignalType" SG_ 1935 Aux3AmbtColrCtlCstAvlFlg56 "ENM";
BA_ "SignalLongName" SG_ 1935 Aux3AmbtColrCtlCstAvlFlg56 "Auxiliary 3 Ambient Color Control Customization Availability Flag 56";
BA_ "SignalType" SG_ 1935 Aux3AmbtColrCtlCstAvlFlg55 "ENM";
BA_ "SignalLongName" SG_ 1935 Aux3AmbtColrCtlCstAvlFlg55 "Auxiliary 3 Ambient Color Control Customization Availability Flag 55";
BA_ "SignalType" SG_ 1935 Aux3AmbtColrCtlCstAvlFlg54 "ENM";
BA_ "SignalLongName" SG_ 1935 Aux3AmbtColrCtlCstAvlFlg54 "Auxiliary 3 Ambient Color Control Customization Availability Flag 54";
BA_ "SignalType" SG_ 1935 Aux3AmbtColrCtlCstAvlFlg53 "ENM";
BA_ "SignalLongName" SG_ 1935 Aux3AmbtColrCtlCstAvlFlg53 "Auxiliary 3 Ambient Color Control Customization Availability Flag 53";
BA_ "SignalType" SG_ 1935 Aux3AmbtColrCtlCstAvlFlg52 "ENM";
BA_ "SignalLongName" SG_ 1935 Aux3AmbtColrCtlCstAvlFlg52 "Auxiliary 3 Ambient Color Control Customization Availability Flag 52";
BA_ "SignalType" SG_ 1935 Aux3AmbtColrCtlCstAvlFlg51 "ENM";
BA_ "SignalLongName" SG_ 1935 Aux3AmbtColrCtlCstAvlFlg51 "Auxiliary 3 Ambient Color Control Customization Availability Flag 51";
BA_ "SignalType" SG_ 1935 Aux3AmbtColrCtlCstAvlFlg50 "ENM";
BA_ "SignalLongName" SG_ 1935 Aux3AmbtColrCtlCstAvlFlg50 "Auxiliary 3 Ambient Color Control Customization Availability Flag 50";
BA_ "SignalType" SG_ 1935 Aux3AmbtColrCtlCstAvlFlg64 "ENM";
BA_ "SignalLongName" SG_ 1935 Aux3AmbtColrCtlCstAvlFlg64 "Auxiliary 3 Ambient Color Control Customization Availability Flag 64";
BA_ "SignalType" SG_ 1935 Aux3AmbtColrCtlCstAvlFlg63 "ENM";
BA_ "SignalLongName" SG_ 1935 Aux3AmbtColrCtlCstAvlFlg63 "Auxiliary 3 Ambient Color Control Customization Availability Flag 63";
BA_ "SignalType" SG_ 1935 Aux3AmbtColrCtlCstAvlFlg62 "ENM";
BA_ "SignalLongName" SG_ 1935 Aux3AmbtColrCtlCstAvlFlg62 "Auxiliary 3 Ambient Color Control Customization Availability Flag 62";
BA_ "SignalType" SG_ 1935 Aux3AmbtColrCtlCstAvlFlg61 "ENM";
BA_ "SignalLongName" SG_ 1935 Aux3AmbtColrCtlCstAvlFlg61 "Auxiliary 3 Ambient Color Control Customization Availability Flag 61";
BA_ "SignalType" SG_ 1935 Aux3AmbtColrCtlCstAvlFlg60 "ENM";
BA_ "SignalLongName" SG_ 1935 Aux3AmbtColrCtlCstAvlFlg60 "Auxiliary 3 Ambient Color Control Customization Availability Flag 60";
BA_ "SignalType" SG_ 1935 Aux3AmbtColrCtlCstAvlFlg6 "ENM";
BA_ "SignalLongName" SG_ 1935 Aux3AmbtColrCtlCstAvlFlg6 "Auxiliary 3 Ambient Color Control Customization Availability Flag 6";
BA_ "SignalType" SG_ 1935 Aux3AmbtColrCtlCstAvlFlg59 "ENM";
BA_ "SignalLongName" SG_ 1935 Aux3AmbtColrCtlCstAvlFlg59 "Auxiliary 3 Ambient Color Control Customization Availability Flag 59";
BA_ "SignalType" SG_ 1935 Aux3AmbtColrCtlCstAvlFlg58 "ENM";
BA_ "SignalLongName" SG_ 1935 Aux3AmbtColrCtlCstAvlFlg58 "Auxiliary 3 Ambient Color Control Customization Availability Flag 58";
BA_ "SignalType" SG_ 1935 Aux3AmbtColrCtlCstAvlFlg71 "ENM";
BA_ "SignalLongName" SG_ 1935 Aux3AmbtColrCtlCstAvlFlg71 "Auxiliary 3 Ambient Color Control Customization Availability Flag 71";
BA_ "SignalType" SG_ 1935 Aux3AmbtColrCtlCstAvlFlg70 "ENM";
BA_ "SignalLongName" SG_ 1935 Aux3AmbtColrCtlCstAvlFlg70 "Auxiliary 3 Ambient Color Control Customization Availability Flag 70";
BA_ "SignalType" SG_ 1935 Aux3AmbtColrCtlCstAvlFlg7 "ENM";
BA_ "SignalLongName" SG_ 1935 Aux3AmbtColrCtlCstAvlFlg7 "Auxiliary 3 Ambient Color Control Customization Availability Flag 7";
BA_ "SignalType" SG_ 1935 Aux3AmbtColrCtlCstAvlFlg69 "ENM";
BA_ "SignalLongName" SG_ 1935 Aux3AmbtColrCtlCstAvlFlg69 "Auxiliary 3 Ambient Color Control Customization Availability Flag 69";
BA_ "SignalType" SG_ 1935 Aux3AmbtColrCtlCstAvlFlg68 "ENM";
BA_ "SignalLongName" SG_ 1935 Aux3AmbtColrCtlCstAvlFlg68 "Auxiliary 3 Ambient Color Control Customization Availability Flag 68";
BA_ "SignalType" SG_ 1935 Aux3AmbtColrCtlCstAvlFlg67 "ENM";
BA_ "SignalLongName" SG_ 1935 Aux3AmbtColrCtlCstAvlFlg67 "Auxiliary 3 Ambient Color Control Customization Availability Flag 67";
BA_ "SignalType" SG_ 1935 Aux3AmbtColrCtlCstAvlFlg66 "ENM";
BA_ "SignalLongName" SG_ 1935 Aux3AmbtColrCtlCstAvlFlg66 "Auxiliary 3 Ambient Color Control Customization Availability Flag 66";
BA_ "SignalType" SG_ 1935 Aux3AmbtColrCtlCstAvlFlg65 "ENM";
BA_ "SignalLongName" SG_ 1935 Aux3AmbtColrCtlCstAvlFlg65 "Auxiliary 3 Ambient Color Control Customization Availability Flag 65";
BA_ "SignalType" SG_ 1935 Aux3AmbtColrCtlCstAvlFlg79 "ENM";
BA_ "SignalLongName" SG_ 1935 Aux3AmbtColrCtlCstAvlFlg79 "Auxiliary 3 Ambient Color Control Customization Availability Flag 79";
BA_ "SignalType" SG_ 1935 Aux3AmbtColrCtlCstAvlFlg78 "ENM";
BA_ "SignalLongName" SG_ 1935 Aux3AmbtColrCtlCstAvlFlg78 "Auxiliary 3 Ambient Color Control Customization Availability Flag 78";
BA_ "SignalType" SG_ 1935 Aux3AmbtColrCtlCstAvlFlg77 "ENM";
BA_ "SignalLongName" SG_ 1935 Aux3AmbtColrCtlCstAvlFlg77 "Auxiliary 3 Ambient Color Control Customization Availability Flag 77";
BA_ "SignalType" SG_ 1935 Aux3AmbtColrCtlCstAvlFlg76 "ENM";
BA_ "SignalLongName" SG_ 1935 Aux3AmbtColrCtlCstAvlFlg76 "Auxiliary 3 Ambient Color Control Customization Availability Flag 76";
BA_ "SignalType" SG_ 1935 Aux3AmbtColrCtlCstAvlFlg75 "ENM";
BA_ "SignalLongName" SG_ 1935 Aux3AmbtColrCtlCstAvlFlg75 "Auxiliary 3 Ambient Color Control Customization Availability Flag 75";
BA_ "SignalType" SG_ 1935 Aux3AmbtColrCtlCstAvlFlg74 "ENM";
BA_ "SignalLongName" SG_ 1935 Aux3AmbtColrCtlCstAvlFlg74 "Auxiliary 3 Ambient Color Control Customization Availability Flag 74";
BA_ "SignalType" SG_ 1935 Aux3AmbtColrCtlCstAvlFlg73 "ENM";
BA_ "SignalLongName" SG_ 1935 Aux3AmbtColrCtlCstAvlFlg73 "Auxiliary 3 Ambient Color Control Customization Availability Flag 73";
BA_ "SignalType" SG_ 1935 Aux3AmbtColrCtlCstAvlFlg72 "ENM";
BA_ "SignalLongName" SG_ 1935 Aux3AmbtColrCtlCstAvlFlg72 "Auxiliary 3 Ambient Color Control Customization Availability Flag 72";
BA_ "SignalType" SG_ 1952 DMCabLgtPrkCstCurrSetVal "ENM";
BA_ "SignalLongName" SG_ 1952 DMCabLgtPrkCstCurrSetVal "Delivery Mode Cab Lighting on Park Customization Current Setting Value";
BA_ "SignalType" SG_ 1952 DMBlkhdDrUnltchPrkCstCurrSetVal "ENM";
BA_ "SignalLongName" SG_ 1952 DMBlkhdDrUnltchPrkCstCurrSetVal "Delivery Mode Bulkhead Door Unlatch on Park Customization Current Setting Value";
BA_ "SignalType" SG_ 1952 DMBlkhdDrUnlckPrkCstCurrSetVal "ENM";
BA_ "SignalLongName" SG_ 1952 DMBlkhdDrUnlckPrkCstCurrSetVal "Delivery Mode Bulkhead Door Unlock on Park Customization Current Setting Value";
BA_ "SignalType" SG_ 1952 DMHrnOutPrkCstCurrSetVal "ENM";
BA_ "SignalLongName" SG_ 1952 DMHrnOutPrkCstCurrSetVal "Delivery Mode Horn Out Of Park Customization Current Setting Value";
BA_ "SignalType" SG_ 1952 DMDrvrDrUnlckPrkCstCurrSetVal "ENM";
BA_ "SignalLongName" SG_ 1952 DMDrvrDrUnlckPrkCstCurrSetVal "Delivery Mode Driver Door Unlock on Park Customization Current Setting Value";
BA_ "SignalType" SG_ 1952 DMCrbsdDrUnlckPrkCstCurrSetVal "ENM";
BA_ "SignalLongName" SG_ 1952 DMCrbsdDrUnlckPrkCstCurrSetVal "Delivery Mode Curbside Door Unlock on Park Customization Current Setting Value";
BA_ "SignalType" SG_ 1952 DMBlkhdDrUnlckPrkCstAvlFlg6 "ENM";
BA_ "SignalLongName" SG_ 1952 DMBlkhdDrUnlckPrkCstAvlFlg6 "Delivery Mode Bulkhead Door Unlock on Park Customization Availability Flag 6";
BA_ "SignalType" SG_ 1952 DMBlkhdDrUnlckPrkCstAvlFlg5 "ENM";
BA_ "SignalLongName" SG_ 1952 DMBlkhdDrUnlckPrkCstAvlFlg5 "Delivery Mode Bulkhead Door Unlock on Park Customization Availability Flag 5";
BA_ "SignalType" SG_ 1952 DMBlkhdDrUnlckPrkCstAvlFlg4 "ENM";
BA_ "SignalLongName" SG_ 1952 DMBlkhdDrUnlckPrkCstAvlFlg4 "Delivery Mode Bulkhead Door Unlock on Park Customization Availability Flag 4";
BA_ "SignalType" SG_ 1952 DMBlkhdDrUnlckPrkCstAvlFlg3 "ENM";
BA_ "SignalLongName" SG_ 1952 DMBlkhdDrUnlckPrkCstAvlFlg3 "Delivery Mode Bulkhead Door Unlock on Park Customization Availability Flag 3";
BA_ "SignalType" SG_ 1952 DMBlkhdDrUnlckPrkCstAvlFlg2 "ENM";
BA_ "SignalLongName" SG_ 1952 DMBlkhdDrUnlckPrkCstAvlFlg2 "Delivery Mode Bulkhead Door Unlock on Park Customization Availability Flag 2";
BA_ "SignalType" SG_ 1952 DMBlkhdDrUnlckPrkCstAvlFlg1 "ENM";
BA_ "SignalLongName" SG_ 1952 DMBlkhdDrUnlckPrkCstAvlFlg1 "Delivery Mode Bulkhead Door Unlock on Park Customization Availability Flag 1";
BA_ "SignalType" SG_ 1952 DMBlkhdDrUnltchPrkCstAvlFlg6 "ENM";
BA_ "SignalLongName" SG_ 1952 DMBlkhdDrUnltchPrkCstAvlFlg6 "Delivery Mode Bulkhead Door Unlatch on Park Customization Availability Flag 6";
BA_ "SignalType" SG_ 1952 DMBlkhdDrUnltchPrkCstAvlFlg5 "ENM";
BA_ "SignalLongName" SG_ 1952 DMBlkhdDrUnltchPrkCstAvlFlg5 "Delivery Mode Bulkhead Door Unlatch on Park Customization Availability Flag 5";
BA_ "SignalType" SG_ 1952 DMBlkhdDrUnltchPrkCstAvlFlg4 "ENM";
BA_ "SignalLongName" SG_ 1952 DMBlkhdDrUnltchPrkCstAvlFlg4 "Delivery Mode Bulkhead Door Unlatch on Park Customization Availability Flag 4";
BA_ "SignalType" SG_ 1952 DMBlkhdDrUnltchPrkCstAvlFlg3 "ENM";
BA_ "SignalLongName" SG_ 1952 DMBlkhdDrUnltchPrkCstAvlFlg3 "Delivery Mode Bulkhead Door Unlatch on Park Customization Availability Flag 3";
BA_ "SignalType" SG_ 1952 DMBlkhdDrUnltchPrkCstAvlFlg2 "ENM";
BA_ "SignalLongName" SG_ 1952 DMBlkhdDrUnltchPrkCstAvlFlg2 "Delivery Mode Bulkhead Door Unlatch on Park Customization Availability Flag 2";
BA_ "SignalType" SG_ 1952 DMBlkhdDrUnltchPrkCstAvlFlg1 "ENM";
BA_ "SignalLongName" SG_ 1952 DMBlkhdDrUnltchPrkCstAvlFlg1 "Delivery Mode Bulkhead Door Unlatch on Park Customization Availability Flag 1";
BA_ "SignalType" SG_ 1952 DMBlkhdDrUnlckPrkCstSetAval "ENM";
BA_ "SignalLongName" SG_ 1952 DMBlkhdDrUnlckPrkCstSetAval "Delivery Mode Bulkhead Door Unlock on Park Customization Setting Available";
BA_ "SignalType" SG_ 1952 DMBlkhdDrUnlckPrkCstAvlFlg7 "ENM";
BA_ "SignalLongName" SG_ 1952 DMBlkhdDrUnlckPrkCstAvlFlg7 "Delivery Mode Bulkhead Door Unlock on Park Customization Availability Flag 7";
BA_ "SignalType" SG_ 1952 DMCabLgtPrkCstAvlFlg6 "ENM";
BA_ "SignalLongName" SG_ 1952 DMCabLgtPrkCstAvlFlg6 "Delivery Mode Cab Lighting on Park Customization Availability Flag 6";
BA_ "SignalType" SG_ 1952 DMCabLgtPrkCstAvlFlg5 "ENM";
BA_ "SignalLongName" SG_ 1952 DMCabLgtPrkCstAvlFlg5 "Delivery Mode Cab Lighting on Park Customization Availability Flag 5";
BA_ "SignalType" SG_ 1952 DMCabLgtPrkCstAvlFlg4 "ENM";
BA_ "SignalLongName" SG_ 1952 DMCabLgtPrkCstAvlFlg4 "Delivery Mode Cab Lighting on Park Customization Availability Flag 4";
BA_ "SignalType" SG_ 1952 DMCabLgtPrkCstAvlFlg3 "ENM";
BA_ "SignalLongName" SG_ 1952 DMCabLgtPrkCstAvlFlg3 "Delivery Mode Cab Lighting on Park Customization Availability Flag 3";
BA_ "SignalType" SG_ 1952 DMCabLgtPrkCstAvlFlg2 "ENM";
BA_ "SignalLongName" SG_ 1952 DMCabLgtPrkCstAvlFlg2 "Delivery Mode Cab Lighting on Park Customization Availability Flag 2";
BA_ "SignalType" SG_ 1952 DMCabLgtPrkCstAvlFlg1 "ENM";
BA_ "SignalLongName" SG_ 1952 DMCabLgtPrkCstAvlFlg1 "Delivery Mode Cab Lighting on Park Customization Availability Flag 1";
BA_ "SignalType" SG_ 1952 DMBlkhdDrUnltchPrkCstSetAval "ENM";
BA_ "SignalLongName" SG_ 1952 DMBlkhdDrUnltchPrkCstSetAval "Delivery Mode Bulkhead Door Unlatch on Park Customization Setting Available";
BA_ "SignalType" SG_ 1952 DMBlkhdDrUnltchPrkCstAvlFlg7 "ENM";
BA_ "SignalLongName" SG_ 1952 DMBlkhdDrUnltchPrkCstAvlFlg7 "Delivery Mode Bulkhead Door Unlatch on Park Customization Availability Flag 7";
BA_ "SignalType" SG_ 1952 DMCrbsdDrUnlckPrkCstAvlFlg6 "ENM";
BA_ "SignalLongName" SG_ 1952 DMCrbsdDrUnlckPrkCstAvlFlg6 "Delivery Mode Curbside Door Unlock on Park Customization Availability Flag 6";
BA_ "SignalType" SG_ 1952 DMCrbsdDrUnlckPrkCstAvlFlg5 "ENM";
BA_ "SignalLongName" SG_ 1952 DMCrbsdDrUnlckPrkCstAvlFlg5 "Delivery Mode Curbside Door Unlock on Park Customization Availability Flag 5";
BA_ "SignalType" SG_ 1952 DMCrbsdDrUnlckPrkCstAvlFlg4 "ENM";
BA_ "SignalLongName" SG_ 1952 DMCrbsdDrUnlckPrkCstAvlFlg4 "Delivery Mode Curbside Door Unlock on Park Customization Availability Flag 4";
BA_ "SignalType" SG_ 1952 DMCrbsdDrUnlckPrkCstAvlFlg3 "ENM";
BA_ "SignalLongName" SG_ 1952 DMCrbsdDrUnlckPrkCstAvlFlg3 "Delivery Mode Curbside Door Unlock on Park Customization Availability Flag 3";
BA_ "SignalType" SG_ 1952 DMCrbsdDrUnlckPrkCstAvlFlg2 "ENM";
BA_ "SignalLongName" SG_ 1952 DMCrbsdDrUnlckPrkCstAvlFlg2 "Delivery Mode Curbside Door Unlock on Park Customization Availability Flag 2";
BA_ "SignalType" SG_ 1952 DMCrbsdDrUnlckPrkCstAvlFlg1 "ENM";
BA_ "SignalLongName" SG_ 1952 DMCrbsdDrUnlckPrkCstAvlFlg1 "Delivery Mode Curbside Door Unlock on Park Customization Availability Flag 1";
BA_ "SignalType" SG_ 1952 DMCabLgtPrkCstSetAval "ENM";
BA_ "SignalLongName" SG_ 1952 DMCabLgtPrkCstSetAval "Delivery Mode Cab Lighting on Park Customization Setting Available";
BA_ "SignalType" SG_ 1952 DMCabLgtPrkCstAvlFlg7 "ENM";
BA_ "SignalLongName" SG_ 1952 DMCabLgtPrkCstAvlFlg7 "Delivery Mode Cab Lighting on Park Customization Availability Flag 7";
BA_ "SignalType" SG_ 1952 DMDrvrDrUnlckPrkCstAvlFlg6 "ENM";
BA_ "SignalLongName" SG_ 1952 DMDrvrDrUnlckPrkCstAvlFlg6 "Delivery Mode Driver Door Unlock on Park Customization Availability Flag 6";
BA_ "SignalType" SG_ 1952 DMDrvrDrUnlckPrkCstAvlFlg5 "ENM";
BA_ "SignalLongName" SG_ 1952 DMDrvrDrUnlckPrkCstAvlFlg5 "Delivery Mode Driver Door Unlock on Park Customization Availability Flag 5";
BA_ "SignalType" SG_ 1952 DMDrvrDrUnlckPrkCstAvlFlg4 "ENM";
BA_ "SignalLongName" SG_ 1952 DMDrvrDrUnlckPrkCstAvlFlg4 "Delivery Mode Driver Door Unlock on Park Customization Availability Flag 4";
BA_ "SignalType" SG_ 1952 DMDrvrDrUnlckPrkCstAvlFlg3 "ENM";
BA_ "SignalLongName" SG_ 1952 DMDrvrDrUnlckPrkCstAvlFlg3 "Delivery Mode Driver Door Unlock on Park Customization Availability Flag 3";
BA_ "SignalType" SG_ 1952 DMDrvrDrUnlckPrkCstAvlFlg2 "ENM";
BA_ "SignalLongName" SG_ 1952 DMDrvrDrUnlckPrkCstAvlFlg2 "Delivery Mode Driver Door Unlock on Park Customization Availability Flag 2";
BA_ "SignalType" SG_ 1952 DMDrvrDrUnlckPrkCstAvlFlg1 "ENM";
BA_ "SignalLongName" SG_ 1952 DMDrvrDrUnlckPrkCstAvlFlg1 "Delivery Mode Driver Door Unlock on Park Customization Availability Flag 1";
BA_ "SignalType" SG_ 1952 DMCrbsdDrUnlckPrkCstSetAval "ENM";
BA_ "SignalLongName" SG_ 1952 DMCrbsdDrUnlckPrkCstSetAval "Delivery Mode Curbside Door Unlock on Park Customization Setting Available";
BA_ "SignalType" SG_ 1952 DMCrbsdDrUnlckPrkCstAvlFlg7 "ENM";
BA_ "SignalLongName" SG_ 1952 DMCrbsdDrUnlckPrkCstAvlFlg7 "Delivery Mode Curbside Door Unlock on Park Customization Availability Flag 7";
BA_ "SignalType" SG_ 1952 DMHrnOutPrkCstAvlFlg7 "ENM";
BA_ "SignalLongName" SG_ 1952 DMHrnOutPrkCstAvlFlg7 "Delivery Mode Horn Out Of Park Customization Availability Flag 7";
BA_ "SignalType" SG_ 1952 DMHrnOutPrkCstAvlFlg6 "ENM";
BA_ "SignalLongName" SG_ 1952 DMHrnOutPrkCstAvlFlg6 "Delivery Mode Horn Out Of Park Customization Availability Flag 6";
BA_ "SignalType" SG_ 1952 DMHrnOutPrkCstAvlFlg5 "ENM";
BA_ "SignalLongName" SG_ 1952 DMHrnOutPrkCstAvlFlg5 "Delivery Mode Horn Out Of Park Customization Availability Flag 5";
BA_ "SignalType" SG_ 1952 DMHrnOutPrkCstAvlFlg4 "ENM";
BA_ "SignalLongName" SG_ 1952 DMHrnOutPrkCstAvlFlg4 "Delivery Mode Horn Out Of Park Customization Availability Flag 4";
BA_ "SignalType" SG_ 1952 DMHrnOutPrkCstAvlFlg3 "ENM";
BA_ "SignalLongName" SG_ 1952 DMHrnOutPrkCstAvlFlg3 "Delivery Mode Horn Out Of Park Customization Availability Flag 3";
BA_ "SignalType" SG_ 1952 DMHrnOutPrkCstAvlFlg2 "ENM";
BA_ "SignalLongName" SG_ 1952 DMHrnOutPrkCstAvlFlg2 "Delivery Mode Horn Out Of Park Customization Availability Flag 2";
BA_ "SignalType" SG_ 1952 DMHrnOutPrkCstAvlFlg1 "ENM";
BA_ "SignalLongName" SG_ 1952 DMHrnOutPrkCstAvlFlg1 "Delivery Mode Horn Out Of Park Customization Availability Flag 1";
BA_ "SignalType" SG_ 1952 DMDrvrDrUnlckPrkCstAvlFlg7 "ENM";
BA_ "SignalLongName" SG_ 1952 DMDrvrDrUnlckPrkCstAvlFlg7 "Delivery Mode Driver Door Unlock on Park Customization Availability Flag 7";
BA_ "SignalLongName" SG_ 1975 IndOtltFrtLtInbdAimRngHrztlOrgn "Indication Outlet Front Left Inboard Aim Range Horizontal Origin";
BA_ "SignalLongName" SG_ 1975 IndOtltFrtLtInbdAimRngHght "Indication Outlet Front Left Inboard Aim Range Height";
BA_ "SignalLongName" SG_ 1975 IndOtltFrtLtInbdAimRngVertOrgn "Indication Outlet Front Left Inboard Aim Range Vertical Origin";
BA_ "SignalLongName" SG_ 1975 IndOtltFrtLtInbdAimRngWdth "Indication Outlet Front Left Inboard Aim Range Width";
BA_ "SignalLongName" SG_ 1975 IndOtltFrtLtInbdHrztlPstn "Indication Outlet Front Left Inboard Horizontal Position";
BA_ "SignalLongName" SG_ 1975 IndOtltFrtLtInbdVertPstn "Indication Outlet Front Left Inboard Vertical Position";
BA_ "SignalLongName" SG_ 1975 IndOtltFrtLtOtbdAimRngHght "Indication Outlet Front Left Outboard Aim Range Height";
BA_ "SignalLongName" SG_ 1975 IndOtltFrtLtOtbdAimRngHrztlOrgn "Indication Outlet Front Left Outboard Aim Range Horizontal Origin";
BA_ "SignalLongName" SG_ 1975 IndOtltFrtLtOtbdAimRngVertOrgn "Indication Outlet Front Left Outboard Aim Range Vertical Origin";
BA_ "SignalLongName" SG_ 1091 IndOtltFrtLtOtbdHrztlPstn "Indication Outlet Front Left Outboard Horizontal Position";
BA_ "SignalLongName" SG_ 1091 IndOtltFrtLtOtbdAimRngWdth "Indication Outlet Front Left Outboard Aim Range Width";
BA_ "SignalLongName" SG_ 1091 IndOtltFrtLtOtbdVertPstn "Indication Outlet Front Left Outboard Vertical Position";
BA_ "SignalLongName" SG_ 1091 IndOtltFrtRtInbdAimRngHght "Indication Outlet Front Right Inboard Aim Range Height";
BA_ "SignalLongName" SG_ 1091 IndOtltFrtRtInbdAimRngHrztlOrgn "Indication Outlet Front Right Inboard Aim Range Horizontal Origin";
BA_ "SignalLongName" SG_ 1091 IndOtltFrtRtInbdAimRngVertOrgn "Indication Outlet Front Right Inboard Aim Range Vertical Origin";
BA_ "SignalLongName" SG_ 1091 IndOtltFrtRtInbdAimRngWdth "Indication Outlet Front Right Inboard Aim Range Width";
BA_ "SignalLongName" SG_ 1091 IndOtltFrtRtInbdHrztlPstn "Indication Outlet Front Right Inboard Horizontal Position";
BA_ "SignalLongName" SG_ 1091 IndOtltFrtRtInbdVertPstn "Indication Outlet Front Right Inboard Vertical Position";
BA_ "SignalLongName" SG_ 1976 IndOtltFrtRtOtbdAimRngHrztlOrgn "Indication Outlet Front Right Outboard Aim Range Horizontal Origin";
BA_ "SignalLongName" SG_ 1976 IndOtltFrtRtOtbdAimRngHght "Indication Outlet Front Right Outboard Aim Range Height";
BA_ "SignalLongName" SG_ 1976 IndOtltFrtRtOtbdAimRngVertOrgn "Indication Outlet Front Right Outboard Aim Range Vertical Origin";
BA_ "SignalLongName" SG_ 1976 IndOtltFrtRtOtbdAimRngWdth "Indication Outlet Front Right Outboard Aim Range Width";
BA_ "SignalLongName" SG_ 1976 IndOtltFrtRtOtbdHrztlPstn "Indication Outlet Front Right Outboard Horizontal Position";
BA_ "SignalLongName" SG_ 1976 IndOtltFrtRtOtbdVertPstn "Indication Outlet Front Right Outboard Vertical Position";
BA_ "SignalLongName" SG_ 1976 IndOtltRrLtInbdAimRngHght "Indication Outlet Rear Left Inboard Aim Range Height";
BA_ "SignalLongName" SG_ 1976 IndOtltRrLtInbdAimRngHrztlOrgn "Indication Outlet Rear Left Inboard Aim Range Horizontal Origin";
BA_ "SignalLongName" SG_ 1976 IndOtltRrLtInbdAimRngVertOrgn "Indication Outlet Rear Left Inboard Aim Range Vertical Origin";
BA_ "SignalLongName" SG_ 1090 IndOtltRrLtInbdHrztlPstn "Indication Outlet Rear Left Inboard Horizontal Position";
BA_ "SignalLongName" SG_ 1090 IndOtltRrLtInbdAimRngWdth "Indication Outlet Rear Left Inboard Aim Range Width";
BA_ "SignalLongName" SG_ 1090 IndOtltRrLtInbdVertPstn "Indication Outlet Rear Left Inboard Vertical Position";
BA_ "SignalLongName" SG_ 1090 IndOtltRrRtInbdAimRngHght "Indication Outlet Rear Right Inboard Aim Range Height";
BA_ "SignalLongName" SG_ 1090 IndOtltRrRtInbdAimRngHrztlOrgn "Indication Outlet Rear Right Inboard Aim Range Horizontal Origin";
BA_ "SignalLongName" SG_ 1090 IndOtltRrRtInbdAimRngVertOrgn "Indication Outlet Rear Right Inboard Aim Range Vertical Origin";
BA_ "SignalLongName" SG_ 1090 IndOtltRrRtInbdAimRngWdth "Indication Outlet Rear Right Inboard Aim Range Width";
BA_ "SignalLongName" SG_ 1090 IndOtltRrRtInbdHrztlPstn "Indication Outlet Rear Right Inboard Horizontal Position";
BA_ "SignalLongName" SG_ 1090 IndOtltRrRtInbdVertPstn "Indication Outlet Rear Right Inboard Vertical Position";
BA_ "SignalType" SG_ 1977 IndAirDstThrdRw "ENM";
BA_ "SignalLongName" SG_ 1977 IndAirDstThrdRw "Indication Air Distribution Third Row";
BA_ "SignalLongName" SG_ 1977 IndTempSetLvlThrdRw "Indication Temperature Setting Level Third Row";
BA_ "SignalType" SG_ 1977 IndTempSetStatThrdRw "ENM";
BA_ "SignalLongName" SG_ 1977 IndTempSetStatThrdRw "Indication Temperature Setting State Third Row";
BA_ "SignalLongName" SG_ 1977 IndBlwSetLvlThrdRw "Indication Blower Setting Level Third Row";
BA_ "SignalType" SG_ 1977 IndBlwSetStatThrdRw "ENM";
BA_ "SignalLongName" SG_ 1977 IndBlwSetStatThrdRw "Indication Blower Setting State Third Row";
BA_ "SignalType" SG_ 1977 IndBlwSetStatRrRt "ENM";
BA_ "SignalLongName" SG_ 1977 IndBlwSetStatRrRt "Indication Blower Setting State Rear Right";
BA_ "SignalType" SG_ 1977 IndBlwSetStatFrtRt "ENM";
BA_ "SignalLongName" SG_ 1977 IndBlwSetStatFrtRt "Indication Blower Setting State Front Right";
BA_ "SignalType" SG_ 1977 IndNckScrfLvlRrRt "ENM";
BA_ "SignalLongName" SG_ 1977 IndNckScrfLvlRrRt "Indication Neck Scarf Level Rear Right";
BA_ "SignalType" SG_ 1977 IndNckScrfLvlRrLt "ENM";
BA_ "SignalLongName" SG_ 1977 IndNckScrfLvlRrLt "Indication Neck Scarf Level Rear Left";
BA_ "SignalType" SG_ 1977 IndNckScrfLvlFrtRt "ENM";
BA_ "SignalLongName" SG_ 1977 IndNckScrfLvlFrtRt "Indication Neck Scarf Level Front Right";
BA_ "SignalType" SG_ 1977 IndNckScrfLvlFrtLt "ENM";
BA_ "SignalLongName" SG_ 1977 IndNckScrfLvlFrtLt "Indication Neck Scarf Level Front Left";
BA_ "SignalType" SG_ 1977 IndOscModeRrRtSet "ENM";
BA_ "SignalLongName" SG_ 1977 IndOscModeRrRtSet "Indication Oscillation Mode Rear Right Setting";
BA_ "SignalType" SG_ 1977 IndOscModeRrLtSet "ENM";
BA_ "SignalLongName" SG_ 1977 IndOscModeRrLtSet "Indication Oscillation Mode Rear Left Setting";
BA_ "SignalType" SG_ 1977 IndOscModeFrtRtSet "ENM";
BA_ "SignalLongName" SG_ 1977 IndOscModeFrtRtSet "Indication Oscillation Mode Front Right Setting";
BA_ "SignalType" SG_ 1977 IndOscModeFrtLtSet "ENM";
BA_ "SignalLongName" SG_ 1977 IndOscModeFrtLtSet "Indication Oscillation Mode Front Left Setting";
BA_ "SignalType" SG_ 1977 IndThrdRwHVACOn "ENM";
BA_ "SignalLongName" SG_ 1977 IndThrdRwHVACOn "Indication Third Row HVAC On";
BA_ "SignalType" SG_ 1977 IndThrdRwHVACLckd "ENM";
BA_ "SignalLongName" SG_ 1977 IndThrdRwHVACLckd "Indication Third Row HVAC Locked";
BA_ "SignalType" SG_ 1977 IndSyncThrdRw "ENM";
BA_ "SignalLongName" SG_ 1977 IndSyncThrdRw "Indication Sync Third Row";
BA_ "SignalType" SG_ 1977 IndRrRtHVACOn "ENM";
BA_ "SignalLongName" SG_ 1977 IndRrRtHVACOn "Indication Rear Right HVAC On";
BA_ "SignalType" SG_ 1977 IndRrLtHVACOn "ENM";
BA_ "SignalLongName" SG_ 1977 IndRrLtHVACOn "Indication Rear Left HVAC On";
BA_ "SignalType" SG_ 1977 IndFrtRtHVACOn "ENM";
BA_ "SignalLongName" SG_ 1977 IndFrtRtHVACOn "Indication Front Right HVAC On";
BA_ "SignalType" SG_ 1977 IndFrtLtHVACOn "ENM";
BA_ "SignalLongName" SG_ 1977 IndFrtLtHVACOn "Indication Front Left HVAC On";
BA_ "SignalType" SG_ 1977 IndCkModeOn "ENM";
BA_ "SignalLongName" SG_ 1977 IndCkModeOn "Indication Cake Mode On";
BA_ "SignalType" SG_ 1977 PwrShdBkGlsShdPs "ENM";
BA_ "SignalLongName" SG_ 1977 PwrShdBkGlsShdPs "Power Shades Back Glass Shade Position";
BA_ "SignalType" SG_ 1977 HtdArmrstSyncCstSetAval "ENM";
BA_ "SignalLongName" SG_ 1977 HtdArmrstSyncCstSetAval "Heated Armrest Sync Customization Setting Available";
BA_ "SignalType" SG_ 1977 HtdArmrstSyncCstCurrSetVal "ENM";
BA_ "SignalLongName" SG_ 1977 HtdArmrstSyncCstCurrSetVal "Heated Armrest Sync Customization Current Setting Value";
BA_ "SignalType" SG_ 1977 ClmCtlThrdRwPwrLtdOpWrnReqActv "ENM";
BA_ "SignalLongName" SG_ 1977 ClmCtlThrdRwPwrLtdOpWrnReqActv "Climate Control Third Row Power Limited Operation Warning Request Active";
BA_ "SignalType" SG_ 1977 IndZnUncpdRrSt "ENM";
BA_ "SignalLongName" SG_ 1977 IndZnUncpdRrSt "Indication Zone Unoccupied Rear Seat";
BA_ "SignalType" SG_ 1977 IndZnUncpdFrtPsngr "ENM";
BA_ "SignalLongName" SG_ 1977 IndZnUncpdFrtPsngr "Indication Zone Unoccupied Front Passenger";
BA_ "SignalType" SG_ 1977 PwrShdDrShdRRPstn "ENM";
BA_ "SignalLongName" SG_ 1977 PwrShdDrShdRRPstn "Power Shades Door Shade Right Rear Position";
BA_ "SignalType" SG_ 1977 PwrShdDrShdLRPstn "ENM";
BA_ "SignalLongName" SG_ 1977 PwrShdDrShdLRPstn "Power Shades Door Shade Left Rear Position";
BA_ "SignalLongName" SG_ 1089 TrlrTireLRInrPres "Trailer Tire Left Rear Inner Pressure Information : Trailer Tire Left Rear Inner Pressure";
BA_ "SignalLongName" SG_ 1089 TrlrTireLtMdlInrPres "Trailer Tire Left Middle Inner Pressure Information : Trailer Tire Left Middle Inner Pressure";
BA_ "SignalType" SG_ 1089 TrlrTireLRInrPres_Inv "ENM";
BA_ "SignalLongName" SG_ 1089 TrlrTireLRInrPres_Inv "Trailer Tire Left Rear Inner Pressure Information : Trailer Tire Left Rear Inner Pressure Invalid";
BA_ "SignalLongName" SG_ 1089 TrlrTireRFInrPres "Trailer Tire Right Front Inner Pressure Information : Trailer Tire Right Front Inner Pressure";
BA_ "SignalType" SG_ 1089 TrlrTireLtMdlInrPres_Inv "ENM";
BA_ "SignalLongName" SG_ 1089 TrlrTireLtMdlInrPres_Inv "Trailer Tire Left Middle Inner Pressure Information : Trailer Tire Left Middle Inner Pressure Invalid";
BA_ "SignalLongName" SG_ 1089 TrlrTireRRInrPres "Trailer Tire Right Rear Inner Pressure Information : Trailer Tire Right Rear Inner Pressure";
BA_ "SignalType" SG_ 1089 TrlrTireRFInrPres_Inv "ENM";
BA_ "SignalLongName" SG_ 1089 TrlrTireRFInrPres_Inv "Trailer Tire Right Front Inner Pressure Information : Trailer Tire Right Front Inner Pressure Invalid";
BA_ "SignalLongName" SG_ 1089 TrlrTireRtMdlInrPres "Trailer Tire Right Middle Inner Pressure Information : Trailer Tire Right Middle Inner Pressure";
BA_ "SignalType" SG_ 1089 TrlrTireRRInrPres_Inv "ENM";
BA_ "SignalLongName" SG_ 1089 TrlrTireRRInrPres_Inv "Trailer Tire Right Rear Inner Pressure Information : Trailer Tire Right Rear Inner Pressure Invalid";
BA_ "SignalLongName" SG_ 1089 TrlrTireLFInrTemp "Trailer Tire Left Front Inner Temperature Information : Trailer Tire Left Front Inner Temperature";
BA_ "SignalType" SG_ 1089 TrlrTireRtMdlInrPres_Inv "ENM";
BA_ "SignalLongName" SG_ 1089 TrlrTireRtMdlInrPres_Inv "Trailer Tire Right Middle Inner Pressure Information : Trailer Tire Right Middle Inner Pressure Invalid";
BA_ "SignalLongName" SG_ 1089 TrlrTireLRInrTemp "Trailer Tire Left Rear Inner Temperature Information : Trailer Tire Left Rear Inner Temperature";
BA_ "SignalType" SG_ 1089 TrlrTireLFInrTemp_Inv "ENM";
BA_ "SignalLongName" SG_ 1089 TrlrTireLFInrTemp_Inv "Trailer Tire Left Front Inner Temperature Information : Trailer Tire Left Front Inner Temperature Invalid";
BA_ "SignalType" SG_ 1089 TrlrTireLFInrTempSts_Inv "ENM";
BA_ "SignalLongName" SG_ 1089 TrlrTireLFInrTempSts_Inv "Trailer Tire Left Front Inner Temperature Status Information : Trailer Tire Left Front Inner Temperature Status Invalid";
BA_ "SignalType" SG_ 1089 TrlrTireLFInrTempSts "ENM";
BA_ "SignalLongName" SG_ 1089 TrlrTireLFInrTempSts "Trailer Tire Left Front Inner Temperature Status Information : Trailer Tire Left Front Inner Temperature Status";
BA_ "SignalType" SG_ 1089 TrlrTireLRInrTemp_Inv "ENM";
BA_ "SignalLongName" SG_ 1089 TrlrTireLRInrTemp_Inv "Trailer Tire Left Rear Inner Temperature Information : Trailer Tire Left Rear Inner Temperature Invalid";
BA_ "SignalType" SG_ 1978 TrlrTireLtMdlInrTemp_Inv "ENM";
BA_ "SignalLongName" SG_ 1978 TrlrTireLtMdlInrTemp_Inv "Trailer Tire Left Middle Inner Temperature Information : Trailer Tire Left Middle Inner Temperature Invalid";
BA_ "SignalLongName" SG_ 1978 TrlrTireLtMdlInrTemp "Trailer Tire Left Middle Inner Temperature Information : Trailer Tire Left Middle Inner Temperature";
BA_ "SignalType" SG_ 1978 TrlrTireRFInrTemp_Inv "ENM";
BA_ "SignalLongName" SG_ 1978 TrlrTireRFInrTemp_Inv "Trailer Tire Right Front Inner Temperature Information : Trailer Tire Right Front Inner Temperature Invalid";
BA_ "SignalLongName" SG_ 1978 TrlrTireRFInrTemp "Trailer Tire Right Front Inner Temperature Information : Trailer Tire Right Front Inner Temperature";
BA_ "SignalType" SG_ 1978 TrlrTireRRInrTemp_Inv "ENM";
BA_ "SignalLongName" SG_ 1978 TrlrTireRRInrTemp_Inv "Trailer Tire Right Rear Inner Temperature Information : Trailer Tire Right Rear Inner Temperature Invalid";
BA_ "SignalLongName" SG_ 1978 TrlrTireRRInrTemp "Trailer Tire Right Rear Inner Temperature Information : Trailer Tire Right Rear Inner Temperature";
BA_ "SignalType" SG_ 1978 TrlrTireRtMdlInrTemp_Inv "ENM";
BA_ "SignalLongName" SG_ 1978 TrlrTireRtMdlInrTemp_Inv "Trailer Tire Right Middle Inner Temperature Information : Trailer Tire Right Middle Inner Temperature Invalid";
BA_ "SignalLongName" SG_ 1978 TrlrTireRtMdlInrTemp "Trailer Tire Right Middle Inner Temperature Information : Trailer Tire Right Middle Inner Temperature";
BA_ "SignalType" SG_ 1978 TrlrTireLtMdlInrPresSts "ENM";
BA_ "SignalLongName" SG_ 1978 TrlrTireLtMdlInrPresSts "Trailer Tire Left Middle Inner Pressure Status Information : Trailer Tire Left Middle Inner Pressure Status";
BA_ "SignalType" SG_ 1978 TrlrTireLRInrPresSts_Inv "ENM";
BA_ "SignalLongName" SG_ 1978 TrlrTireLRInrPresSts_Inv "Trailer Tire Left Rear Inner Pressure Status Information : Trailer Tire Left Rear Inner Pressure Status Invalid";
BA_ "SignalType" SG_ 1978 TrlrTireLRInrPresSts "ENM";
BA_ "SignalLongName" SG_ 1978 TrlrTireLRInrPresSts "Trailer Tire Left Rear Inner Pressure Status Information : Trailer Tire Left Rear Inner Pressure Status";
BA_ "SignalType" SG_ 1978 TrlrTireRRInrPresSts "ENM";
BA_ "SignalLongName" SG_ 1978 TrlrTireRRInrPresSts "Trailer Tire Right Rear Inner Pressure Status Information : Trailer Tire Right Rear Inner Pressure Status";
BA_ "SignalType" SG_ 1978 TrlrTireRFInrPresSts_Inv "ENM";
BA_ "SignalLongName" SG_ 1978 TrlrTireRFInrPresSts_Inv "Trailer Tire Right Front Inner Pressure Status Information : Trailer Tire Right Front Inner Pressure Status Invalid";
BA_ "SignalType" SG_ 1978 TrlrTireRFInrPresSts "ENM";
BA_ "SignalLongName" SG_ 1978 TrlrTireRFInrPresSts "Trailer Tire Right Front Inner Pressure Status Information : Trailer Tire Right Front Inner Pressure Status";
BA_ "SignalType" SG_ 1978 TrlrTireLtMdlInrPresSts_Inv "ENM";
BA_ "SignalLongName" SG_ 1978 TrlrTireLtMdlInrPresSts_Inv "Trailer Tire Left Middle Inner Pressure Status Information : Trailer Tire Left Middle Inner Pressure Status Invalid";
BA_ "SignalType" SG_ 1978 TrlrTireRtMdlInrPresSts "ENM";
BA_ "SignalLongName" SG_ 1978 TrlrTireRtMdlInrPresSts "Trailer Tire Right Middle Inner Pressure Status Information : Trailer Tire Right Middle Inner Pressure Status";
BA_ "SignalType" SG_ 1978 TrlrTireRRInrPresSts_Inv "ENM";
BA_ "SignalLongName" SG_ 1978 TrlrTireRRInrPresSts_Inv "Trailer Tire Right Rear Inner Pressure Status Information : Trailer Tire Right Rear Inner Pressure Status Invalid";
BA_ "SignalType" SG_ 1978 TrlrTireLRInrTempSts_Inv "ENM";
BA_ "SignalLongName" SG_ 1978 TrlrTireLRInrTempSts_Inv "Trailer Tire Left Rear Inner Temperature Status Information : Trailer Tire Left Rear Inner Temperature Status Invalid";
BA_ "SignalType" SG_ 1978 TrlrTireLRInrTempSts "ENM";
BA_ "SignalLongName" SG_ 1978 TrlrTireLRInrTempSts "Trailer Tire Left Rear Inner Temperature Status Information : Trailer Tire Left Rear Inner Temperature Status";
BA_ "SignalType" SG_ 1978 TrlrTireLFTempSts_Inv "ENM";
BA_ "SignalLongName" SG_ 1978 TrlrTireLFTempSts_Inv "Trailer Tire Left Front Temperature Status Information : Trailer Tire Left Front Temperature Status Invalid";
BA_ "SignalType" SG_ 1978 TrlrTireLFTempSts "ENM";
BA_ "SignalLongName" SG_ 1978 TrlrTireLFTempSts "Trailer Tire Left Front Temperature Status Information : Trailer Tire Left Front Temperature Status";
BA_ "SignalType" SG_ 1978 TrlrTireRtMdlInrPresSts_Inv "ENM";
BA_ "SignalLongName" SG_ 1978 TrlrTireRtMdlInrPresSts_Inv "Trailer Tire Right Middle Inner Pressure Status Information : Trailer Tire Right Middle Inner Pressure Status Invalid";
BA_ "SignalType" SG_ 1088 TrlrTireLtMdlTempSts "ENM";
BA_ "SignalLongName" SG_ 1088 TrlrTireLtMdlTempSts "Trailer Tire Left Middle Temperature Status Information : Trailer Tire Left Middle Temperature Status";
BA_ "SignalType" SG_ 1088 TrlrTireLtMdlInrTempSts_Inv "ENM";
BA_ "SignalLongName" SG_ 1088 TrlrTireLtMdlInrTempSts_Inv "Trailer Tire Left Middle Inner Temperature Status Information : Trailer Tire Left Middle Inner Temperature Status Invalid";
BA_ "SignalType" SG_ 1088 TrlrTireLtMdlInrTempSts "ENM";
BA_ "SignalLongName" SG_ 1088 TrlrTireLtMdlInrTempSts "Trailer Tire Left Middle Inner Temperature Status Information : Trailer Tire Left Middle Inner Temperature Status";
BA_ "SignalType" SG_ 1088 TrlrTireLRTempSts_Inv "ENM";
BA_ "SignalLongName" SG_ 1088 TrlrTireLRTempSts_Inv "Trailer Tire Left Rear Temperature Status Information : Trailer Tire Left Rear Temperature Status Invalid";
BA_ "SignalType" SG_ 1088 TrlrTireLRTempSts "ENM";
BA_ "SignalLongName" SG_ 1088 TrlrTireLRTempSts "Trailer Tire Left Rear Temperature Status Information : Trailer Tire Left Rear Temperature Status";
BA_ "SignalType" SG_ 1088 TrlrTireRRInrTempSts "ENM";
BA_ "SignalLongName" SG_ 1088 TrlrTireRRInrTempSts "Trailer Tire Right Rear Inner Temperature Status Information : Trailer Tire Right Rear Inner Temperature Status";
BA_ "SignalType" SG_ 1088 TrlrTireRFTempSts_Inv "ENM";
BA_ "SignalLongName" SG_ 1088 TrlrTireRFTempSts_Inv "Trailer Tire Right Front Temperature Status Information : Trailer Tire Right Front Temperature Status Invalid";
BA_ "SignalType" SG_ 1088 TrlrTireRFTempSts "ENM";
BA_ "SignalLongName" SG_ 1088 TrlrTireRFTempSts "Trailer Tire Right Front Temperature Status Information : Trailer Tire Right Front Temperature Status";
BA_ "SignalType" SG_ 1088 TrlrTireRFInrTempSts_Inv "ENM";
BA_ "SignalLongName" SG_ 1088 TrlrTireRFInrTempSts_Inv "Trailer Tire Right Front Inner Temperature Status Information : Trailer Tire Right Front Inner Temperature Status Invalid";
BA_ "SignalType" SG_ 1088 TrlrTireRFInrTempSts "ENM";
BA_ "SignalLongName" SG_ 1088 TrlrTireRFInrTempSts "Trailer Tire Right Front Inner Temperature Status Information : Trailer Tire Right Front Inner Temperature Status";
BA_ "SignalType" SG_ 1088 TrlrTireLtMdlTempSts_Inv "ENM";
BA_ "SignalLongName" SG_ 1088 TrlrTireLtMdlTempSts_Inv "Trailer Tire Left Middle Temperature Status Information : Trailer Tire Left Middle Temperature Status Invalid";
BA_ "SignalType" SG_ 1088 TrlrTireRtMdlInrTempSts_Inv "ENM";
BA_ "SignalLongName" SG_ 1088 TrlrTireRtMdlInrTempSts_Inv "Trailer Tire Right Middle Inner Temperature Status Information : Trailer Tire Right Middle Inner Temperature Status Invalid";
BA_ "SignalType" SG_ 1088 TrlrTireRtMdlInrTempSts "ENM";
BA_ "SignalLongName" SG_ 1088 TrlrTireRtMdlInrTempSts "Trailer Tire Right Middle Inner Temperature Status Information : Trailer Tire Right Middle Inner Temperature Status";
BA_ "SignalType" SG_ 1088 TrlrTireRRTempSts_Inv "ENM";
BA_ "SignalLongName" SG_ 1088 TrlrTireRRTempSts_Inv "Trailer Tire Right Rear Temperature Status Information : Trailer Tire Right Rear Temperature Status Invalid";
BA_ "SignalType" SG_ 1088 TrlrTireRRTempSts "ENM";
BA_ "SignalLongName" SG_ 1088 TrlrTireRRTempSts "Trailer Tire Right Rear Temperature Status Information : Trailer Tire Right Rear Temperature Status";
BA_ "SignalType" SG_ 1088 TrlrTireRRInrTempSts_Inv "ENM";
BA_ "SignalLongName" SG_ 1088 TrlrTireRRInrTempSts_Inv "Trailer Tire Right Rear Inner Temperature Status Information : Trailer Tire Right Rear Inner Temperature Status Invalid";
BA_ "SignalLongName" SG_ 1088 VarLgtTransGlsRfTntNumCols "Variable Light Transmission Glass Roof Information 1 : Variable Light Transmission Glass Roof Tint Number of Columns";
BA_ "SignalLongName" SG_ 1088 VarLgtTransGlsRfTntNumClrLvls "Variable Light Transmission Glass Roof Information 1 : Variable Light Transmission Glass Roof Tint Number of Clear Levels";
BA_ "SignalType" SG_ 1088 TrlrTireRtMdlTempSts_Inv "ENM";
BA_ "SignalLongName" SG_ 1088 TrlrTireRtMdlTempSts_Inv "Trailer Tire Right Middle Temperature Status Information : Trailer Tire Right Middle Temperature Status Invalid";
BA_ "SignalType" SG_ 1088 TrlrTireRtMdlTempSts "ENM";
BA_ "SignalLongName" SG_ 1088 TrlrTireRtMdlTempSts "Trailer Tire Right Middle Temperature Status Information : Trailer Tire Right Middle Temperature Status";
BA_ "SignalType" SG_ 1088 StHtdRrNumLvlAval "ENM";
BA_ "SignalLongName" SG_ 1088 StHtdRrNumLvlAval "Seat Heated Rear Number of Levels Available";
BA_ "SignalType" SG_ 1088 StHtdFrtNumLvlAval "ENM";
BA_ "SignalLongName" SG_ 1088 StHtdFrtNumLvlAval "Seat Heated Front Number of Levels Available";
BA_ "SignalType" SG_ 1088 VarLgtTransGlsRfTntVirtCtlAval "ENM";
BA_ "SignalLongName" SG_ 1088 VarLgtTransGlsRfTntVirtCtlAval "Variable Light Transmission Glass Roof Information 1 : Variable Light Transmission Glass Roof Tint Virtual Control Available";
BA_ "SignalLongName" SG_ 1088 VarLgtTransGlsRfTntNumRows "Variable Light Transmission Glass Roof Information 1 : Variable Light Transmission Glass Roof Tint Number of Rows";
BA_ "SignalType" SG_ 1088 VirtCtlRrWndShdCtlAval "ENM";
BA_ "SignalLongName" SG_ 1088 VirtCtlRrWndShdCtlAval "Virtual Control Rear Window Shade Control Available";
BA_ "SignalType" SG_ 1088 VirtCtlPrvcySwAval "ENM";
BA_ "SignalLongName" SG_ 1088 VirtCtlPrvcySwAval "Virtual Control Privacy Switch Available";
BA_ "SignalType" SG_ 1088 VirtCtlBkGlsShdCtlAval "ENM";
BA_ "SignalLongName" SG_ 1088 VirtCtlBkGlsShdCtlAval "Virtual Control Back Glass Shade Control Available";
BA_ "SignalType" SG_ 1088 StVntdCoolRrNumLvlAval "ENM";
BA_ "SignalLongName" SG_ 1088 StVntdCoolRrNumLvlAval "Seat Vented or Cooled Rear Number of Levels Available";
BA_ "SignalType" SG_ 1088 StVntdCoolFrtNumLvlAval "ENM";
BA_ "SignalLongName" SG_ 1088 StVntdCoolFrtNumLvlAval "Seat Vented or Cooled Front Number of Levels Available";
BA_ "SignalType" SG_ 738 VarLgtTransGlsRfTntLvlPnl3Set "ENM";
BA_ "SignalLongName" SG_ 738 VarLgtTransGlsRfTntLvlPnl3Set "Variable Light Transmission Glass Roof Information 2 : Variable Light Transmission Glass Roof Tint Level Panel 3 Setting";
BA_ "SignalType" SG_ 738 VarLgtTransGlsRfTntLvlPnl2Set "ENM";
BA_ "SignalLongName" SG_ 738 VarLgtTransGlsRfTntLvlPnl2Set "Variable Light Transmission Glass Roof Information 2 : Variable Light Transmission Glass Roof Tint Level Panel 2 Setting";
BA_ "SignalType" SG_ 738 VarLgtTransGlsRfTntLvlPnl1Set "ENM";
BA_ "SignalLongName" SG_ 738 VarLgtTransGlsRfTntLvlPnl1Set "Variable Light Transmission Glass Roof Information 2 : Variable Light Transmission Glass Roof Tint Level Panel 1 Setting";
BA_ "SignalType" SG_ 738 VarLgtTransGlsRfTntLvlPnl6Set "ENM";
BA_ "SignalLongName" SG_ 738 VarLgtTransGlsRfTntLvlPnl6Set "Variable Light Transmission Glass Roof Information 2 : Variable Light Transmission Glass Roof Tint Level Panel 6 Setting";
BA_ "SignalType" SG_ 738 VarLgtTransGlsRfTntLvlPnl5Set "ENM";
BA_ "SignalLongName" SG_ 738 VarLgtTransGlsRfTntLvlPnl5Set "Variable Light Transmission Glass Roof Information 2 : Variable Light Transmission Glass Roof Tint Level Panel 5 Setting";
BA_ "SignalType" SG_ 738 VarLgtTransGlsRfTntLvlPnl4Set "ENM";
BA_ "SignalLongName" SG_ 738 VarLgtTransGlsRfTntLvlPnl4Set "Variable Light Transmission Glass Roof Information 2 : Variable Light Transmission Glass Roof Tint Level Panel 4 Setting";
BA_ "SignalType" SG_ 738 VarLgtTransGlsRfTntLvlPnl8Set "ENM";
BA_ "SignalLongName" SG_ 738 VarLgtTransGlsRfTntLvlPnl8Set "Variable Light Transmission Glass Roof Information 2 : Variable Light Transmission Glass Roof Tint Level Panel 8 Setting";
BA_ "SignalType" SG_ 738 VarLgtTransGlsRfTntLvlPnl7Set "ENM";
BA_ "SignalLongName" SG_ 738 VarLgtTransGlsRfTntLvlPnl7Set "Variable Light Transmission Glass Roof Information 2 : Variable Light Transmission Glass Roof Tint Level Panel 7 Setting";
BA_ "SignalType" SG_ 738 MaxPwrModeLngPrssReq "ENM";
BA_ "SignalLongName" SG_ 738 MaxPwrModeLngPrssReq "Max Power Mode Long Press Request";
BA_ "SignalType" SG_ 738 VarLgtTransGlsRfVirtCtlMenuReqd "ENM";
BA_ "SignalLongName" SG_ 738 VarLgtTransGlsRfVirtCtlMenuReqd "Variable Light Transmission Glass Roof Virtual Control Menu Requested";
BA_ "SignalType" SG_ 738 VarLgtTransGlsRfTntVirtCtlAllwd "ENM";
BA_ "SignalLongName" SG_ 738 VarLgtTransGlsRfTntVirtCtlAllwd "Variable Light Transmission Glass Roof Information 2 : Variable Light Transmission Glass Roof Tint Virtual Control Allowed";
BA_ "SignalType" SG_ 738 VarLgtTransGlsRfTntAutoSetActv "ENM";
BA_ "SignalLongName" SG_ 738 VarLgtTransGlsRfTntAutoSetActv "Variable Light Transmission Glass Roof Information 2 : Variable Light Transmission Glass Roof Tint Automatic Setting Active";
BA_ "SignalType" SG_ 738 VarLgtTransGlsRfTntLvlSldrSet "ENM";
BA_ "SignalLongName" SG_ 738 VarLgtTransGlsRfTntLvlSldrSet "Variable Light Transmission Glass Roof Information 2 : Variable Light Transmission Glass Roof Tint Level Slider Setting";
BA_ "SignalType" SG_ 738 TrlrTireLkDtnLFSts "ENM";
BA_ "SignalLongName" SG_ 738 TrlrTireLkDtnLFSts "Trailer Tire Leak Detection Left Front Status";
BA_ "SignalType" SG_ 738 TrlrTireLkDtnLFInrSts "ENM";
BA_ "SignalLongName" SG_ 738 TrlrTireLkDtnLFInrSts "Trailer Tire Leak Detection Left Front Inner Status";
BA_ "SignalType" SG_ 738 TrlrTireLkDtnEnblSts "ENM";
BA_ "SignalLongName" SG_ 738 TrlrTireLkDtnEnblSts "Trailer Tire Leak Detection Enable Status";
BA_ "SignalType" SG_ 738 RrClsrAccssVirtCtlAval "ENM";
BA_ "SignalLongName" SG_ 738 RrClsrAccssVirtCtlAval "Rear Closure Access Virtual Control Available";
BA_ "SignalType" SG_ 738 RrClsrAccssVirtCtlAllwd "ENM";
BA_ "SignalLongName" SG_ 738 RrClsrAccssVirtCtlAllwd "Rear Closure Access Virtual Control Allowed";
BA_ "SignalType" SG_ 738 TrlrTireLkDtnLtMdlSts "ENM";
BA_ "SignalLongName" SG_ 738 TrlrTireLkDtnLtMdlSts "Trailer Tire Leak Detection Left Middle Status";
BA_ "SignalType" SG_ 738 TrlrTireLkDtnLtMdlInrSts "ENM";
BA_ "SignalLongName" SG_ 738 TrlrTireLkDtnLtMdlInrSts "Trailer Tire Leak Detection Left Middle Inner Status";
BA_ "SignalType" SG_ 738 TrlrTireLkDtnLRSts "ENM";
BA_ "SignalLongName" SG_ 738 TrlrTireLkDtnLRSts "Trailer Tire Leak Detection Left Rear Status";
BA_ "SignalType" SG_ 738 TrlrTireLkDtnLRInrSts "ENM";
BA_ "SignalLongName" SG_ 738 TrlrTireLkDtnLRInrSts "Trailer Tire Leak Detection Left Rear Inner Status";
BA_ "SignalType" SG_ 738 TrlrTireLkDtnRRSts "ENM";
BA_ "SignalLongName" SG_ 738 TrlrTireLkDtnRRSts "Trailer Tire Leak Detection Right Rear Status";
BA_ "SignalType" SG_ 738 TrlrTireLkDtnRRInrSts "ENM";
BA_ "SignalLongName" SG_ 738 TrlrTireLkDtnRRInrSts "Trailer Tire Leak Detection Right Rear Inner Status";
BA_ "SignalType" SG_ 738 TrlrTireLkDtnRFSts "ENM";
BA_ "SignalLongName" SG_ 738 TrlrTireLkDtnRFSts "Trailer Tire Leak Detection Right Front Status";
BA_ "SignalType" SG_ 738 TrlrTireLkDtnRFInrSts "ENM";
BA_ "SignalLongName" SG_ 738 TrlrTireLkDtnRFInrSts "Trailer Tire Leak Detection Right Front Inner Status";
BA_ "SignalType" SG_ 738 VirtCtlRrWndShdCtlRrAllwd "ENM";
BA_ "SignalLongName" SG_ 738 VirtCtlRrWndShdCtlRrAllwd "Virtual Control Rear Window Shade Control Rear Allowed";
BA_ "SignalType" SG_ 738 VirtCtlRrWndShdCtlFrtAllwd "ENM";
BA_ "SignalLongName" SG_ 738 VirtCtlRrWndShdCtlFrtAllwd "Virtual Control Rear Window Shade Control Front Allowed";
BA_ "SignalType" SG_ 738 TrlrTireLkDtnWrstCsSts "ENM";
BA_ "SignalLongName" SG_ 738 TrlrTireLkDtnWrstCsSts "Trailer Tire Leak Detection Worst Case Status";
BA_ "SignalType" SG_ 738 TrlrTireLkDtnRtMdlSts "ENM";
BA_ "SignalLongName" SG_ 738 TrlrTireLkDtnRtMdlSts "Trailer Tire Leak Detection Right Middle Status";
BA_ "SignalType" SG_ 738 TrlrTireLkDtnRtMdlInrSts "ENM";
BA_ "SignalLongName" SG_ 738 TrlrTireLkDtnRtMdlInrSts "Trailer Tire Leak Detection Right Middle Inner Status";
BA_ "SignalType" SG_ 1350 OccptLtBehindAlrmDlyDrvrResp "ENM";
BA_ "SignalLongName" SG_ 1350 OccptLtBehindAlrmDlyDrvrResp "Occupant Left Behind Alarm Delay Driver Response";
BA_ "SignalLongName" SG_ 1087 TrlrTireLFInrSnsrIdfr "Trailer Tire Left Front Inner Sensor Identifier";
BA_ "SignalLongName" SG_ 1087 TrlrTireLRInrSnsrIdfr "Trailer Tire Left Rear Inner Sensor Identifier";
BA_ "SignalLongName" SG_ 1980 TrlrTireLtMdlInrSnsrIdfr "Trailer Tire Left Middle Inner Sensor Identifier";
BA_ "SignalLongName" SG_ 1980 TrlrTireRFInrSnsrIdfr "Trailer Tire Right Front Inner Sensor Identifier";
BA_ "SignalLongName" SG_ 1086 TrlrTireRRInrSnsrIdfr "Trailer Tire Right Rear Inner Sensor Identifier";
BA_ "SignalLongName" SG_ 1086 TrlrTireRtMdlInrSnsrIdfr "Trailer Tire Right Middle Inner Sensor Identifier";
BA_ "SignalLongName" SG_ 2004 TnDrvrOvrspdWrnCstLvlMaxAlwdVal "Teen Driver Overspeed Warning Customization Range : Teen Driver Overspeed Warning Customization Level Maximum Allowed Value";
BA_ "SignalLongName" SG_ 2004 TnDrvrOvrspdWrnCstLvlMinAlwdVal "Teen Driver Overspeed Warning Customization Range : Teen Driver Overspeed Warning Customization Level Minimum Allowed Value";
BA_ "SignalType" SG_ 2004 OccptLtBehindRmndrCstAvlFlg4 "ENM";
BA_ "SignalLongName" SG_ 2004 OccptLtBehindRmndrCstAvlFlg4 "Occupant Left Behind Reminder Customization Availability Flag 4";
BA_ "SignalType" SG_ 2004 OccptLtBehindRmndrCstAvlFlg3 "ENM";
BA_ "SignalLongName" SG_ 2004 OccptLtBehindRmndrCstAvlFlg3 "Occupant Left Behind Reminder Customization Availability Flag 3";
BA_ "SignalType" SG_ 2004 OccptLtBehindRmndrCstAvlFlg2 "ENM";
BA_ "SignalLongName" SG_ 2004 OccptLtBehindRmndrCstAvlFlg2 "Occupant Left Behind Reminder Customization Availability Flag 2";
BA_ "SignalType" SG_ 2004 OccptLtBehindRmndrCstAvlFlg1 "ENM";
BA_ "SignalLongName" SG_ 2004 OccptLtBehindRmndrCstAvlFlg1 "Occupant Left Behind Reminder Customization Availability Flag 1";
BA_ "SignalLongName" SG_ 2004 OccptLtBehindAlrmDlyVal "Occupant Left Behind Alarm Delay Value";
BA_ "SignalType" SG_ 2004 IndMcrClmStSyncRrRt "ENM";
BA_ "SignalLongName" SG_ 2004 IndMcrClmStSyncRrRt "Indication Micro Climate Seat Sync Rear Right";
BA_ "SignalType" SG_ 2004 IndMcrClmStSyncRrLt "ENM";
BA_ "SignalLongName" SG_ 2004 IndMcrClmStSyncRrLt "Indication Micro Climate Seat Sync Rear Left";
BA_ "SignalType" SG_ 2004 IndMcrClmStSyncFrtRt "ENM";
BA_ "SignalLongName" SG_ 2004 IndMcrClmStSyncFrtRt "Indication Micro Climate Seat Sync Front Right";
BA_ "SignalType" SG_ 2004 IndMcrClmStSyncFrtLt "ENM";
BA_ "SignalLongName" SG_ 2004 IndMcrClmStSyncFrtLt "Indication Micro Climate Seat Sync Front Left";
BA_ "SignalType" SG_ 2004 OccptLtBehindRmndrCstSetAval "ENM";
BA_ "SignalLongName" SG_ 2004 OccptLtBehindRmndrCstSetAval "Occupant Left Behind Reminder Customization Setting Available";
BA_ "SignalType" SG_ 2004 OccptLtBehindRmndrCstAvlFlg7 "ENM";
BA_ "SignalLongName" SG_ 2004 OccptLtBehindRmndrCstAvlFlg7 "Occupant Left Behind Reminder Customization Availability Flag 7";
BA_ "SignalType" SG_ 2004 OccptLtBehindRmndrCstAvlFlg6 "ENM";
BA_ "SignalLongName" SG_ 2004 OccptLtBehindRmndrCstAvlFlg6 "Occupant Left Behind Reminder Customization Availability Flag 6";
BA_ "SignalType" SG_ 2004 OccptLtBehindRmndrCstAvlFlg5 "ENM";
BA_ "SignalLongName" SG_ 2004 OccptLtBehindRmndrCstAvlFlg5 "Occupant Left Behind Reminder Customization Availability Flag 5";
BA_ "SignalType" SG_ 2004 McrClmStSyncRrRtAval "ENM";
BA_ "SignalLongName" SG_ 2004 McrClmStSyncRrRtAval "Micro Climate Seat Sync Rear Right Available";
BA_ "SignalType" SG_ 2004 McrClmStSyncRrLtAval "ENM";
BA_ "SignalLongName" SG_ 2004 McrClmStSyncRrLtAval "Micro Climate Seat Sync Rear Left Available";
BA_ "SignalType" SG_ 2004 McrClmStSyncFrtRtAval "ENM";
BA_ "SignalLongName" SG_ 2004 McrClmStSyncFrtRtAval "Micro Climate Seat Sync Front Right Available";
BA_ "SignalType" SG_ 2004 McrClmStSyncFrtLtAval "ENM";
BA_ "SignalLongName" SG_ 2004 McrClmStSyncFrtLtAval "Micro Climate Seat Sync Front Left Available";
BA_ "SignalLongName" SG_ 1293 WhlCntrCapLgtRmpTm "Wheel Center Cap Light Command : Wheel Center Cap Light Ramp Time";
BA_ "SignalType" SG_ 1293 WhlCntrCapLgtRFCmd "ENM";
BA_ "SignalLongName" SG_ 1293 WhlCntrCapLgtRFCmd "Wheel Center Cap Light Command : Wheel Center Cap Light Right Front Command";
BA_ "SignalType" SG_ 1293 WhlCntrCapLgtLRCmd "ENM";
BA_ "SignalLongName" SG_ 1293 WhlCntrCapLgtLRCmd "Wheel Center Cap Light Command : Wheel Center Cap Light Left Rear Command";
BA_ "SignalType" SG_ 1293 WhlCntrCapLgtLFCmd "ENM";
BA_ "SignalLongName" SG_ 1293 WhlCntrCapLgtLFCmd "Wheel Center Cap Light Command : Wheel Center Cap Light Left Front Command";
BA_ "SignalType" SG_ 1293 WhlCntrCapLgtCommReqd "ENM";
BA_ "SignalLongName" SG_ 1293 WhlCntrCapLgtCommReqd "Wheel Center Cap Light Communication Requested";
BA_ "SignalType" SG_ 1293 OccptLtBehindFltIndOn "ENM";
BA_ "SignalLongName" SG_ 1293 OccptLtBehindFltIndOn "Occupant Left Behind Fault Indication On";
BA_ "SignalType" SG_ 1293 WhlCntrCapLgtRRCmd "ENM";
BA_ "SignalLongName" SG_ 1293 WhlCntrCapLgtRRCmd "Wheel Center Cap Light Command : Wheel Center Cap Light Right Rear Command";
BA_ "SignalType" SG_ 1293 OccptLtBehindRrRmndrIndOn "ENM";
BA_ "SignalLongName" SG_ 1293 OccptLtBehindRrRmndrIndOn "Occupant Left Behind Rear Reminder Indication On";
BA_ "SignalType" SG_ 1293 OccptLtBehindRmndrCstCurrSetVal "ENM";
BA_ "SignalLongName" SG_ 1293 OccptLtBehindRmndrCstCurrSetVal "Occupant Left Behind Reminder Customization Current Setting Value";
BA_ "SignalType" SG_ 1293 OccptLtBehindIndOn "ENM";
BA_ "SignalLongName" SG_ 1293 OccptLtBehindIndOn "Occupant Left Behind Indication On";
BA_ "SignalType" SG_ 1981 IndArflQntyFrtLtInbrdOtltSet "ENM";
BA_ "SignalLongName" SG_ 1981 IndArflQntyFrtLtInbrdOtltSet "Indication HVAC Settings 2 : Indication Airflow Quantity Front Left Inboard Outlet Setting";
BA_ "SignalType" SG_ 1981 IndAirDstEnblsVntArflRrRt "ENM";
BA_ "SignalLongName" SG_ 1981 IndAirDstEnblsVntArflRrRt "Indication HVAC Settings 2 : Indication Air Distribution Enables Vent Airflow Rear Right";
BA_ "SignalType" SG_ 1981 IndAirDstEnblsVntArflRrLt "ENM";
BA_ "SignalLongName" SG_ 1981 IndAirDstEnblsVntArflRrLt "Indication HVAC Settings 2 : Indication Air Distribution Enables Vent Airflow Rear Left";
BA_ "SignalType" SG_ 1981 IndAirDstEnblsVntArflFrtRt "ENM";
BA_ "SignalLongName" SG_ 1981 IndAirDstEnblsVntArflFrtRt "Indication HVAC Settings 2 : Indication Air Distribution Enables Vent Airflow Front Right";
BA_ "SignalType" SG_ 1981 IndAirDstEnblsVntArflFrtLt "ENM";
BA_ "SignalLongName" SG_ 1981 IndAirDstEnblsVntArflFrtLt "Indication HVAC Settings 2 : Indication Air Distribution Enables Vent Airflow Front Left";
BA_ "SignalType" SG_ 1981 HtdWprPrkDcrAvl "ENM";
BA_ "SignalLongName" SG_ 1981 HtdWprPrkDcrAvl "Indication HVAC Settings 2 : Heated Wiper Park Deicer Availability";
BA_ "SignalType" SG_ 1981 IndArflQntyFrtRtOtbrdOtltSet "ENM";
BA_ "SignalLongName" SG_ 1981 IndArflQntyFrtRtOtbrdOtltSet "Indication HVAC Settings 2 : Indication Airflow Quantity Front Right Outboard Outlet Setting";
BA_ "SignalType" SG_ 1981 IndArflQntyFrtRtInbrdOtltSet "ENM";
BA_ "SignalLongName" SG_ 1981 IndArflQntyFrtRtInbrdOtltSet "Indication HVAC Settings 2 : Indication Airflow Quantity Front Right Inboard Outlet Setting";
BA_ "SignalType" SG_ 1981 IndArflQntyFrtLtOtbrdOtltSet "ENM";
BA_ "SignalLongName" SG_ 1981 IndArflQntyFrtLtOtbrdOtltSet "Indication HVAC Settings 2 : Indication Airflow Quantity Front Left Outboard Outlet Setting";
BA_ "SignalType" SG_ 1981 IndArflQntyRrRtInbrdOtltSet "ENM";
BA_ "SignalLongName" SG_ 1981 IndArflQntyRrRtInbrdOtltSet "Indication HVAC Settings 2 : Indication Airflow Quantity Rear Right Inboard Outlet Setting";
BA_ "SignalType" SG_ 1981 IndArflQntyRrLtInbrdOtltSet "ENM";
BA_ "SignalLongName" SG_ 1981 IndArflQntyRrLtInbrdOtltSet "Indication HVAC Settings 2 : Indication Airflow Quantity Rear Left Inboard Outlet Setting";
BA_ "SignalLongName" SG_ 1981 IndHrztlPstnRrRtInbrdOtltManSet "Indication HVAC Settings 2 : Indication Horizontal Position Rear Right Inboard Outlet Manual Setting";
BA_ "SignalLongName" SG_ 1981 IndHrztlPstnRrLtInbrdOtltManSet "Indication HVAC Settings 2 : Indication Horizontal Position Rear Left Inboard Outlet Manual Setting";
BA_ "SignalLongName" SG_ 1981 IndVertPstnRrLtInbrdOtltManSet "Indication HVAC Settings 2 : Indication Vertical Position Rear Left Inboard Outlet Manual Setting";
BA_ "SignalLongName" SG_ 1981 IndVertPstnRrRtInbrdOtltManSet "Indication HVAC Settings 2 : Indication Vertical Position Rear Right Inboard Outlet Manual Setting";
BA_ "SignalType" SG_ 1981 IndWprPrkDcr "ENM";
BA_ "SignalLongName" SG_ 1981 IndWprPrkDcr "Indication HVAC Settings 2 : Indication Wiper Park Deicer";
VAL_ 1444 ArflBsdOnOccpFrtPsCstAvlFlg2 0 "FALSE" 1 "TRUE" ;
VAL_ 1444 ArflBsdOnOccpFrtPsCstAvlFlg1 0 "FALSE" 1 "TRUE" ;
VAL_ 1444 TrlrTireLFInrPresSts_Inv 0 "FALSE" 1 "TRUE" ;
VAL_ 1444 TrlrTireLFInrPresSts 0 "Unknown" 1 "Normal" 2 "Low Pressure" 3 "Malfunction" 4 "Learning in Progress" 5 "Learn Tire" 6 "Tire Learning Complete" 7 "High Pressure" 8 "High Temperature" ;
VAL_ 1444 TrlrTireLFInrPres_Inv 0 "FALSE" 1 "TRUE" ;
VAL_ 1444 ArflBsdOnOccpRrPsCstAvlFlg2 0 "FALSE" 1 "TRUE" ;
VAL_ 1444 ArflBsdOnOccpRrPsCstAvlFlg1 0 "FALSE" 1 "TRUE" ;
VAL_ 1444 ArflBsdOnOccpFrtPsCstSetAval 0 "FALSE" 1 "TRUE" ;
VAL_ 1444 ArflBsdOnOccpFrtPsCstAvlFlg7 0 "FALSE" 1 "TRUE" ;
VAL_ 1444 ArflBsdOnOccpFrtPsCstAvlFlg6 0 "FALSE" 1 "TRUE" ;
VAL_ 1444 ArflBsdOnOccpFrtPsCstAvlFlg5 0 "FALSE" 1 "TRUE" ;
VAL_ 1444 ArflBsdOnOccpFrtPsCstAvlFlg4 0 "FALSE" 1 "TRUE" ;
VAL_ 1444 ArflBsdOnOccpFrtPsCstAvlFlg3 0 "FALSE" 1 "TRUE" ;
VAL_ 1444 AutoAirOtltAmgCstAvlFlg2 0 "FALSE" 1 "TRUE" ;
VAL_ 1444 AutoAirOtltAmgCstAvlFlg1 0 "FALSE" 1 "TRUE" ;
VAL_ 1444 ArflBsdOnOccpRrPsCstSetAval 0 "FALSE" 1 "TRUE" ;
VAL_ 1444 ArflBsdOnOccpRrPsCstAvlFlg7 0 "FALSE" 1 "TRUE" ;
VAL_ 1444 ArflBsdOnOccpRrPsCstAvlFlg6 0 "FALSE" 1 "TRUE" ;
VAL_ 1444 ArflBsdOnOccpRrPsCstAvlFlg5 0 "FALSE" 1 "TRUE" ;
VAL_ 1444 ArflBsdOnOccpRrPsCstAvlFlg4 0 "FALSE" 1 "TRUE" ;
VAL_ 1444 ArflBsdOnOccpRrPsCstAvlFlg3 0 "FALSE" 1 "TRUE" ;
VAL_ 1444 AutoNckScrfCstAvlFlg2 0 "FALSE" 1 "TRUE" ;
VAL_ 1444 AutoNckScrfCstAvlFlg1 0 "FALSE" 1 "TRUE" ;
VAL_ 1444 AutoAirOtltAmgCstSetAval 0 "FALSE" 1 "TRUE" ;
VAL_ 1444 AutoAirOtltAmgCstAvlFlg7 0 "FALSE" 1 "TRUE" ;
VAL_ 1444 AutoAirOtltAmgCstAvlFlg6 0 "FALSE" 1 "TRUE" ;
VAL_ 1444 AutoAirOtltAmgCstAvlFlg5 0 "FALSE" 1 "TRUE" ;
VAL_ 1444 AutoAirOtltAmgCstAvlFlg4 0 "FALSE" 1 "TRUE" ;
VAL_ 1444 AutoAirOtltAmgCstAvlFlg3 0 "FALSE" 1 "TRUE" ;
VAL_ 1444 Aux2AmbtAnmCtlCstAvlFlg10 0 "FALSE" 1 "TRUE" ;
VAL_ 1444 Aux2AmbtAnmCtlCstAvlFlg1 0 "FALSE" 1 "TRUE" ;
VAL_ 1444 AutoNckScrfCstSetAval 0 "FALSE" 1 "TRUE" ;
VAL_ 1444 AutoNckScrfCstAvlFlg7 0 "FALSE" 1 "TRUE" ;
VAL_ 1444 AutoNckScrfCstAvlFlg6 0 "FALSE" 1 "TRUE" ;
VAL_ 1444 AutoNckScrfCstAvlFlg5 0 "FALSE" 1 "TRUE" ;
VAL_ 1444 AutoNckScrfCstAvlFlg4 0 "FALSE" 1 "TRUE" ;
VAL_ 1444 AutoNckScrfCstAvlFlg3 0 "FALSE" 1 "TRUE" ;
VAL_ 1444 SCAPwrDrLckAllVirtCtlRrAllwd 0 "Not Allowed" 1 "Allowed" ;
VAL_ 1444 SCAPwrDrLckAllVirtCtlFrtAllwd 0 "Not Allowed" 1 "Allowed" ;
VAL_ 1444 SCAPwrDrLckAllVirtCtlAval 0 "Not Available" 1 "Available" ;
VAL_ 1444 DMHrnOutPrkCstSetAval 0 "FALSE" 1 "TRUE" ;
VAL_ 1444 DMDrvrDrUnlckPrkCstSetAval 0 "FALSE" 1 "TRUE" ;
VAL_ 1444 Aux2AmbtColrCtlCstAvlFlg1 0 "FALSE" 1 "TRUE" ;
VAL_ 1444 Aux2AmbtAnmCtlCstAvlFlg12 0 "FALSE" 1 "TRUE" ;
VAL_ 1444 Aux2AmbtAnmCtlCstAvlFlg11 0 "FALSE" 1 "TRUE" ;
VAL_ 1444 IndThrdRowHVACAuto 0 "FALSE" 1 "TRUE" ;
VAL_ 1444 IndRrRtHVACAuto 0 "FALSE" 1 "TRUE" ;
VAL_ 1444 IndRrLtHVACAuto 0 "FALSE" 1 "TRUE" ;
VAL_ 1444 IndFrtRtHVACAuto 0 "FALSE" 1 "TRUE" ;
VAL_ 1444 IndFrtLtHVACAuto 0 "FALSE" 1 "TRUE" ;
VAL_ 1444 SCAPwrDrUnlckAllVirtCtlRrAllwd 0 "Not Allowed" 1 "Allowed" ;
VAL_ 1444 SCAPwrDrUnlckAllVirtCtlFrtAllwd 0 "Not Allowed" 1 "Allowed" ;
VAL_ 1444 SCAPwrDrUnlckAllVirtCtlAval 0 "Not Available" 1 "Available" ;
VAL_ 1924 Aux2AmbtAnmCtlCstAvlFlg6 0 "FALSE" 1 "TRUE" ;
VAL_ 1924 Aux2AmbtAnmCtlCstAvlFlg5 0 "FALSE" 1 "TRUE" ;
VAL_ 1924 Aux2AmbtAnmCtlCstAvlFlg4 0 "FALSE" 1 "TRUE" ;
VAL_ 1924 Aux2AmbtAnmCtlCstAvlFlg3 0 "FALSE" 1 "TRUE" ;
VAL_ 1924 Aux2AmbtAnmCtlCstAvlFlg2 0 "FALSE" 1 "TRUE" ;
VAL_ 1924 Aux2AmbtAnmCtlCstAvlFlg15 0 "FALSE" 1 "TRUE" ;
VAL_ 1924 Aux2AmbtAnmCtlCstAvlFlg14 0 "FALSE" 1 "TRUE" ;
VAL_ 1924 Aux2AmbtAnmCtlCstAvlFlg13 0 "FALSE" 1 "TRUE" ;
VAL_ 1924 Aux2AmbtBrghtnsCtlCstAvlFlg4 0 "FALSE" 1 "TRUE" ;
VAL_ 1924 Aux2AmbtBrghtnsCtlCstAvlFlg3 0 "FALSE" 1 "TRUE" ;
VAL_ 1924 Aux2AmbtBrghtnsCtlCstAvlFlg2 0 "FALSE" 1 "TRUE" ;
VAL_ 1924 Aux2AmbtBrghtnsCtlCstAvlFlg1 0 "FALSE" 1 "TRUE" ;
VAL_ 1924 Aux2AmbtAnmCtlCstSetAval 0 "FALSE" 1 "TRUE" ;
VAL_ 1924 Aux2AmbtAnmCtlCstAvlFlg9 0 "FALSE" 1 "TRUE" ;
VAL_ 1924 Aux2AmbtAnmCtlCstAvlFlg8 0 "FALSE" 1 "TRUE" ;
VAL_ 1924 Aux2AmbtAnmCtlCstAvlFlg7 0 "FALSE" 1 "TRUE" ;
VAL_ 1924 Aux3AmbtColrCtlCstAvlFlg82 0 "FALSE" 1 "TRUE" ;
VAL_ 1924 Aux3AmbtColrCtlCstAvlFlg81 0 "FALSE" 1 "TRUE" ;
VAL_ 1924 Aux3AmbtColrCtlCstAvlFlg80 0 "FALSE" 1 "TRUE" ;
VAL_ 1924 Aux3AmbtColrCtlCstAvlFlg8 0 "FALSE" 1 "TRUE" ;
VAL_ 1924 Aux2AmbtBrghtnsCtlCstSetAval 0 "FALSE" 1 "TRUE" ;
VAL_ 1924 Aux2AmbtBrghtnsCtlCstAvlFlg7 0 "FALSE" 1 "TRUE" ;
VAL_ 1924 Aux2AmbtBrghtnsCtlCstAvlFlg6 0 "FALSE" 1 "TRUE" ;
VAL_ 1924 Aux2AmbtBrghtnsCtlCstAvlFlg5 0 "FALSE" 1 "TRUE" ;
VAL_ 1924 Aux3AmbtColrCtlCstAvlFlg9 0 "FALSE" 1 "TRUE" ;
VAL_ 1924 Aux3AmbtColrCtlCstAvlFlg89 0 "FALSE" 1 "TRUE" ;
VAL_ 1924 Aux3AmbtColrCtlCstAvlFlg88 0 "FALSE" 1 "TRUE" ;
VAL_ 1924 Aux3AmbtColrCtlCstAvlFlg87 0 "FALSE" 1 "TRUE" ;
VAL_ 1924 Aux3AmbtColrCtlCstAvlFlg86 0 "FALSE" 1 "TRUE" ;
VAL_ 1924 Aux3AmbtColrCtlCstAvlFlg85 0 "FALSE" 1 "TRUE" ;
VAL_ 1924 Aux3AmbtColrCtlCstAvlFlg84 0 "FALSE" 1 "TRUE" ;
VAL_ 1924 Aux3AmbtColrCtlCstAvlFlg83 0 "FALSE" 1 "TRUE" ;
VAL_ 1924 Aux3AmbtColrCtlCstAvlFlg97 0 "FALSE" 1 "TRUE" ;
VAL_ 1924 Aux3AmbtColrCtlCstAvlFlg96 0 "FALSE" 1 "TRUE" ;
VAL_ 1924 Aux3AmbtColrCtlCstAvlFlg95 0 "FALSE" 1 "TRUE" ;
VAL_ 1924 Aux3AmbtColrCtlCstAvlFlg94 0 "FALSE" 1 "TRUE" ;
VAL_ 1924 Aux3AmbtColrCtlCstAvlFlg93 0 "FALSE" 1 "TRUE" ;
VAL_ 1924 Aux3AmbtColrCtlCstAvlFlg92 0 "FALSE" 1 "TRUE" ;
VAL_ 1924 Aux3AmbtColrCtlCstAvlFlg91 0 "FALSE" 1 "TRUE" ;
VAL_ 1924 Aux3AmbtColrCtlCstAvlFlg90 0 "FALSE" 1 "TRUE" ;
VAL_ 1924 CbnAirClnFltrtnCstAvlFlg5 0 "FALSE" 1 "TRUE" ;
VAL_ 1924 CbnAirClnFltrtnCstAvlFlg4 0 "FALSE" 1 "TRUE" ;
VAL_ 1924 CbnAirClnFltrtnCstAvlFlg3 0 "FALSE" 1 "TRUE" ;
VAL_ 1924 CbnAirClnFltrtnCstAvlFlg2 0 "FALSE" 1 "TRUE" ;
VAL_ 1924 CbnAirClnFltrtnCstAvlFlg1 0 "FALSE" 1 "TRUE" ;
VAL_ 1924 Aux3AmbtColrCtlCstSetAval 0 "FALSE" 1 "TRUE" ;
VAL_ 1924 Aux3AmbtColrCtlCstAvlFlg99 0 "FALSE" 1 "TRUE" ;
VAL_ 1924 Aux3AmbtColrCtlCstAvlFlg98 0 "FALSE" 1 "TRUE" ;
VAL_ 1924 HtdArmrstSyncCstAvlFlg5 0 "FALSE" 1 "TRUE" ;
VAL_ 1924 HtdArmrstSyncCstAvlFlg4 0 "FALSE" 1 "TRUE" ;
VAL_ 1924 HtdArmrstSyncCstAvlFlg3 0 "FALSE" 1 "TRUE" ;
VAL_ 1924 HtdArmrstSyncCstAvlFlg2 0 "FALSE" 1 "TRUE" ;
VAL_ 1924 HtdArmrstSyncCstAvlFlg1 0 "FALSE" 1 "TRUE" ;
VAL_ 1924 CbnAirClnFltrtnCstSetAval 0 "FALSE" 1 "TRUE" ;
VAL_ 1924 CbnAirClnFltrtnCstAvlFlg7 0 "FALSE" 1 "TRUE" ;
VAL_ 1924 CbnAirClnFltrtnCstAvlFlg6 0 "FALSE" 1 "TRUE" ;
VAL_ 1924 TnDrvrSpdLimRmtCstCurrSetVal 0 "Setting Unknown" 1 "Off" 2 "On" ;
VAL_ 1924 TnDrvrActvRmtCstCurrSetVal 0 "Setting Unknown" 1 "Off" 2 "On" ;
VAL_ 1924 HtdArmrstSyncCstAvlFlg7 0 "FALSE" 1 "TRUE" ;
VAL_ 1924 HtdArmrstSyncCstAvlFlg6 0 "FALSE" 1 "TRUE" ;
VAL_ 1925 Aux2AmbtColrCtlCstAvlFlg106 0 "FALSE" 1 "TRUE" ;
VAL_ 1925 Aux2AmbtColrCtlCstAvlFlg105 0 "FALSE" 1 "TRUE" ;
VAL_ 1925 Aux2AmbtColrCtlCstAvlFlg104 0 "FALSE" 1 "TRUE" ;
VAL_ 1925 Aux2AmbtColrCtlCstAvlFlg103 0 "FALSE" 1 "TRUE" ;
VAL_ 1925 Aux2AmbtColrCtlCstAvlFlg102 0 "FALSE" 1 "TRUE" ;
VAL_ 1925 Aux2AmbtColrCtlCstAvlFlg101 0 "FALSE" 1 "TRUE" ;
VAL_ 1925 Aux2AmbtColrCtlCstAvlFlg100 0 "FALSE" 1 "TRUE" ;
VAL_ 1925 Aux2AmbtColrCtlCstAvlFlg10 0 "FALSE" 1 "TRUE" ;
VAL_ 1925 Aux2AmbtColrCtlCstAvlFlg113 0 "FALSE" 1 "TRUE" ;
VAL_ 1925 Aux2AmbtColrCtlCstAvlFlg112 0 "FALSE" 1 "TRUE" ;
VAL_ 1925 Aux2AmbtColrCtlCstAvlFlg111 0 "FALSE" 1 "TRUE" ;
VAL_ 1925 Aux2AmbtColrCtlCstAvlFlg110 0 "FALSE" 1 "TRUE" ;
VAL_ 1925 Aux2AmbtColrCtlCstAvlFlg11 0 "FALSE" 1 "TRUE" ;
VAL_ 1925 Aux2AmbtColrCtlCstAvlFlg109 0 "FALSE" 1 "TRUE" ;
VAL_ 1925 Aux2AmbtColrCtlCstAvlFlg108 0 "FALSE" 1 "TRUE" ;
VAL_ 1925 Aux2AmbtColrCtlCstAvlFlg107 0 "FALSE" 1 "TRUE" ;
VAL_ 1925 Aux2AmbtColrCtlCstAvlFlg120 0 "FALSE" 1 "TRUE" ;
VAL_ 1925 Aux2AmbtColrCtlCstAvlFlg12 0 "FALSE" 1 "TRUE" ;
VAL_ 1925 Aux2AmbtColrCtlCstAvlFlg119 0 "FALSE" 1 "TRUE" ;
VAL_ 1925 Aux2AmbtColrCtlCstAvlFlg118 0 "FALSE" 1 "TRUE" ;
VAL_ 1925 Aux2AmbtColrCtlCstAvlFlg117 0 "FALSE" 1 "TRUE" ;
VAL_ 1925 Aux2AmbtColrCtlCstAvlFlg116 0 "FALSE" 1 "TRUE" ;
VAL_ 1925 Aux2AmbtColrCtlCstAvlFlg115 0 "FALSE" 1 "TRUE" ;
VAL_ 1925 Aux2AmbtColrCtlCstAvlFlg114 0 "FALSE" 1 "TRUE" ;
VAL_ 1925 Aux2AmbtColrCtlCstAvlFlg13 0 "FALSE" 1 "TRUE" ;
VAL_ 1925 Aux2AmbtColrCtlCstAvlFlg127 0 "FALSE" 1 "TRUE" ;
VAL_ 1925 Aux2AmbtColrCtlCstAvlFlg126 0 "FALSE" 1 "TRUE" ;
VAL_ 1925 Aux2AmbtColrCtlCstAvlFlg125 0 "FALSE" 1 "TRUE" ;
VAL_ 1925 Aux2AmbtColrCtlCstAvlFlg124 0 "FALSE" 1 "TRUE" ;
VAL_ 1925 Aux2AmbtColrCtlCstAvlFlg123 0 "FALSE" 1 "TRUE" ;
VAL_ 1925 Aux2AmbtColrCtlCstAvlFlg122 0 "FALSE" 1 "TRUE" ;
VAL_ 1925 Aux2AmbtColrCtlCstAvlFlg121 0 "FALSE" 1 "TRUE" ;
VAL_ 1925 Aux2AmbtColrCtlCstAvlFlg20 0 "FALSE" 1 "TRUE" ;
VAL_ 1925 Aux2AmbtColrCtlCstAvlFlg2 0 "FALSE" 1 "TRUE" ;
VAL_ 1925 Aux2AmbtColrCtlCstAvlFlg19 0 "FALSE" 1 "TRUE" ;
VAL_ 1925 Aux2AmbtColrCtlCstAvlFlg18 0 "FALSE" 1 "TRUE" ;
VAL_ 1925 Aux2AmbtColrCtlCstAvlFlg17 0 "FALSE" 1 "TRUE" ;
VAL_ 1925 Aux2AmbtColrCtlCstAvlFlg16 0 "FALSE" 1 "TRUE" ;
VAL_ 1925 Aux2AmbtColrCtlCstAvlFlg15 0 "FALSE" 1 "TRUE" ;
VAL_ 1925 Aux2AmbtColrCtlCstAvlFlg14 0 "FALSE" 1 "TRUE" ;
VAL_ 1925 Aux2AmbtColrCtlCstAvlFlg28 0 "FALSE" 1 "TRUE" ;
VAL_ 1925 Aux2AmbtColrCtlCstAvlFlg27 0 "FALSE" 1 "TRUE" ;
VAL_ 1925 Aux2AmbtColrCtlCstAvlFlg26 0 "FALSE" 1 "TRUE" ;
VAL_ 1925 Aux2AmbtColrCtlCstAvlFlg25 0 "FALSE" 1 "TRUE" ;
VAL_ 1925 Aux2AmbtColrCtlCstAvlFlg24 0 "FALSE" 1 "TRUE" ;
VAL_ 1925 Aux2AmbtColrCtlCstAvlFlg23 0 "FALSE" 1 "TRUE" ;
VAL_ 1925 Aux2AmbtColrCtlCstAvlFlg22 0 "FALSE" 1 "TRUE" ;
VAL_ 1925 Aux2AmbtColrCtlCstAvlFlg21 0 "FALSE" 1 "TRUE" ;
VAL_ 1925 Aux2AmbtColrCtlCstAvlFlg35 0 "FALSE" 1 "TRUE" ;
VAL_ 1925 Aux2AmbtColrCtlCstAvlFlg34 0 "FALSE" 1 "TRUE" ;
VAL_ 1925 Aux2AmbtColrCtlCstAvlFlg33 0 "FALSE" 1 "TRUE" ;
VAL_ 1925 Aux2AmbtColrCtlCstAvlFlg32 0 "FALSE" 1 "TRUE" ;
VAL_ 1925 Aux2AmbtColrCtlCstAvlFlg31 0 "FALSE" 1 "TRUE" ;
VAL_ 1925 Aux2AmbtColrCtlCstAvlFlg30 0 "FALSE" 1 "TRUE" ;
VAL_ 1925 Aux2AmbtColrCtlCstAvlFlg3 0 "FALSE" 1 "TRUE" ;
VAL_ 1925 Aux2AmbtColrCtlCstAvlFlg29 0 "FALSE" 1 "TRUE" ;
VAL_ 1925 Aux2AmbtColrCtlCstAvlFlg42 0 "FALSE" 1 "TRUE" ;
VAL_ 1925 Aux2AmbtColrCtlCstAvlFlg41 0 "FALSE" 1 "TRUE" ;
VAL_ 1925 Aux2AmbtColrCtlCstAvlFlg40 0 "FALSE" 1 "TRUE" ;
VAL_ 1925 Aux2AmbtColrCtlCstAvlFlg4 0 "FALSE" 1 "TRUE" ;
VAL_ 1925 Aux2AmbtColrCtlCstAvlFlg39 0 "FALSE" 1 "TRUE" ;
VAL_ 1925 Aux2AmbtColrCtlCstAvlFlg38 0 "FALSE" 1 "TRUE" ;
VAL_ 1925 Aux2AmbtColrCtlCstAvlFlg37 0 "FALSE" 1 "TRUE" ;
VAL_ 1925 Aux2AmbtColrCtlCstAvlFlg36 0 "FALSE" 1 "TRUE" ;
VAL_ 1926 Aux2AmbtColrCtlCstAvlFlg5 0 "FALSE" 1 "TRUE" ;
VAL_ 1926 Aux2AmbtColrCtlCstAvlFlg49 0 "FALSE" 1 "TRUE" ;
VAL_ 1926 Aux2AmbtColrCtlCstAvlFlg48 0 "FALSE" 1 "TRUE" ;
VAL_ 1926 Aux2AmbtColrCtlCstAvlFlg47 0 "FALSE" 1 "TRUE" ;
VAL_ 1926 Aux2AmbtColrCtlCstAvlFlg46 0 "FALSE" 1 "TRUE" ;
VAL_ 1926 Aux2AmbtColrCtlCstAvlFlg45 0 "FALSE" 1 "TRUE" ;
VAL_ 1926 Aux2AmbtColrCtlCstAvlFlg44 0 "FALSE" 1 "TRUE" ;
VAL_ 1926 Aux2AmbtColrCtlCstAvlFlg43 0 "FALSE" 1 "TRUE" ;
VAL_ 1926 Aux2AmbtColrCtlCstAvlFlg57 0 "FALSE" 1 "TRUE" ;
VAL_ 1926 Aux2AmbtColrCtlCstAvlFlg56 0 "FALSE" 1 "TRUE" ;
VAL_ 1926 Aux2AmbtColrCtlCstAvlFlg55 0 "FALSE" 1 "TRUE" ;
VAL_ 1926 Aux2AmbtColrCtlCstAvlFlg54 0 "FALSE" 1 "TRUE" ;
VAL_ 1926 Aux2AmbtColrCtlCstAvlFlg53 0 "FALSE" 1 "TRUE" ;
VAL_ 1926 Aux2AmbtColrCtlCstAvlFlg52 0 "FALSE" 1 "TRUE" ;
VAL_ 1926 Aux2AmbtColrCtlCstAvlFlg51 0 "FALSE" 1 "TRUE" ;
VAL_ 1926 Aux2AmbtColrCtlCstAvlFlg50 0 "FALSE" 1 "TRUE" ;
VAL_ 1926 Aux2AmbtColrCtlCstAvlFlg64 0 "FALSE" 1 "TRUE" ;
VAL_ 1926 Aux2AmbtColrCtlCstAvlFlg63 0 "FALSE" 1 "TRUE" ;
VAL_ 1926 Aux2AmbtColrCtlCstAvlFlg62 0 "FALSE" 1 "TRUE" ;
VAL_ 1926 Aux2AmbtColrCtlCstAvlFlg61 0 "FALSE" 1 "TRUE" ;
VAL_ 1926 Aux2AmbtColrCtlCstAvlFlg60 0 "FALSE" 1 "TRUE" ;
VAL_ 1926 Aux2AmbtColrCtlCstAvlFlg6 0 "FALSE" 1 "TRUE" ;
VAL_ 1926 Aux2AmbtColrCtlCstAvlFlg59 0 "FALSE" 1 "TRUE" ;
VAL_ 1926 Aux2AmbtColrCtlCstAvlFlg58 0 "FALSE" 1 "TRUE" ;
VAL_ 1926 Aux2AmbtColrCtlCstAvlFlg71 0 "FALSE" 1 "TRUE" ;
VAL_ 1926 Aux2AmbtColrCtlCstAvlFlg70 0 "FALSE" 1 "TRUE" ;
VAL_ 1926 Aux2AmbtColrCtlCstAvlFlg7 0 "FALSE" 1 "TRUE" ;
VAL_ 1926 Aux2AmbtColrCtlCstAvlFlg69 0 "FALSE" 1 "TRUE" ;
VAL_ 1926 Aux2AmbtColrCtlCstAvlFlg68 0 "FALSE" 1 "TRUE" ;
VAL_ 1926 Aux2AmbtColrCtlCstAvlFlg67 0 "FALSE" 1 "TRUE" ;
VAL_ 1926 Aux2AmbtColrCtlCstAvlFlg66 0 "FALSE" 1 "TRUE" ;
VAL_ 1926 Aux2AmbtColrCtlCstAvlFlg65 0 "FALSE" 1 "TRUE" ;
VAL_ 1926 Aux2AmbtColrCtlCstAvlFlg79 0 "FALSE" 1 "TRUE" ;
VAL_ 1926 Aux2AmbtColrCtlCstAvlFlg78 0 "FALSE" 1 "TRUE" ;
VAL_ 1926 Aux2AmbtColrCtlCstAvlFlg77 0 "FALSE" 1 "TRUE" ;
VAL_ 1926 Aux2AmbtColrCtlCstAvlFlg76 0 "FALSE" 1 "TRUE" ;
VAL_ 1926 Aux2AmbtColrCtlCstAvlFlg75 0 "FALSE" 1 "TRUE" ;
VAL_ 1926 Aux2AmbtColrCtlCstAvlFlg74 0 "FALSE" 1 "TRUE" ;
VAL_ 1926 Aux2AmbtColrCtlCstAvlFlg73 0 "FALSE" 1 "TRUE" ;
VAL_ 1926 Aux2AmbtColrCtlCstAvlFlg72 0 "FALSE" 1 "TRUE" ;
VAL_ 1926 Aux2AmbtColrCtlCstAvlFlg86 0 "FALSE" 1 "TRUE" ;
VAL_ 1926 Aux2AmbtColrCtlCstAvlFlg85 0 "FALSE" 1 "TRUE" ;
VAL_ 1926 Aux2AmbtColrCtlCstAvlFlg84 0 "FALSE" 1 "TRUE" ;
VAL_ 1926 Aux2AmbtColrCtlCstAvlFlg83 0 "FALSE" 1 "TRUE" ;
VAL_ 1926 Aux2AmbtColrCtlCstAvlFlg82 0 "FALSE" 1 "TRUE" ;
VAL_ 1926 Aux2AmbtColrCtlCstAvlFlg81 0 "FALSE" 1 "TRUE" ;
VAL_ 1926 Aux2AmbtColrCtlCstAvlFlg80 0 "FALSE" 1 "TRUE" ;
VAL_ 1926 Aux2AmbtColrCtlCstAvlFlg8 0 "FALSE" 1 "TRUE" ;
VAL_ 1926 Aux2AmbtColrCtlCstAvlFlg93 0 "FALSE" 1 "TRUE" ;
VAL_ 1926 Aux2AmbtColrCtlCstAvlFlg92 0 "FALSE" 1 "TRUE" ;
VAL_ 1926 Aux2AmbtColrCtlCstAvlFlg91 0 "FALSE" 1 "TRUE" ;
VAL_ 1926 Aux2AmbtColrCtlCstAvlFlg90 0 "FALSE" 1 "TRUE" ;
VAL_ 1926 Aux2AmbtColrCtlCstAvlFlg9 0 "FALSE" 1 "TRUE" ;
VAL_ 1926 Aux2AmbtColrCtlCstAvlFlg89 0 "FALSE" 1 "TRUE" ;
VAL_ 1926 Aux2AmbtColrCtlCstAvlFlg88 0 "FALSE" 1 "TRUE" ;
VAL_ 1926 Aux2AmbtColrCtlCstAvlFlg87 0 "FALSE" 1 "TRUE" ;
VAL_ 1926 Aux3AmbtAnmCtlCstAvlFlg1 0 "FALSE" 1 "TRUE" ;
VAL_ 1926 Aux2AmbtColrCtlCstSetAval 0 "FALSE" 1 "TRUE" ;
VAL_ 1926 Aux2AmbtColrCtlCstAvlFlg99 0 "FALSE" 1 "TRUE" ;
VAL_ 1926 Aux2AmbtColrCtlCstAvlFlg98 0 "FALSE" 1 "TRUE" ;
VAL_ 1926 Aux2AmbtColrCtlCstAvlFlg97 0 "FALSE" 1 "TRUE" ;
VAL_ 1926 Aux2AmbtColrCtlCstAvlFlg96 0 "FALSE" 1 "TRUE" ;
VAL_ 1926 Aux2AmbtColrCtlCstAvlFlg95 0 "FALSE" 1 "TRUE" ;
VAL_ 1926 Aux2AmbtColrCtlCstAvlFlg94 0 "FALSE" 1 "TRUE" ;
VAL_ 1132 Aux3AmbtAnmCtlCstAvlFlg3 0 "FALSE" 1 "TRUE" ;
VAL_ 1132 Aux3AmbtAnmCtlCstAvlFlg2 0 "FALSE" 1 "TRUE" ;
VAL_ 1132 Aux3AmbtAnmCtlCstAvlFlg15 0 "FALSE" 1 "TRUE" ;
VAL_ 1132 Aux3AmbtAnmCtlCstAvlFlg14 0 "FALSE" 1 "TRUE" ;
VAL_ 1132 Aux3AmbtAnmCtlCstAvlFlg13 0 "FALSE" 1 "TRUE" ;
VAL_ 1132 Aux3AmbtAnmCtlCstAvlFlg12 0 "FALSE" 1 "TRUE" ;
VAL_ 1132 Aux3AmbtAnmCtlCstAvlFlg11 0 "FALSE" 1 "TRUE" ;
VAL_ 1132 Aux3AmbtAnmCtlCstAvlFlg10 0 "FALSE" 1 "TRUE" ;
VAL_ 1132 Aux3AmbtBrghtnsCtlCstAvlFlg1 0 "FALSE" 1 "TRUE" ;
VAL_ 1132 Aux3AmbtAnmCtlCstSetAval 0 "FALSE" 1 "TRUE" ;
VAL_ 1132 Aux3AmbtAnmCtlCstAvlFlg9 0 "FALSE" 1 "TRUE" ;
VAL_ 1132 Aux3AmbtAnmCtlCstAvlFlg8 0 "FALSE" 1 "TRUE" ;
VAL_ 1132 Aux3AmbtAnmCtlCstAvlFlg7 0 "FALSE" 1 "TRUE" ;
VAL_ 1132 Aux3AmbtAnmCtlCstAvlFlg6 0 "FALSE" 1 "TRUE" ;
VAL_ 1132 Aux3AmbtAnmCtlCstAvlFlg5 0 "FALSE" 1 "TRUE" ;
VAL_ 1132 Aux3AmbtAnmCtlCstAvlFlg4 0 "FALSE" 1 "TRUE" ;
VAL_ 1132 Aux3AmbtColrCtlCstAvlFlg1 0 "FALSE" 1 "TRUE" ;
VAL_ 1132 Aux3AmbtBrghtnsCtlCstSetAval 0 "FALSE" 1 "TRUE" ;
VAL_ 1132 Aux3AmbtBrghtnsCtlCstAvlFlg7 0 "FALSE" 1 "TRUE" ;
VAL_ 1132 Aux3AmbtBrghtnsCtlCstAvlFlg6 0 "FALSE" 1 "TRUE" ;
VAL_ 1132 Aux3AmbtBrghtnsCtlCstAvlFlg5 0 "FALSE" 1 "TRUE" ;
VAL_ 1132 Aux3AmbtBrghtnsCtlCstAvlFlg4 0 "FALSE" 1 "TRUE" ;
VAL_ 1132 Aux3AmbtBrghtnsCtlCstAvlFlg3 0 "FALSE" 1 "TRUE" ;
VAL_ 1132 Aux3AmbtBrghtnsCtlCstAvlFlg2 0 "FALSE" 1 "TRUE" ;
VAL_ 1132 Aux3AmbtColrCtlCstAvlFlg106 0 "FALSE" 1 "TRUE" ;
VAL_ 1132 Aux3AmbtColrCtlCstAvlFlg105 0 "FALSE" 1 "TRUE" ;
VAL_ 1132 Aux3AmbtColrCtlCstAvlFlg104 0 "FALSE" 1 "TRUE" ;
VAL_ 1132 Aux3AmbtColrCtlCstAvlFlg103 0 "FALSE" 1 "TRUE" ;
VAL_ 1132 Aux3AmbtColrCtlCstAvlFlg102 0 "FALSE" 1 "TRUE" ;
VAL_ 1132 Aux3AmbtColrCtlCstAvlFlg101 0 "FALSE" 1 "TRUE" ;
VAL_ 1132 Aux3AmbtColrCtlCstAvlFlg100 0 "FALSE" 1 "TRUE" ;
VAL_ 1132 Aux3AmbtColrCtlCstAvlFlg10 0 "FALSE" 1 "TRUE" ;
VAL_ 1132 Aux3AmbtColrCtlCstAvlFlg113 0 "FALSE" 1 "TRUE" ;
VAL_ 1132 Aux3AmbtColrCtlCstAvlFlg112 0 "FALSE" 1 "TRUE" ;
VAL_ 1132 Aux3AmbtColrCtlCstAvlFlg111 0 "FALSE" 1 "TRUE" ;
VAL_ 1132 Aux3AmbtColrCtlCstAvlFlg110 0 "FALSE" 1 "TRUE" ;
VAL_ 1132 Aux3AmbtColrCtlCstAvlFlg11 0 "FALSE" 1 "TRUE" ;
VAL_ 1132 Aux3AmbtColrCtlCstAvlFlg109 0 "FALSE" 1 "TRUE" ;
VAL_ 1132 Aux3AmbtColrCtlCstAvlFlg108 0 "FALSE" 1 "TRUE" ;
VAL_ 1132 Aux3AmbtColrCtlCstAvlFlg107 0 "FALSE" 1 "TRUE" ;
VAL_ 1132 Aux3AmbtColrCtlCstAvlFlg120 0 "FALSE" 1 "TRUE" ;
VAL_ 1132 Aux3AmbtColrCtlCstAvlFlg12 0 "FALSE" 1 "TRUE" ;
VAL_ 1132 Aux3AmbtColrCtlCstAvlFlg119 0 "FALSE" 1 "TRUE" ;
VAL_ 1132 Aux3AmbtColrCtlCstAvlFlg118 0 "FALSE" 1 "TRUE" ;
VAL_ 1132 Aux3AmbtColrCtlCstAvlFlg117 0 "FALSE" 1 "TRUE" ;
VAL_ 1132 Aux3AmbtColrCtlCstAvlFlg116 0 "FALSE" 1 "TRUE" ;
VAL_ 1132 Aux3AmbtColrCtlCstAvlFlg115 0 "FALSE" 1 "TRUE" ;
VAL_ 1132 Aux3AmbtColrCtlCstAvlFlg114 0 "FALSE" 1 "TRUE" ;
VAL_ 1132 Aux3AmbtColrCtlCstAvlFlg13 0 "FALSE" 1 "TRUE" ;
VAL_ 1132 Aux3AmbtColrCtlCstAvlFlg127 0 "FALSE" 1 "TRUE" ;
VAL_ 1132 Aux3AmbtColrCtlCstAvlFlg126 0 "FALSE" 1 "TRUE" ;
VAL_ 1132 Aux3AmbtColrCtlCstAvlFlg125 0 "FALSE" 1 "TRUE" ;
VAL_ 1132 Aux3AmbtColrCtlCstAvlFlg124 0 "FALSE" 1 "TRUE" ;
VAL_ 1132 Aux3AmbtColrCtlCstAvlFlg123 0 "FALSE" 1 "TRUE" ;
VAL_ 1132 Aux3AmbtColrCtlCstAvlFlg122 0 "FALSE" 1 "TRUE" ;
VAL_ 1132 Aux3AmbtColrCtlCstAvlFlg121 0 "FALSE" 1 "TRUE" ;
VAL_ 1132 Aux3AmbtColrCtlCstAvlFlg20 0 "FALSE" 1 "TRUE" ;
VAL_ 1132 Aux3AmbtColrCtlCstAvlFlg2 0 "FALSE" 1 "TRUE" ;
VAL_ 1132 Aux3AmbtColrCtlCstAvlFlg19 0 "FALSE" 1 "TRUE" ;
VAL_ 1132 Aux3AmbtColrCtlCstAvlFlg18 0 "FALSE" 1 "TRUE" ;
VAL_ 1132 Aux3AmbtColrCtlCstAvlFlg17 0 "FALSE" 1 "TRUE" ;
VAL_ 1132 Aux3AmbtColrCtlCstAvlFlg16 0 "FALSE" 1 "TRUE" ;
VAL_ 1132 Aux3AmbtColrCtlCstAvlFlg15 0 "FALSE" 1 "TRUE" ;
VAL_ 1132 Aux3AmbtColrCtlCstAvlFlg14 0 "FALSE" 1 "TRUE" ;
VAL_ 1935 Aux3AmbtColrCtlCstAvlFlg28 0 "FALSE" 1 "TRUE" ;
VAL_ 1935 Aux3AmbtColrCtlCstAvlFlg27 0 "FALSE" 1 "TRUE" ;
VAL_ 1935 Aux3AmbtColrCtlCstAvlFlg26 0 "FALSE" 1 "TRUE" ;
VAL_ 1935 Aux3AmbtColrCtlCstAvlFlg25 0 "FALSE" 1 "TRUE" ;
VAL_ 1935 Aux3AmbtColrCtlCstAvlFlg24 0 "FALSE" 1 "TRUE" ;
VAL_ 1935 Aux3AmbtColrCtlCstAvlFlg23 0 "FALSE" 1 "TRUE" ;
VAL_ 1935 Aux3AmbtColrCtlCstAvlFlg22 0 "FALSE" 1 "TRUE" ;
VAL_ 1935 Aux3AmbtColrCtlCstAvlFlg21 0 "FALSE" 1 "TRUE" ;
VAL_ 1935 Aux3AmbtColrCtlCstAvlFlg35 0 "FALSE" 1 "TRUE" ;
VAL_ 1935 Aux3AmbtColrCtlCstAvlFlg34 0 "FALSE" 1 "TRUE" ;
VAL_ 1935 Aux3AmbtColrCtlCstAvlFlg33 0 "FALSE" 1 "TRUE" ;
VAL_ 1935 Aux3AmbtColrCtlCstAvlFlg32 0 "FALSE" 1 "TRUE" ;
VAL_ 1935 Aux3AmbtColrCtlCstAvlFlg31 0 "FALSE" 1 "TRUE" ;
VAL_ 1935 Aux3AmbtColrCtlCstAvlFlg30 0 "FALSE" 1 "TRUE" ;
VAL_ 1935 Aux3AmbtColrCtlCstAvlFlg3 0 "FALSE" 1 "TRUE" ;
VAL_ 1935 Aux3AmbtColrCtlCstAvlFlg29 0 "FALSE" 1 "TRUE" ;
VAL_ 1935 Aux3AmbtColrCtlCstAvlFlg42 0 "FALSE" 1 "TRUE" ;
VAL_ 1935 Aux3AmbtColrCtlCstAvlFlg41 0 "FALSE" 1 "TRUE" ;
VAL_ 1935 Aux3AmbtColrCtlCstAvlFlg40 0 "FALSE" 1 "TRUE" ;
VAL_ 1935 Aux3AmbtColrCtlCstAvlFlg4 0 "FALSE" 1 "TRUE" ;
VAL_ 1935 Aux3AmbtColrCtlCstAvlFlg39 0 "FALSE" 1 "TRUE" ;
VAL_ 1935 Aux3AmbtColrCtlCstAvlFlg38 0 "FALSE" 1 "TRUE" ;
VAL_ 1935 Aux3AmbtColrCtlCstAvlFlg37 0 "FALSE" 1 "TRUE" ;
VAL_ 1935 Aux3AmbtColrCtlCstAvlFlg36 0 "FALSE" 1 "TRUE" ;
VAL_ 1935 Aux3AmbtColrCtlCstAvlFlg5 0 "FALSE" 1 "TRUE" ;
VAL_ 1935 Aux3AmbtColrCtlCstAvlFlg49 0 "FALSE" 1 "TRUE" ;
VAL_ 1935 Aux3AmbtColrCtlCstAvlFlg48 0 "FALSE" 1 "TRUE" ;
VAL_ 1935 Aux3AmbtColrCtlCstAvlFlg47 0 "FALSE" 1 "TRUE" ;
VAL_ 1935 Aux3AmbtColrCtlCstAvlFlg46 0 "FALSE" 1 "TRUE" ;
VAL_ 1935 Aux3AmbtColrCtlCstAvlFlg45 0 "FALSE" 1 "TRUE" ;
VAL_ 1935 Aux3AmbtColrCtlCstAvlFlg44 0 "FALSE" 1 "TRUE" ;
VAL_ 1935 Aux3AmbtColrCtlCstAvlFlg43 0 "FALSE" 1 "TRUE" ;
VAL_ 1935 Aux3AmbtColrCtlCstAvlFlg57 0 "FALSE" 1 "TRUE" ;
VAL_ 1935 Aux3AmbtColrCtlCstAvlFlg56 0 "FALSE" 1 "TRUE" ;
VAL_ 1935 Aux3AmbtColrCtlCstAvlFlg55 0 "FALSE" 1 "TRUE" ;
VAL_ 1935 Aux3AmbtColrCtlCstAvlFlg54 0 "FALSE" 1 "TRUE" ;
VAL_ 1935 Aux3AmbtColrCtlCstAvlFlg53 0 "FALSE" 1 "TRUE" ;
VAL_ 1935 Aux3AmbtColrCtlCstAvlFlg52 0 "FALSE" 1 "TRUE" ;
VAL_ 1935 Aux3AmbtColrCtlCstAvlFlg51 0 "FALSE" 1 "TRUE" ;
VAL_ 1935 Aux3AmbtColrCtlCstAvlFlg50 0 "FALSE" 1 "TRUE" ;
VAL_ 1935 Aux3AmbtColrCtlCstAvlFlg64 0 "FALSE" 1 "TRUE" ;
VAL_ 1935 Aux3AmbtColrCtlCstAvlFlg63 0 "FALSE" 1 "TRUE" ;
VAL_ 1935 Aux3AmbtColrCtlCstAvlFlg62 0 "FALSE" 1 "TRUE" ;
VAL_ 1935 Aux3AmbtColrCtlCstAvlFlg61 0 "FALSE" 1 "TRUE" ;
VAL_ 1935 Aux3AmbtColrCtlCstAvlFlg60 0 "FALSE" 1 "TRUE" ;
VAL_ 1935 Aux3AmbtColrCtlCstAvlFlg6 0 "FALSE" 1 "TRUE" ;
VAL_ 1935 Aux3AmbtColrCtlCstAvlFlg59 0 "FALSE" 1 "TRUE" ;
VAL_ 1935 Aux3AmbtColrCtlCstAvlFlg58 0 "FALSE" 1 "TRUE" ;
VAL_ 1935 Aux3AmbtColrCtlCstAvlFlg71 0 "FALSE" 1 "TRUE" ;
VAL_ 1935 Aux3AmbtColrCtlCstAvlFlg70 0 "FALSE" 1 "TRUE" ;
VAL_ 1935 Aux3AmbtColrCtlCstAvlFlg7 0 "FALSE" 1 "TRUE" ;
VAL_ 1935 Aux3AmbtColrCtlCstAvlFlg69 0 "FALSE" 1 "TRUE" ;
VAL_ 1935 Aux3AmbtColrCtlCstAvlFlg68 0 "FALSE" 1 "TRUE" ;
VAL_ 1935 Aux3AmbtColrCtlCstAvlFlg67 0 "FALSE" 1 "TRUE" ;
VAL_ 1935 Aux3AmbtColrCtlCstAvlFlg66 0 "FALSE" 1 "TRUE" ;
VAL_ 1935 Aux3AmbtColrCtlCstAvlFlg65 0 "FALSE" 1 "TRUE" ;
VAL_ 1935 Aux3AmbtColrCtlCstAvlFlg79 0 "FALSE" 1 "TRUE" ;
VAL_ 1935 Aux3AmbtColrCtlCstAvlFlg78 0 "FALSE" 1 "TRUE" ;
VAL_ 1935 Aux3AmbtColrCtlCstAvlFlg77 0 "FALSE" 1 "TRUE" ;
VAL_ 1935 Aux3AmbtColrCtlCstAvlFlg76 0 "FALSE" 1 "TRUE" ;
VAL_ 1935 Aux3AmbtColrCtlCstAvlFlg75 0 "FALSE" 1 "TRUE" ;
VAL_ 1935 Aux3AmbtColrCtlCstAvlFlg74 0 "FALSE" 1 "TRUE" ;
VAL_ 1935 Aux3AmbtColrCtlCstAvlFlg73 0 "FALSE" 1 "TRUE" ;
VAL_ 1935 Aux3AmbtColrCtlCstAvlFlg72 0 "FALSE" 1 "TRUE" ;
VAL_ 1952 DMCabLgtPrkCstCurrSetVal 0 "Setting Unknown" 1 "Off" 2 "On" ;
VAL_ 1952 DMBlkhdDrUnltchPrkCstCurrSetVal 0 "Setting Unknown" 1 "Off" 2 "On" ;
VAL_ 1952 DMBlkhdDrUnlckPrkCstCurrSetVal 0 "Setting Unknown" 1 "Off" 2 "On" ;
VAL_ 1952 DMHrnOutPrkCstCurrSetVal 0 "Setting Unknown" 1 "Off" 2 "On" ;
VAL_ 1952 DMDrvrDrUnlckPrkCstCurrSetVal 0 "Setting Unknown" 1 "Off" 2 "On" ;
VAL_ 1952 DMCrbsdDrUnlckPrkCstCurrSetVal 0 "Setting Unknown" 1 "Off" 2 "On" ;
VAL_ 1952 DMBlkhdDrUnlckPrkCstAvlFlg6 0 "FALSE" 1 "TRUE" ;
VAL_ 1952 DMBlkhdDrUnlckPrkCstAvlFlg5 0 "FALSE" 1 "TRUE" ;
VAL_ 1952 DMBlkhdDrUnlckPrkCstAvlFlg4 0 "FALSE" 1 "TRUE" ;
VAL_ 1952 DMBlkhdDrUnlckPrkCstAvlFlg3 0 "FALSE" 1 "TRUE" ;
VAL_ 1952 DMBlkhdDrUnlckPrkCstAvlFlg2 0 "FALSE" 1 "TRUE" ;
VAL_ 1952 DMBlkhdDrUnlckPrkCstAvlFlg1 0 "FALSE" 1 "TRUE" ;
VAL_ 1952 DMBlkhdDrUnltchPrkCstAvlFlg6 0 "FALSE" 1 "TRUE" ;
VAL_ 1952 DMBlkhdDrUnltchPrkCstAvlFlg5 0 "FALSE" 1 "TRUE" ;
VAL_ 1952 DMBlkhdDrUnltchPrkCstAvlFlg4 0 "FALSE" 1 "TRUE" ;
VAL_ 1952 DMBlkhdDrUnltchPrkCstAvlFlg3 0 "FALSE" 1 "TRUE" ;
VAL_ 1952 DMBlkhdDrUnltchPrkCstAvlFlg2 0 "FALSE" 1 "TRUE" ;
VAL_ 1952 DMBlkhdDrUnltchPrkCstAvlFlg1 0 "FALSE" 1 "TRUE" ;
VAL_ 1952 DMBlkhdDrUnlckPrkCstSetAval 0 "FALSE" 1 "TRUE" ;
VAL_ 1952 DMBlkhdDrUnlckPrkCstAvlFlg7 0 "FALSE" 1 "TRUE" ;
VAL_ 1952 DMCabLgtPrkCstAvlFlg6 0 "FALSE" 1 "TRUE" ;
VAL_ 1952 DMCabLgtPrkCstAvlFlg5 0 "FALSE" 1 "TRUE" ;
VAL_ 1952 DMCabLgtPrkCstAvlFlg4 0 "FALSE" 1 "TRUE" ;
VAL_ 1952 DMCabLgtPrkCstAvlFlg3 0 "FALSE" 1 "TRUE" ;
VAL_ 1952 DMCabLgtPrkCstAvlFlg2 0 "FALSE" 1 "TRUE" ;
VAL_ 1952 DMCabLgtPrkCstAvlFlg1 0 "FALSE" 1 "TRUE" ;
VAL_ 1952 DMBlkhdDrUnltchPrkCstSetAval 0 "FALSE" 1 "TRUE" ;
VAL_ 1952 DMBlkhdDrUnltchPrkCstAvlFlg7 0 "FALSE" 1 "TRUE" ;
VAL_ 1952 DMCrbsdDrUnlckPrkCstAvlFlg6 0 "FALSE" 1 "TRUE" ;
VAL_ 1952 DMCrbsdDrUnlckPrkCstAvlFlg5 0 "FALSE" 1 "TRUE" ;
VAL_ 1952 DMCrbsdDrUnlckPrkCstAvlFlg4 0 "FALSE" 1 "TRUE" ;
VAL_ 1952 DMCrbsdDrUnlckPrkCstAvlFlg3 0 "FALSE" 1 "TRUE" ;
VAL_ 1952 DMCrbsdDrUnlckPrkCstAvlFlg2 0 "FALSE" 1 "TRUE" ;
VAL_ 1952 DMCrbsdDrUnlckPrkCstAvlFlg1 0 "FALSE" 1 "TRUE" ;
VAL_ 1952 DMCabLgtPrkCstSetAval 0 "FALSE" 1 "TRUE" ;
VAL_ 1952 DMCabLgtPrkCstAvlFlg7 0 "FALSE" 1 "TRUE" ;
VAL_ 1952 DMDrvrDrUnlckPrkCstAvlFlg6 0 "FALSE" 1 "TRUE" ;
VAL_ 1952 DMDrvrDrUnlckPrkCstAvlFlg5 0 "FALSE" 1 "TRUE" ;
VAL_ 1952 DMDrvrDrUnlckPrkCstAvlFlg4 0 "FALSE" 1 "TRUE" ;
VAL_ 1952 DMDrvrDrUnlckPrkCstAvlFlg3 0 "FALSE" 1 "TRUE" ;
VAL_ 1952 DMDrvrDrUnlckPrkCstAvlFlg2 0 "FALSE" 1 "TRUE" ;
VAL_ 1952 DMDrvrDrUnlckPrkCstAvlFlg1 0 "FALSE" 1 "TRUE" ;
VAL_ 1952 DMCrbsdDrUnlckPrkCstSetAval 0 "FALSE" 1 "TRUE" ;
VAL_ 1952 DMCrbsdDrUnlckPrkCstAvlFlg7 0 "FALSE" 1 "TRUE" ;
VAL_ 1952 DMHrnOutPrkCstAvlFlg7 0 "FALSE" 1 "TRUE" ;
VAL_ 1952 DMHrnOutPrkCstAvlFlg6 0 "FALSE" 1 "TRUE" ;
VAL_ 1952 DMHrnOutPrkCstAvlFlg5 0 "FALSE" 1 "TRUE" ;
VAL_ 1952 DMHrnOutPrkCstAvlFlg4 0 "FALSE" 1 "TRUE" ;
VAL_ 1952 DMHrnOutPrkCstAvlFlg3 0 "FALSE" 1 "TRUE" ;
VAL_ 1952 DMHrnOutPrkCstAvlFlg2 0 "FALSE" 1 "TRUE" ;
VAL_ 1952 DMHrnOutPrkCstAvlFlg1 0 "FALSE" 1 "TRUE" ;
VAL_ 1952 DMDrvrDrUnlckPrkCstAvlFlg7 0 "FALSE" 1 "TRUE" ;
VAL_ 1977 IndAirDstThrdRw 0 "Off" 1 "Auto" 2 "Floor" 3 "Floor And Vent" 4 "Vent" 5 "Vent And Roof" 6 "Roof" 7 "Roof And Floor" 8 "Floor And Vent And Roof" ;
VAL_ 1977 IndTempSetStatThrdRw 0 "Off" 1 "Auto" 2 "Auto Lo" 3 "Auto Hi" 4 "Manual" ;
VAL_ 1977 IndBlwSetStatThrdRw 0 "Off" 1 "Auto" 2 "Manual" ;
VAL_ 1977 IndBlwSetStatRrRt 0 "Off" 1 "Auto" 2 "Manual" ;
VAL_ 1977 IndBlwSetStatFrtRt 0 "Off" 1 "Auto" 2 "Manual" ;
VAL_ 1977 IndNckScrfLvlRrRt 0 "Off" 1 "1" 2 "2" 3 "3" ;
VAL_ 1977 IndNckScrfLvlRrLt 0 "Off" 1 "1" 2 "2" 3 "3" ;
VAL_ 1977 IndNckScrfLvlFrtRt 0 "Off" 1 "1" 2 "2" 3 "3" ;
VAL_ 1977 IndNckScrfLvlFrtLt 0 "Off" 1 "1" 2 "2" 3 "3" ;
VAL_ 1977 IndOscModeRrRtSet 0 "Left Right Only" 1 "Up Down Only" 2 "Left Right Up Down" ;
VAL_ 1977 IndOscModeRrLtSet 0 "Left Right Only" 1 "Up Down Only" 2 "Left Right Up Down" ;
VAL_ 1977 IndOscModeFrtRtSet 0 "Left Right Only" 1 "Up Down Only" 2 "Left Right Up Down" ;
VAL_ 1977 IndOscModeFrtLtSet 0 "Left Right Only" 1 "Up Down Only" 2 "Left Right Up Down" ;
VAL_ 1977 IndThrdRwHVACOn 0 "FALSE" 1 "TRUE" ;
VAL_ 1977 IndThrdRwHVACLckd 0 "FALSE" 1 "TRUE" ;
VAL_ 1977 IndSyncThrdRw 0 "FALSE" 1 "TRUE" ;
VAL_ 1977 IndRrRtHVACOn 0 "FALSE" 1 "TRUE" ;
VAL_ 1977 IndRrLtHVACOn 0 "FALSE" 1 "TRUE" ;
VAL_ 1977 IndFrtRtHVACOn 0 "FALSE" 1 "TRUE" ;
VAL_ 1977 IndFrtLtHVACOn 0 "FALSE" 1 "TRUE" ;
VAL_ 1977 IndCkModeOn 0 "FALSE" 1 "TRUE" ;
VAL_ 1977 PwrShdBkGlsShdPs 0 "Unknown" 1 "Fully Down" 2 "Fully Up" 3 "Moving Down" 4 "Moving Up" 5 "Failed" ;
VAL_ 1977 HtdArmrstSyncCstSetAval 0 "FALSE" 1 "TRUE" ;
VAL_ 1977 HtdArmrstSyncCstCurrSetVal 0 "Setting Unknown" 1 "Off" 2 "On" ;
VAL_ 1977 ClmCtlThrdRwPwrLtdOpWrnReqActv 0 "FALSE" 1 "TRUE" ;
VAL_ 1977 IndZnUncpdRrSt 0 "FALSE" 1 "TRUE" ;
VAL_ 1977 IndZnUncpdFrtPsngr 0 "FALSE" 1 "TRUE" ;
VAL_ 1977 PwrShdDrShdRRPstn 0 "Unknown" 1 "Fully Down" 2 "Fully Up" 3 "Moving Down" 4 "Moving Up" 5 "Failed" ;
VAL_ 1977 PwrShdDrShdLRPstn 0 "Unknown" 1 "Fully Down" 2 "Fully Up" 3 "Moving Down" 4 "Moving Up" 5 "Failed" ;
VAL_ 1089 TrlrTireLRInrPres_Inv 0 "FALSE" 1 "TRUE" ;
VAL_ 1089 TrlrTireLtMdlInrPres_Inv 0 "FALSE" 1 "TRUE" ;
VAL_ 1089 TrlrTireRFInrPres_Inv 0 "FALSE" 1 "TRUE" ;
VAL_ 1089 TrlrTireRRInrPres_Inv 0 "FALSE" 1 "TRUE" ;
VAL_ 1089 TrlrTireRtMdlInrPres_Inv 0 "FALSE" 1 "TRUE" ;
VAL_ 1089 TrlrTireLFInrTemp_Inv 0 "FALSE" 1 "TRUE" ;
VAL_ 1089 TrlrTireLFInrTempSts_Inv 0 "FALSE" 1 "TRUE" ;
VAL_ 1089 TrlrTireLFInrTempSts 0 "Unknown" 1 "Normal" 2 "High Temperature" ;
VAL_ 1089 TrlrTireLRInrTemp_Inv 0 "FALSE" 1 "TRUE" ;
VAL_ 1978 TrlrTireLtMdlInrTemp_Inv 0 "FALSE" 1 "TRUE" ;
VAL_ 1978 TrlrTireRFInrTemp_Inv 0 "FALSE" 1 "TRUE" ;
VAL_ 1978 TrlrTireRRInrTemp_Inv 0 "FALSE" 1 "TRUE" ;
VAL_ 1978 TrlrTireRtMdlInrTemp_Inv 0 "FALSE" 1 "TRUE" ;
VAL_ 1978 TrlrTireLtMdlInrPresSts 0 "Unknown" 1 "Normal" 2 "Low Pressure" 3 "Malfunction" 4 "Learning in Progress" 5 "Learn Tire" 6 "Tire Learning Complete" 7 "High Pressure" 8 "High Temperature" ;
VAL_ 1978 TrlrTireLRInrPresSts_Inv 0 "FALSE" 1 "TRUE" ;
VAL_ 1978 TrlrTireLRInrPresSts 0 "Unknown" 1 "Normal" 2 "Low Pressure" 3 "Malfunction" 4 "Learning in Progress" 5 "Learn Tire" 6 "Tire Learning Complete" 7 "High Pressure" 8 "High Temperature" ;
VAL_ 1978 TrlrTireRRInrPresSts 0 "Unknown" 1 "Normal" 2 "Low Pressure" 3 "Malfunction" 4 "Learning in Progress" 5 "Learn Tire" 6 "Tire Learning Complete" 7 "High Pressure" 8 "High Temperature" ;
VAL_ 1978 TrlrTireRFInrPresSts_Inv 0 "FALSE" 1 "TRUE" ;
VAL_ 1978 TrlrTireRFInrPresSts 0 "Unknown" 1 "Normal" 2 "Low Pressure" 3 "Malfunction" 4 "Learning in Progress" 5 "Learn Tire" 6 "Tire Learning Complete" 7 "High Pressure" 8 "High Temperature" ;
VAL_ 1978 TrlrTireLtMdlInrPresSts_Inv 0 "FALSE" 1 "TRUE" ;
VAL_ 1978 TrlrTireRtMdlInrPresSts 0 "Unknown" 1 "Normal" 2 "Low Pressure" 3 "Malfunction" 4 "Learning in Progress" 5 "Learn Tire" 6 "Tire Learning Complete" 7 "High Pressure" 8 "High Temperature" ;
VAL_ 1978 TrlrTireRRInrPresSts_Inv 0 "FALSE" 1 "TRUE" ;
VAL_ 1978 TrlrTireLRInrTempSts_Inv 0 "FALSE" 1 "TRUE" ;
VAL_ 1978 TrlrTireLRInrTempSts 0 "Unknown" 1 "Normal" 2 "High Temperature" ;
VAL_ 1978 TrlrTireLFTempSts_Inv 0 "FALSE" 1 "TRUE" ;
VAL_ 1978 TrlrTireLFTempSts 0 "Unknown" 1 "Normal" 2 "High Temperature" ;
VAL_ 1978 TrlrTireRtMdlInrPresSts_Inv 0 "FALSE" 1 "TRUE" ;
VAL_ 1088 TrlrTireLtMdlTempSts 0 "Unknown" 1 "Normal" 2 "High Temperature" ;
VAL_ 1088 TrlrTireLtMdlInrTempSts_Inv 0 "FALSE" 1 "TRUE" ;
VAL_ 1088 TrlrTireLtMdlInrTempSts 0 "Unknown" 1 "Normal" 2 "High Temperature" ;
VAL_ 1088 TrlrTireLRTempSts_Inv 0 "FALSE" 1 "TRUE" ;
VAL_ 1088 TrlrTireLRTempSts 0 "Unknown" 1 "Normal" 2 "High Temperature" ;
VAL_ 1088 TrlrTireRRInrTempSts 0 "Unknown" 1 "Normal" 2 "High Temperature" ;
VAL_ 1088 TrlrTireRFTempSts_Inv 0 "FALSE" 1 "TRUE" ;
VAL_ 1088 TrlrTireRFTempSts 0 "Unknown" 1 "Normal" 2 "High Temperature" ;
VAL_ 1088 TrlrTireRFInrTempSts_Inv 0 "FALSE" 1 "TRUE" ;
VAL_ 1088 TrlrTireRFInrTempSts 0 "Unknown" 1 "Normal" 2 "High Temperature" ;
VAL_ 1088 TrlrTireLtMdlTempSts_Inv 0 "FALSE" 1 "TRUE" ;
VAL_ 1088 TrlrTireRtMdlInrTempSts_Inv 0 "FALSE" 1 "TRUE" ;
VAL_ 1088 TrlrTireRtMdlInrTempSts 0 "Unknown" 1 "Normal" 2 "High Temperature" ;
VAL_ 1088 TrlrTireRRTempSts_Inv 0 "FALSE" 1 "TRUE" ;
VAL_ 1088 TrlrTireRRTempSts 0 "Unknown" 1 "Normal" 2 "High Temperature" ;
VAL_ 1088 TrlrTireRRInrTempSts_Inv 0 "FALSE" 1 "TRUE" ;
VAL_ 1088 TrlrTireRtMdlTempSts_Inv 0 "FALSE" 1 "TRUE" ;
VAL_ 1088 TrlrTireRtMdlTempSts 0 "Unknown" 1 "Normal" 2 "High Temperature" ;
VAL_ 1088 StHtdRrNumLvlAval 0 "Not Available" 1 "Two Levels" 2 "Three Levels" 3 "Four Levels" ;
VAL_ 1088 StHtdFrtNumLvlAval 0 "Not Available" 1 "Two Levels" 2 "Three Levels" 3 "Four Levels" ;
VAL_ 1088 VarLgtTransGlsRfTntVirtCtlAval 0 "Not Available" 1 "Available" ;
VAL_ 1088 VirtCtlRrWndShdCtlAval 0 "Not Available" 1 "Available" ;
VAL_ 1088 VirtCtlPrvcySwAval 0 "Not Available" 1 "Available" ;
VAL_ 1088 VirtCtlBkGlsShdCtlAval 0 "Not Available" 1 "Available" ;
VAL_ 1088 StVntdCoolRrNumLvlAval 0 "Not Available" 1 "Two Levels" 2 "Three Levels" 3 "Four Levels" ;
VAL_ 1088 StVntdCoolFrtNumLvlAval 0 "Not Available" 1 "Two Levels" 2 "Three Levels" 3 "Four Levels" ;
VAL_ 738 VarLgtTransGlsRfTntLvlPnl3Set 0 "Dark" 1 "Clear Level 1" 2 "Clear Level 2" 3 "Clear Level 3" 4 "Clear Level 4" 5 "Clear Level 5" 6 "Clear Level 6" ;
VAL_ 738 VarLgtTransGlsRfTntLvlPnl2Set 0 "Dark" 1 "Clear Level 1" 2 "Clear Level 2" 3 "Clear Level 3" 4 "Clear Level 4" 5 "Clear Level 5" 6 "Clear Level 6" ;
VAL_ 738 VarLgtTransGlsRfTntLvlPnl1Set 0 "Dark" 1 "Clear Level 1" 2 "Clear Level 2" 3 "Clear Level 3" 4 "Clear Level 4" 5 "Clear Level 5" 6 "Clear Level 6" ;
VAL_ 738 VarLgtTransGlsRfTntLvlPnl6Set 0 "Dark" 1 "Clear Level 1" 2 "Clear Level 2" 3 "Clear Level 3" 4 "Clear Level 4" 5 "Clear Level 5" 6 "Clear Level 6" ;
VAL_ 738 VarLgtTransGlsRfTntLvlPnl5Set 0 "Dark" 1 "Clear Level 1" 2 "Clear Level 2" 3 "Clear Level 3" 4 "Clear Level 4" 5 "Clear Level 5" 6 "Clear Level 6" ;
VAL_ 738 VarLgtTransGlsRfTntLvlPnl4Set 0 "Dark" 1 "Clear Level 1" 2 "Clear Level 2" 3 "Clear Level 3" 4 "Clear Level 4" 5 "Clear Level 5" 6 "Clear Level 6" ;
VAL_ 738 VarLgtTransGlsRfTntLvlPnl8Set 0 "Dark" 1 "Clear Level 1" 2 "Clear Level 2" 3 "Clear Level 3" 4 "Clear Level 4" 5 "Clear Level 5" 6 "Clear Level 6" ;
VAL_ 738 VarLgtTransGlsRfTntLvlPnl7Set 0 "Dark" 1 "Clear Level 1" 2 "Clear Level 2" 3 "Clear Level 3" 4 "Clear Level 4" 5 "Clear Level 5" 6 "Clear Level 6" ;
VAL_ 738 MaxPwrModeLngPrssReq 0 "No Indication" 1 "Pending" 2 "Ready" ;
VAL_ 738 VarLgtTransGlsRfVirtCtlMenuReqd 0 "FALSE" 1 "TRUE" ;
VAL_ 738 VarLgtTransGlsRfTntVirtCtlAllwd 0 "FALSE" 1 "TRUE" ;
VAL_ 738 VarLgtTransGlsRfTntAutoSetActv 0 "FALSE" 1 "TRUE" ;
VAL_ 738 VarLgtTransGlsRfTntLvlSldrSet 0 "Clear Level 1" 1 "Clear Level 2" 2 "Clear Level 3" 3 "Clear Level 4" 4 "Clear Level 5" 5 "Clear Level 6" ;
VAL_ 738 TrlrTireLkDtnLFSts 0 "Unknown" 1 "No Leak" 2 "Slow Leak" 3 "Fast Leak" ;
VAL_ 738 TrlrTireLkDtnLFInrSts 0 "Unknown" 1 "No Leak" 2 "Slow Leak" 3 "Fast Leak" ;
VAL_ 738 TrlrTireLkDtnEnblSts 0 "Unknown" 1 "Enabled" 2 "Disabled" ;
VAL_ 738 RrClsrAccssVirtCtlAval 0 "Not Available" 1 "Available" ;
VAL_ 738 RrClsrAccssVirtCtlAllwd 0 "Not Allowed" 1 "Allowed" ;
VAL_ 738 TrlrTireLkDtnLtMdlSts 0 "Unknown" 1 "No Leak" 2 "Slow Leak" 3 "Fast Leak" ;
VAL_ 738 TrlrTireLkDtnLtMdlInrSts 0 "Unknown" 1 "No Leak" 2 "Slow Leak" 3 "Fast Leak" ;
VAL_ 738 TrlrTireLkDtnLRSts 0 "Unknown" 1 "No Leak" 2 "Slow Leak" 3 "Fast Leak" ;
VAL_ 738 TrlrTireLkDtnLRInrSts 0 "Unknown" 1 "No Leak" 2 "Slow Leak" 3 "Fast Leak" ;
VAL_ 738 TrlrTireLkDtnRRSts 0 "Unknown" 1 "No Leak" 2 "Slow Leak" 3 "Fast Leak" ;
VAL_ 738 TrlrTireLkDtnRRInrSts 0 "Unknown" 1 "No Leak" 2 "Slow Leak" 3 "Fast Leak" ;
VAL_ 738 TrlrTireLkDtnRFSts 0 "Unknown" 1 "No Leak" 2 "Slow Leak" 3 "Fast Leak" ;
VAL_ 738 TrlrTireLkDtnRFInrSts 0 "Unknown" 1 "No Leak" 2 "Slow Leak" 3 "Fast Leak" ;
VAL_ 738 VirtCtlRrWndShdCtlRrAllwd 0 "FALSE" 1 "TRUE" ;
VAL_ 738 VirtCtlRrWndShdCtlFrtAllwd 0 "FALSE" 1 "TRUE" ;
VAL_ 738 TrlrTireLkDtnWrstCsSts 0 "Unknown" 1 "No Leak" 2 "Slow Leak" 3 "Fast Leak" ;
VAL_ 738 TrlrTireLkDtnRtMdlSts 0 "Unknown" 1 "No Leak" 2 "Slow Leak" 3 "Fast Leak" ;
VAL_ 738 TrlrTireLkDtnRtMdlInrSts 0 "Unknown" 1 "No Leak" 2 "Slow Leak" 3 "Fast Leak" ;
VAL_ 1350 OccptLtBehindAlrmDlyDrvrResp 0 "No Action" 1 "Yes" 2 "No" ;
VAL_ 2004 OccptLtBehindRmndrCstAvlFlg4 0 "FALSE" 1 "TRUE" ;
VAL_ 2004 OccptLtBehindRmndrCstAvlFlg3 0 "FALSE" 1 "TRUE" ;
VAL_ 2004 OccptLtBehindRmndrCstAvlFlg2 0 "FALSE" 1 "TRUE" ;
VAL_ 2004 OccptLtBehindRmndrCstAvlFlg1 0 "FALSE" 1 "TRUE" ;
VAL_ 2004 IndMcrClmStSyncRrRt 0 "FALSE" 1 "TRUE" ;
VAL_ 2004 IndMcrClmStSyncRrLt 0 "FALSE" 1 "TRUE" ;
VAL_ 2004 IndMcrClmStSyncFrtRt 0 "FALSE" 1 "TRUE" ;
VAL_ 2004 IndMcrClmStSyncFrtLt 0 "FALSE" 1 "TRUE" ;
VAL_ 2004 OccptLtBehindRmndrCstSetAval 0 "FALSE" 1 "TRUE" ;
VAL_ 2004 OccptLtBehindRmndrCstAvlFlg7 0 "FALSE" 1 "TRUE" ;
VAL_ 2004 OccptLtBehindRmndrCstAvlFlg6 0 "FALSE" 1 "TRUE" ;
VAL_ 2004 OccptLtBehindRmndrCstAvlFlg5 0 "FALSE" 1 "TRUE" ;
VAL_ 2004 McrClmStSyncRrRtAval 0 "Not Available" 1 "Available" ;
VAL_ 2004 McrClmStSyncRrLtAval 0 "Not Available" 1 "Available" ;
VAL_ 2004 McrClmStSyncFrtRtAval 0 "Not Available" 1 "Available" ;
VAL_ 2004 McrClmStSyncFrtLtAval 0 "Not Available" 1 "Available" ;
VAL_ 1293 WhlCntrCapLgtRFCmd 0 "No Action" 1 "Off" 2 "On" ;
VAL_ 1293 WhlCntrCapLgtLRCmd 0 "No Action" 1 "Off" 2 "On" ;
VAL_ 1293 WhlCntrCapLgtLFCmd 0 "No Action" 1 "Off" 2 "On" ;
VAL_ 1293 WhlCntrCapLgtCommReqd 0 "FALSE" 1 "TRUE" ;
VAL_ 1293 OccptLtBehindFltIndOn 0 "FALSE" 1 "TRUE" ;
VAL_ 1293 WhlCntrCapLgtRRCmd 0 "No Action" 1 "Off" 2 "On" ;
VAL_ 1293 OccptLtBehindRrRmndrIndOn 0 "FALSE" 1 "TRUE" ;
VAL_ 1293 OccptLtBehindRmndrCstCurrSetVal 0 "Setting Unknown" 1 "Off" 2 "On" ;
VAL_ 1293 OccptLtBehindIndOn 0 "FALSE" 1 "TRUE" ;
VAL_ 1981 IndArflQntyFrtLtInbrdOtltSet 0 "0" 1 "25" 2 "50" 3 "75" 4 "100" ;
VAL_ 1981 IndAirDstEnblsVntArflRrRt 0 "FALSE" 1 "TRUE" ;
VAL_ 1981 IndAirDstEnblsVntArflRrLt 0 "FALSE" 1 "TRUE" ;
VAL_ 1981 IndAirDstEnblsVntArflFrtRt 0 "FALSE" 1 "TRUE" ;
VAL_ 1981 IndAirDstEnblsVntArflFrtLt 0 "FALSE" 1 "TRUE" ;
VAL_ 1981 HtdWprPrkDcrAvl 0 "Unknown" 1 "Unavailable" 2 "Available" ;
VAL_ 1981 IndArflQntyFrtRtOtbrdOtltSet 0 "0" 1 "25" 2 "50" 3 "75" 4 "100" ;
VAL_ 1981 IndArflQntyFrtRtInbrdOtltSet 0 "0" 1 "25" 2 "50" 3 "75" 4 "100" ;
VAL_ 1981 IndArflQntyFrtLtOtbrdOtltSet 0 "0" 1 "25" 2 "50" 3 "75" 4 "100" ;
VAL_ 1981 IndArflQntyRrRtInbrdOtltSet 0 "0" 1 "25" 2 "50" 3 "75" 4 "100" ;
VAL_ 1981 IndArflQntyRrLtInbrdOtltSet 0 "0" 1 "25" 2 "50" 3 "75" 4 "100" ;
VAL_ 1981 IndWprPrkDcr 0 "Off" 1 "On" ;
